VERSION ""

NS_ :

BS_:

BU_: TBOX GW

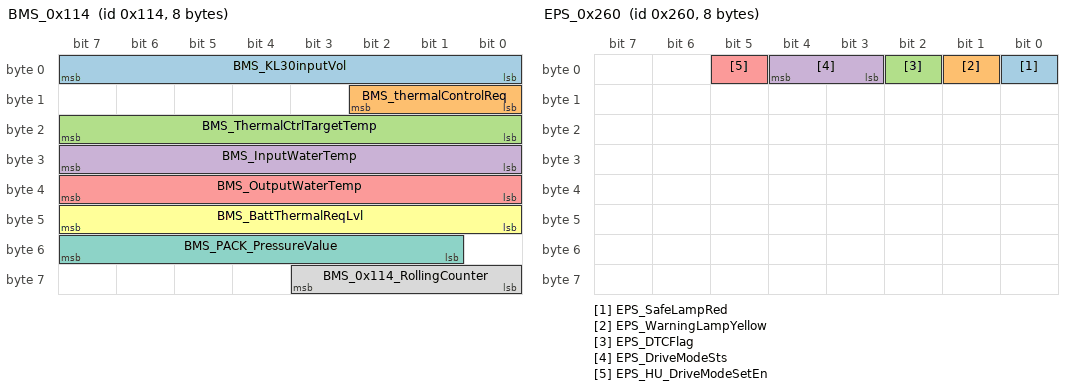
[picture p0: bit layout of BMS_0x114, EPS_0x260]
BO_ 276 BMS_0x114: 8 GW
 SG_ BMS_KL30inputVol : 7|8@0+ (0.1,0) [0|25.5] "V" TBOX
 SG_ BMS_thermalControlReq : 10|3@0+ (1,0) [0|7] "" TBOX
 SG_ BMS_ThermalCtrlTargetTemp : 23|8@0+ (1,-40) [-40|85] "℃" TBOX
 SG_ BMS_InputWaterTemp : 31|8@0+ (0.5,-40) [-40|85] "℃" TBOX
 SG_ BMS_OutputWaterTemp : 39|8@0+ (0.5,-40) [-40|85] "℃" TBOX
 SG_ BMS_BattThermalReqLvl : 47|8@0+ (1,0) [0|15] "" TBOX
 SG_ BMS_PACK_PressureValue : 55|7@0+ (1,50) [50|175] "Kpa" TBOX
 SG_ BMS_0x114_RollingCounter : 59|4@0+ (1,0) [0|15] "" TBOX

BO_ 608 EPS_0x260: 8 GW
 SG_ EPS_SafeLampRed : 0|1@0+ (1,0) [0|1] "" TBOX
 SG_ EPS_WarningLampYellow : 1|1@0+ (1,0) [0|1] "" TBOX
 SG_ EPS_DTCFlag : 2|1@0+ (1,0) [0|1] "" TBOX
 SG_ EPS_DriveModeSts : 4|2@0+ (1,0) [0|3] "" TBOX
 SG_ EPS_HU_DriveModeSetEn : 5|1@0+ (1,0) [0|1] "" TBOX

BO_ 375 EPS_0x177_APS: 8 GW
 SG_ Checksum_0x177 : 7|8@0+ (1,0) [0|255] "" TBOX
 SG_ EPS_EPSAPASts : 19|4@0+ (1,0) [0|15] "" TBOX
 SG_ EPS_EPSAPAInh : 31|8@0+ (1,0) [0|255] "" TBOX
 SG_ Rolling_counter_0x177 : 59|4@0+ (1,0) [0|15] "" TBOX

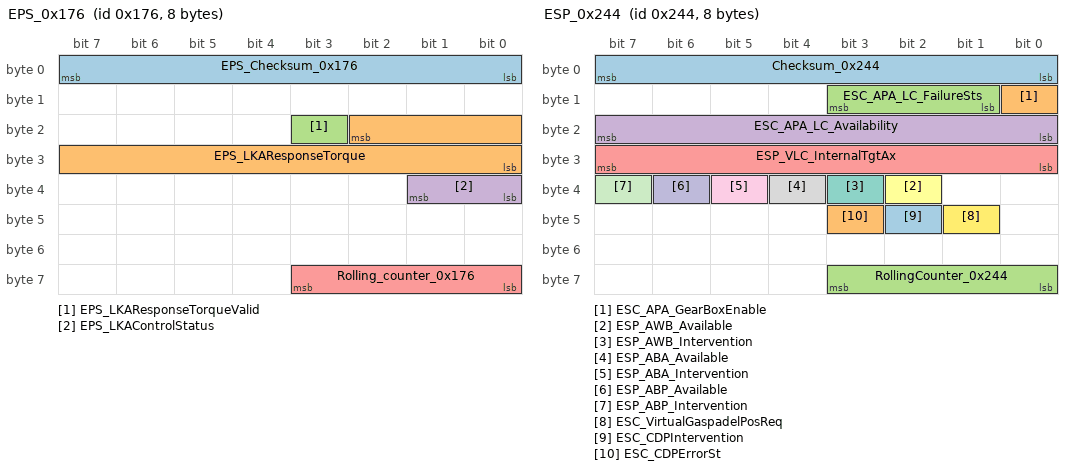
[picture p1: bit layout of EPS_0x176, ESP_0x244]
BO_ 374 EPS_0x176: 8 GW
 SG_ EPS_Checksum_0x176 : 7|8@0+ (1,0) [0|255] "" TBOX
 SG_ EPS_LKAResponseTorque : 18|11@0+ (0.01,-10.24) [-10.24|10.23] "Nm" TBOX
 SG_ EPS_LKAResponseTorqueValid : 19|1@0+ (1,0) [0|1] "" TBOX
 SG_ EPS_LKAControlStatus : 33|2@0+ (1,0) [0|3] "" TBOX
 SG_ Rolling_counter_0x176 : 59|4@0+ (1,0) [0|15] "" TBOX

BO_ 580 ESP_0x244: 8 GW
 SG_ Checksum_0x244 : 7|8@0+ (1,0) [0|255] "" TBOX
 SG_ ESC_APA_GearBoxEnable : 8|1@0+ (1,0) [0|1] "" Vector__XXX
 SG_ ESC_APA_LC_FailureSts : 11|3@0+ (1,0) [0|7] "" TBOX
 SG_ ESC_APA_LC_Availability : 23|8@0+ (1,0) [0|255] "" TBOX
 SG_ ESP_VLC_InternalTgtAx : 31|8@0+ (0.05,-7) [-7|5.75] "m/s2" TBOX
 SG_ ESP_AWB_Available : 34|1@0+ (1,0) [0|1] "" TBOX
 SG_ ESP_AWB_Intervention : 35|1@0+ (1,0) [0|1] "" TBOX
 SG_ ESP_ABA_Available : 36|1@0+ (1,0) [0|1] "" TBOX
 SG_ ESP_ABA_Intervention : 37|1@0+ (1,0) [0|1] "" TBOX
 SG_ ESP_ABP_Available : 38|1@0+ (1,0) [0|1] "" TBOX
 SG_ ESP_ABP_Intervention : 39|1@0+ (1,0) [0|1] "" TBOX
 SG_ ESC_VirtualGaspadelPosReq : 41|1@0+ (1,0) [0|1] "" TBOX
 SG_ ESC_CDPIntervention : 42|1@0+ (1,0) [0|1] "" TBOX
 SG_ ESC_CDPErrorSt : 43|1@0+ (1,0) [0|1] "" TBOX
 SG_ RollingCounter_0x244 : 59|4@0+ (1,0) [0|15] "" TBOX

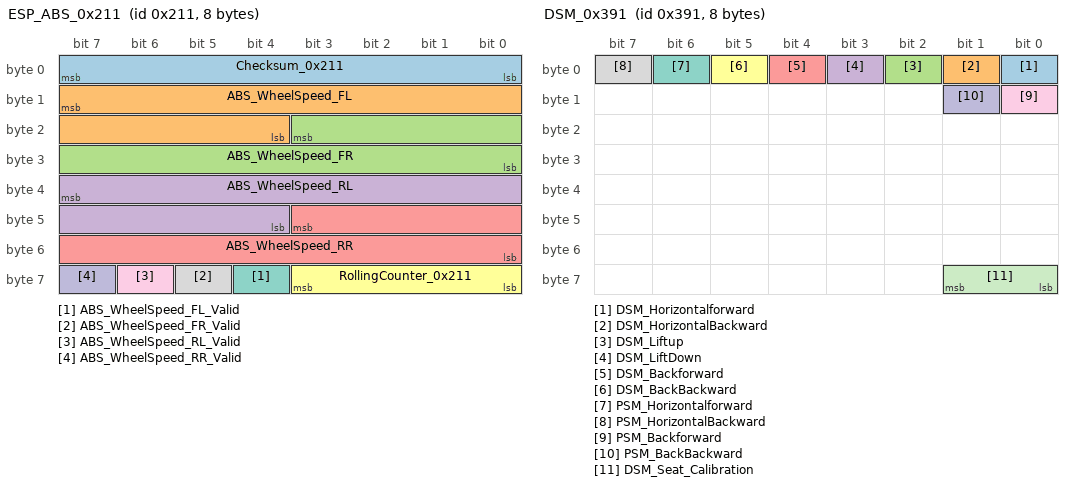
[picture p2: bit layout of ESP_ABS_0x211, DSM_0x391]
BO_ 529 ESP_ABS_0x211: 8 GW
 SG_ Checksum_0x211 : 7|8@0+ (1,0) [0|255] "" TBOX
 SG_ ABS_WheelSpeed_FL : 15|12@0+ (0.05625,0) [0|230.2875] "kph" TBOX
 SG_ ABS_WheelSpeed_FR : 19|12@0+ (0.05625,0) [0|230.2875] "kph" TBOX
 SG_ ABS_WheelSpeed_RL : 39|12@0+ (0.05625,0) [0|230.2875] "kph" TBOX
 SG_ ABS_WheelSpeed_RR : 43|12@0+ (0.05625,0) [0|230.2875] "kph" TBOX
 SG_ RollingCounter_0x211 : 59|4@0+ (1,0) [0|15] "" TBOX
 SG_ ABS_WheelSpeed_FL_Valid : 60|1@0+ (1,0) [0|1] "" TBOX
 SG_ ABS_WheelSpeed_FR_Valid : 61|1@0+ (1,0) [0|1] "" TBOX
 SG_ ABS_WheelSpeed_RL_Valid : 62|1@0+ (1,0) [0|1] "" TBOX
 SG_ ABS_WheelSpeed_RR_Valid : 63|1@0+ (1,0) [0|1] "" TBOX

BO_ 913 DSM_0x391: 8 GW
 SG_ DSM_Horizontalforward : 0|1@0+ (1,0) [0|1] "" TBOX
 SG_ DSM_HorizontalBackward : 1|1@0+ (1,0) [0|1] "" TBOX
 SG_ DSM_Liftup : 2|1@0+ (1,0) [0|1] "" TBOX
 SG_ DSM_LiftDown : 3|1@0+ (1,0) [0|1] "" TBOX
 SG_ DSM_Backforward : 4|1@0+ (1,0) [0|1] "" TBOX
 SG_ DSM_BackBackward : 5|1@0+ (1,0) [0|1] "" TBOX
 SG_ PSM_Horizontalforward : 6|1@0+ (1,0) [0|1] "" TBOX
 SG_ PSM_HorizontalBackward : 7|1@0+ (1,0) [0|1] "" TBOX
 SG_ PSM_Backforward : 8|1@0+ (1,0) [0|1] "" TBOX
 SG_ PSM_BackBackward : 9|1@0+ (1,0) [0|1] "" TBOX
 SG_ DSM_Seat_Calibration : 57|2@0+ (1,0) [0|3] "" TBOX

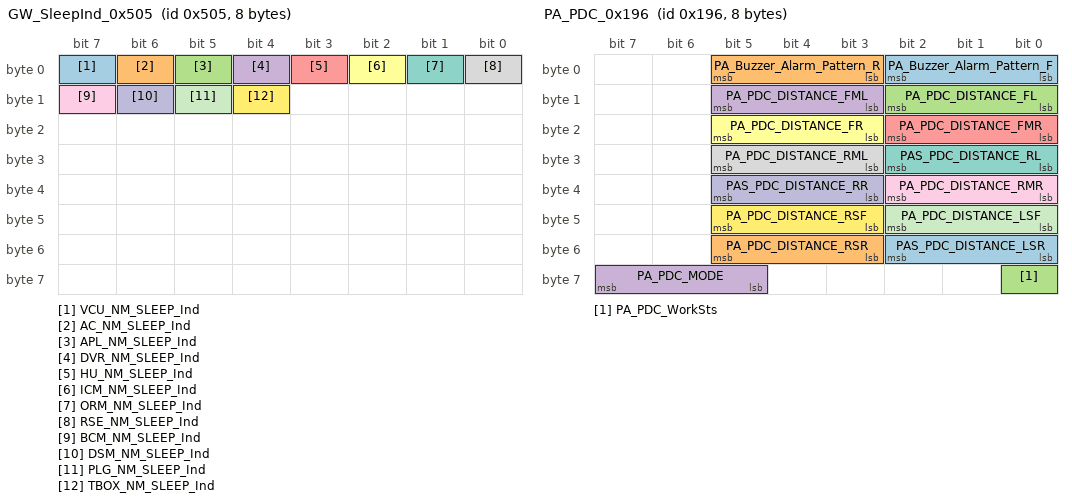
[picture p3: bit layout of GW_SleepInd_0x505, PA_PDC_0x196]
BO_ 1285 GW_SleepInd_0x505: 8 GW
 SG_ VCU_NM_SLEEP_Ind : 7|1@0+ (1,0) [0|1] "" TBOX
 SG_ AC_NM_SLEEP_Ind : 6|1@0+ (1,0) [0|1] "" TBOX
 SG_ APL_NM_SLEEP_Ind : 5|1@0+ (1,0) [0|1] "" TBOX
 SG_ DVR_NM_SLEEP_Ind : 4|1@0+ (1,0) [0|1] "" TBOX
 SG_ HU_NM_SLEEP_Ind : 3|1@0+ (1,0) [0|1] "" TBOX
 SG_ ICM_NM_SLEEP_Ind : 2|1@0+ (1,0) [0|1] "" TBOX
 SG_ ORM_NM_SLEEP_Ind : 1|1@0+ (1,0) [0|1] "" TBOX
 SG_ RSE_NM_SLEEP_Ind : 0|1@0+ (1,0) [0|1] "" TBOX
 SG_ BCM_NM_SLEEP_Ind : 15|1@0+ (1,0) [0|1] "" TBOX
 SG_ DSM_NM_SLEEP_Ind : 14|1@0+ (1,0) [0|1] "" TBOX
 SG_ PLG_NM_SLEEP_Ind : 13|1@0+ (1,0) [0|1] "" TBOX
 SG_ TBOX_NM_SLEEP_Ind : 12|1@0+ (1,0) [0|1] "" TBOX

BO_ 406 PA_PDC_0x196: 8 GW
 SG_ PA_Buzzer_Alarm_Pattern_F : 2|3@0+ (1,0) [0|7] "" TBOX
 SG_ PA_Buzzer_Alarm_Pattern_R : 5|3@0+ (1,0) [0|7] "" TBOX
 SG_ PA_PDC_DISTANCE_FL : 10|3@0+ (1,0) [0|7] "" TBOX
 SG_ PA_PDC_DISTANCE_FML : 13|3@0+ (1,0) [0|7] "" TBOX
 SG_ PA_PDC_DISTANCE_FMR : 18|3@0+ (1,0) [0|7] "" TBOX
 SG_ PA_PDC_DISTANCE_FR : 21|3@0+ (1,0) [0|7] "" TBOX
 SG_ PAS_PDC_DISTANCE_RL : 26|3@0+ (1,0) [0|7] "" TBOX
 SG_ PA_PDC_DISTANCE_RML : 29|3@0+ (1,0) [0|7] "" TBOX
 SG_ PA_PDC_DISTANCE_RMR : 34|3@0+ (1,0) [0|7] "" TBOX
 SG_ PAS_PDC_DISTANCE_RR : 37|3@0+ (1,0) [0|7] "" TBOX
 SG_ PA_PDC_DISTANCE_LSF : 42|3@0+ (1,0) [0|7] "" TBOX
 SG_ PA_PDC_DISTANCE_RSF : 45|3@0+ (1,0) [0|7] "" TBOX
 SG_ PAS_PDC_DISTANCE_LSR : 50|3@0+ (1,0) [0|7] "" TBOX
 SG_ PA_PDC_DISTANCE_RSR : 53|3@0+ (1,0) [0|7] "" TBOX
 SG_ PA_PDC_WorkSts : 56|1@0+ (1,0) [0|1] "" TBOX
 SG_ PA_PDC_MODE : 63|3@0+ (1,0) [0|7] "" TBOX

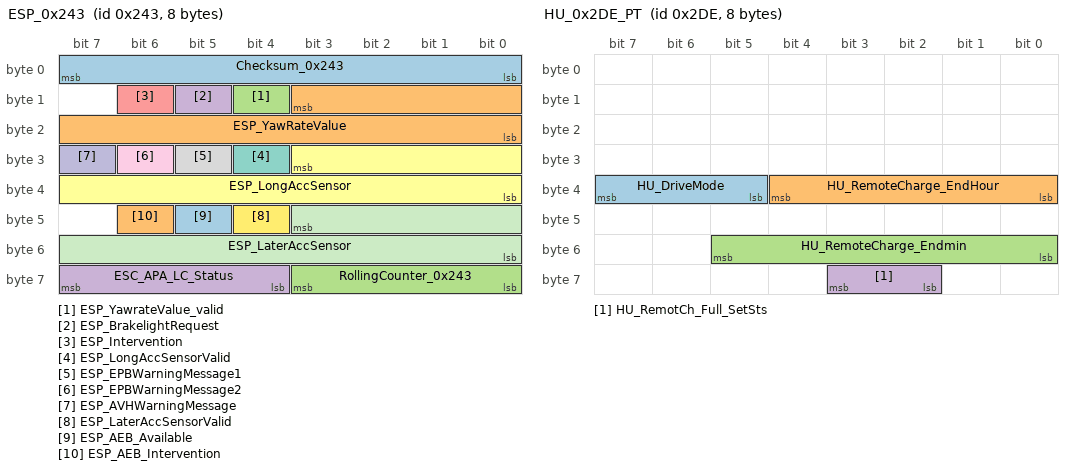
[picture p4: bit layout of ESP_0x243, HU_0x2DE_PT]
BO_ 579 ESP_0x243: 8 GW
 SG_ Checksum_0x243 : 7|8@0+ (1,0) [0|255] "" TBOX
 SG_ ESP_YawRateValue : 11|12@0+ (0.05,-75) [-75|75] "°/s" TBOX
 SG_ ESP_YawrateValue_valid : 12|1@0+ (1,0) [0|1] "" TBOX
 SG_ ESP_BrakelightRequest : 13|1@0+ (1,0) [0|1] "" TBOX
 SG_ ESP_Intervention : 14|1@0+ (1,0) [0|1] "" TBOX
 SG_ ESP_LongAccSensor : 27|12@0+ (0.01,-20) [-20|20] "m/s^2" TBOX
 SG_ ESP_LongAccSensorValid : 28|1@0+ (1,0) [0|1] "" TBOX
 SG_ ESP_EPBWarningMessage1 : 29|1@0+ (1,0) [0|1] "" TBOX
 SG_ ESP_EPBWarningMessage2 : 30|1@0+ (1,0) [0|1] "" TBOX
 SG_ ESP_AVHWarningMessage : 31|1@0+ (1,0) [0|1] "" TBOX
 SG_ ESP_LaterAccSensor : 43|12@0+ (0.01,-20) [-20|20] "m/s^2" TBOX
 SG_ ESP_LaterAccSensorValid : 44|1@0+ (1,0) [0|1] "" TBOX
 SG_ ESP_AEB_Available : 45|1@0+ (1,0) [0|1] "" TBOX
 SG_ ESP_AEB_Intervention : 46|1@0+ (1,0) [0|1] "" TBOX
 SG_ RollingCounter_0x243 : 59|4@0+ (1,0) [0|15] "" TBOX
 SG_ ESC_APA_LC_Status : 63|4@0+ (1,0) [0|15] "" TBOX

BO_ 734 HU_0x2DE_PT: 8 GW
 SG_ HU_DriveMode : 39|3@0+ (1,0) [0|7] "" TBOX
 SG_ HU_RemoteCharge_EndHour : 36|5@0+ (1,0) [0|23] "hour" TBOX
 SG_ HU_RemoteCharge_Endmin : 53|6@0+ (1,0) [0|59] "min" TBOX
 SG_ HU_RemotCh_Full_SetSts : 59|2@0+ (1,0) [0|3] "" TBOX

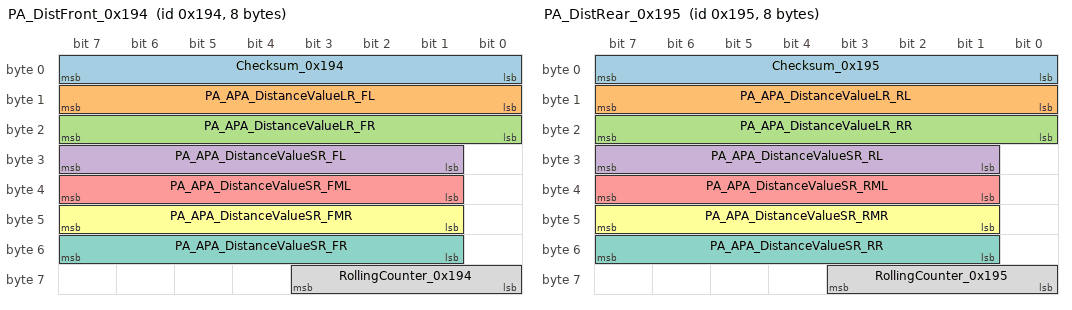
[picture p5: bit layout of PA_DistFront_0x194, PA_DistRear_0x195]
BO_ 404 PA_DistFront_0x194: 8 GW
 SG_ Checksum_0x194 : 7|8@0+ (1,0) [0|255] "" TBOX
 SG_ PA_APA_DistanceValueLR_FL : 15|8@0+ (2,0) [0|500] "cm" TBOX
 SG_ PA_APA_DistanceValueLR_FR : 23|8@0+ (2,0) [0|500] "cm" TBOX
 SG_ PA_APA_DistanceValueSR_FL : 31|7@0+ (2,0) [0|250] "cm" TBOX
 SG_ PA_APA_DistanceValueSR_FML : 39|7@0+ (2,0) [0|250] "cm" TBOX
 SG_ PA_APA_DistanceValueSR_FMR : 47|7@0+ (2,0) [0|250] "cm" TBOX
 SG_ PA_APA_DistanceValueSR_FR : 55|7@0+ (2,0) [0|250] "cm" TBOX
 SG_ RollingCounter_0x194 : 59|4@0+ (1,0) [0|15] "" TBOX

BO_ 405 PA_DistRear_0x195: 8 GW
 SG_ Checksum_0x195 : 7|8@0+ (1,0) [0|255] "" TBOX
 SG_ PA_APA_DistanceValueLR_RL : 15|8@0+ (2,0) [0|500] "cm" TBOX
 SG_ PA_APA_DistanceValueLR_RR : 23|8@0+ (2,0) [0|500] "cm" TBOX
 SG_ PA_APA_DistanceValueSR_RL : 31|7@0+ (2,0) [0|250] "cm" TBOX
 SG_ PA_APA_DistanceValueSR_RML : 39|7@0+ (2,0) [0|250] "cm" TBOX
 SG_ PA_APA_DistanceValueSR_RMR : 47|7@0+ (2,0) [0|250] "cm" TBOX
 SG_ PA_APA_DistanceValueSR_RR : 55|7@0+ (2,0) [0|250] "cm" TBOX
 SG_ RollingCounter_0x195 : 59|4@0+ (1,0) [0|15] "" TBOX

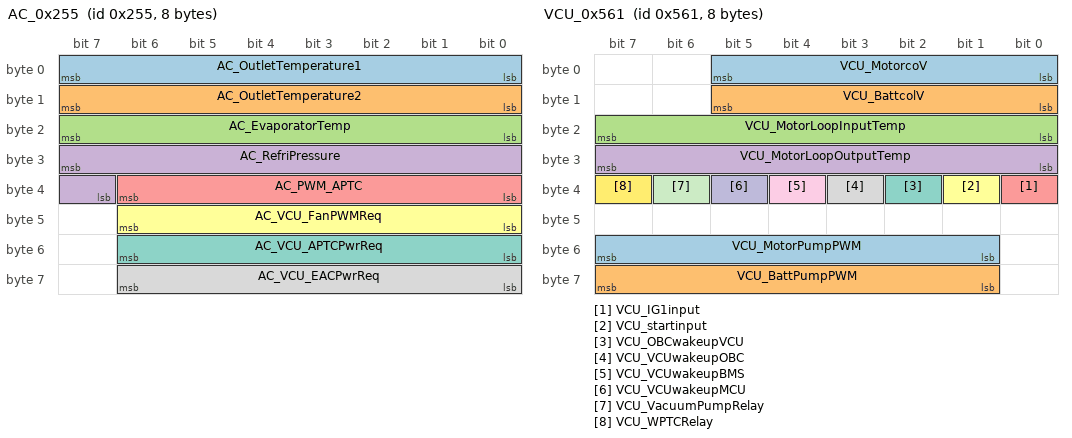
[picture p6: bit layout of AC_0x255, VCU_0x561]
BO_ 597 AC_0x255: 8 GW
 SG_ AC_OutletTemperature1 : 7|8@0+ (0.5,-40) [-40|80] "℃" TBOX
 SG_ AC_OutletTemperature2 : 15|8@0+ (0.5,-40) [-40|80] "℃" TBOX
 SG_ AC_EvaporatorTemp : 23|8@0+ (0.5,-40) [-40|80] "℃" TBOX
 SG_ AC_RefriPressure : 31|9@0+ (0.01,0) [0.1|3.5] "MPa" TBOX
 SG_ AC_PWM_APTC : 38|7@0+ (1,0) [0|100] "%" TBOX
 SG_ AC_VCU_FanPWMReq : 46|7@0+ (1,0) [0|100] "%" TBOX
 SG_ AC_VCU_APTCPwrReq : 54|7@0+ (0.1,0) [0|12.7] "" TBOX
 SG_ AC_VCU_EACPwrReq : 62|7@0+ (0.1,0) [0|12.7] "" TBOX

BO_ 64 BCM_PEPS_0x40: 8 GW
 SG_ PEPS_RKECommand : 3|4@0+ (1,0) [0|15] "" TBOX
 SG_ PEPS_DoorUnlockReq : 6|2@0+ (1,0) [0|3] "" TBOX
 SG_ PEPS_DoorlockReq : 9|2@0+ (1,0) [0|3] "" TBOX
 SG_ PEPS_TrunkReleaseReq : 4|1@0+ (1,0) [0|1] "" TBOX

BO_ 1377 VCU_0x561: 8 GW
 SG_ VCU_MotorcoV : 5|6@0+ (0.1,0) [0|6.3] "V" TBOX
 SG_ VCU_BattcolV : 13|6@0+ (0.1,0) [0|6.3] "V" TBOX
 SG_ VCU_MotorLoopInputTemp : 23|8@0+ (1,-40) [-40|215] "℃" TBOX
 SG_ VCU_MotorLoopOutputTemp : 31|8@0+ (1,-40) [-40|215] "℃" TBOX
 SG_ VCU_IG1input : 32|1@0+ (1,0) [0|1] "" TBOX
 SG_ VCU_startinput : 33|1@0+ (1,0) [0|1] "" TBOX
 SG_ VCU_OBCwakeupVCU : 34|1@0+ (1,0) [0|1] "" TBOX
 SG_ VCU_VCUwakeupOBC : 35|1@0+ (1,0) [0|1] "" TBOX
 SG_ VCU_VCUwakeupBMS : 36|1@0+ (1,0) [0|1] "" TBOX
 SG_ VCU_VCUwakeupMCU : 37|1@0+ (1,0) [0|1] "" TBOX
 SG_ VCU_VacuumPumpRelay : 38|1@0+ (1,0) [0|1] "" TBOX
 SG_ VCU_WPTCRelay : 39|1@0+ (1,0) [0|1] "" TBOX
 SG_ VCU_MotorPumpPWM : 55|7@0+ (1,0) [0|100] "%" TBOX
 SG_ VCU_BattPumpPWM : 63|7@0+ (1,0) [0|100] "%" TBOX

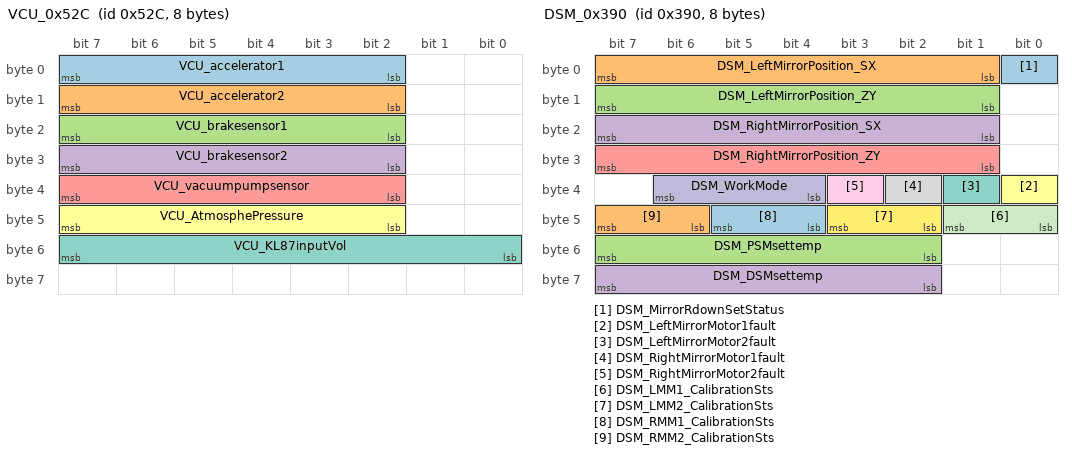
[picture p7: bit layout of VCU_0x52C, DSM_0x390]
BO_ 1324 VCU_0x52C: 8 GW
 SG_ VCU_accelerator1 : 7|6@0+ (0.1,0) [0|6.3] "V" TBOX
 SG_ VCU_accelerator2 : 15|6@0+ (0.1,0) [0|6.3] "V" TBOX
 SG_ VCU_brakesensor1 : 23|6@0+ (0.1,0) [0|6.3] "V" TBOX
 SG_ VCU_brakesensor2 : 31|6@0+ (0.1,0) [0|6.3] "V" TBOX
 SG_ VCU_vacuumpumpsensor : 39|6@0+ (0.1,0) [0|6.3] "V" TBOX
 SG_ VCU_AtmosphePressure : 47|6@0+ (0.1,0) [0|6.3] "V" TBOX
 SG_ VCU_KL87inputVol : 55|8@0+ (0.1,0) [0|25.4] "V" TBOX

BO_ 912 DSM_0x390: 8 GW
 SG_ DSM_MirrorRdownSetStatus : 0|1@0+ (1,0) [0|1] "" TBOX
 SG_ DSM_LeftMirrorPosition_SX : 7|7@0+ (1,0) [0|100] "%" TBOX
 SG_ DSM_LeftMirrorPosition_ZY : 15|7@0+ (1,0) [0|100] "%" TBOX
 SG_ DSM_RightMirrorPosition_SX : 23|7@0+ (1,0) [0|100] "%" TBOX
 SG_ DSM_RightMirrorPosition_ZY : 31|7@0+ (1,0) [0|100] "%" TBOX
 SG_ DSM_LeftMirrorMotor1fault : 32|1@0+ (1,0) [0|1] "" TBOX
 SG_ DSM_LeftMirrorMotor2fault : 33|1@0+ (1,0) [0|1] "" TBOX
 SG_ DSM_RightMirrorMotor1fault : 34|1@0+ (1,0) [0|1] "" TBOX
 SG_ DSM_RightMirrorMotor2fault : 35|1@0+ (1,0) [0|1] "" TBOX
 SG_ DSM_WorkMode : 38|3@0+ (1,0) [0|7] "" TBOX
 SG_ DSM_LMM1_CalibrationSts : 41|2@0+ (1,0) [0|3] "" TBOX
 SG_ DSM_LMM2_CalibrationSts : 43|2@0+ (1,0) [0|3] "" TBOX
 SG_ DSM_RMM1_CalibrationSts : 45|2@0+ (1,0) [0|3] "" TBOX
 SG_ DSM_RMM2_CalibrationSts : 47|2@0+ (1,0) [0|3] "" TBOX
 SG_ DSM_PSMsettemp : 55|6@0+ (1,0) [34|42] "℃" TBOX
 SG_ DSM_DSMsettemp : 63|6@0+ (1,0) [34|42] "℃" TBOX

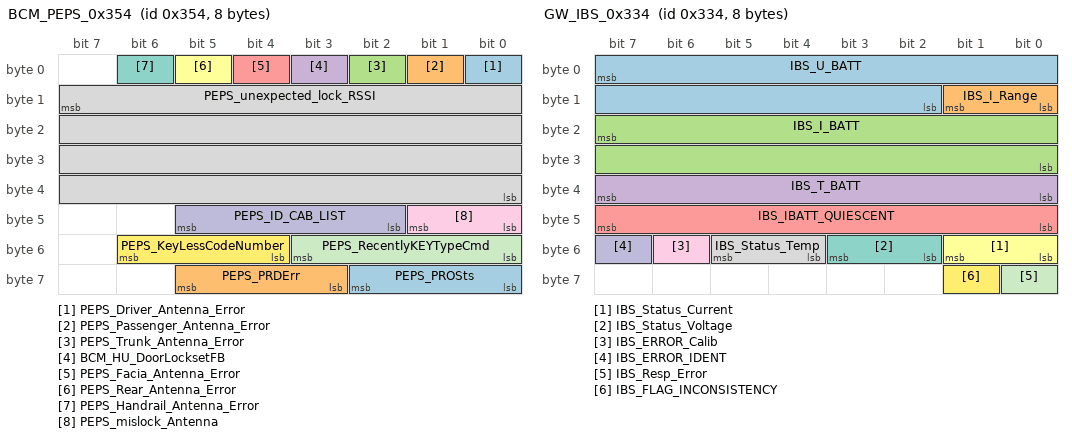
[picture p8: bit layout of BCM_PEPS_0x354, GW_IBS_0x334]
BO_ 852 BCM_PEPS_0x354: 8 GW
 SG_ PEPS_Driver_Antenna_Error : 0|1@0+ (1,0) [0|1] "" TBOX
 SG_ PEPS_Passenger_Antenna_Error : 1|1@0+ (1,0) [0|1] "" TBOX
 SG_ PEPS_Trunk_Antenna_Error : 2|1@0+ (1,0) [0|1] "" TBOX
 SG_ BCM_HU_DoorLocksetFB : 3|1@0+ (1,0) [0|1] "" TBOX
 SG_ PEPS_Facia_Antenna_Error : 4|1@0+ (1,0) [0|1] "" TBOX
 SG_ PEPS_Rear_Antenna_Error : 5|1@0+ (1,0) [0|1] "" TBOX
 SG_ PEPS_Handrail_Antenna_Error : 6|1@0+ (1,0) [0|1] "" TBOX
 SG_ PEPS_unexpected_lock_RSSI : 15|32@0+ (1,0) [0|4294967294] "" TBOX
 SG_ PEPS_mislock_Antenna : 41|2@0+ (1,0) [0|3] "" TBOX
 SG_ PEPS_ID_CAB_LIST : 45|4@0+ (1,0) [0|15] "" TBOX
 SG_ PEPS_RecentlyKEYTypeCmd : 51|4@0+ (1,0) [0|15] "" TBOX
 SG_ PEPS_KeyLessCodeNumber : 54|3@0+ (1,0) [0|7] "" TBOX
 SG_ PEPS_PROSts : 58|3@0+ (1,0) [0|1] "" TBOX
 SG_ PEPS_PRDErr : 61|3@0+ (1,0) [0|1] "" TBOX

BO_ 546 BCM_PEPS_0x222: 8 GW
 SG_ PEPS_PEPSFailStatus : 0|1@0+ (1,0) [0|1] "" TBOX
 SG_ PEPS_WarningKeyNotInCar : 1|1@0+ (1,0) [0|1] "" TBOX
 SG_ PEPS_WarningKeyInCar : 2|1@0+ (1,0) [0|1] "" TBOX
 SG_ PEPS_WarningIgNotOff : 3|1@0+ (1,0) [0|1] "" TBOX
 SG_ PEPS_WarningKeyLowBattery : 4|1@0+ (1,0) [0|1] "" TBOX
 SG_ PEPS_WarningStartupNotBrake : 5|1@0+ (1,0) [0|1] "" TBOX
 SG_ PEPS_WarningKeyNearbyIMMO : 7|1@0+ (1,0) [0|1] "" TBOX
 SG_ PEPS_PassiveWindowCom : 8|1@0+ (1,0) [0|1] "" TBOX
 SG_ PEPS_BackDoorKeyState : 10|2@0+ (1,0) [0|3] "" TBOX
 SG_ PEPS_KeyPosition : 12|2@0+ (1,0) [0|3] "" TBOX
 SG_ PEPS_HandshakeFail : 18|3@0+ (1,0) [0|7] "" TBOX
 SG_ PEPS_Authpasstype : 25|2@0+ (1,0) [0|3] "" TBOX
 SG_ PEPS_EnableWirelessCharging : 26|1@0+ (1,0) [0|1] "" TBOX
 SG_ PEPS_DHA_LeftHandleSwitch : 33|2@0+ (1,0) [0|3] "" TBOX
 SG_ PEPS_PHA_RightHandleSwitch : 35|2@0+ (1,0) [0|3] "" TBOX
 SG_ DHA_LockFlag : 47|8@0+ (1,0) [0|255] "" TBOX
 SG_ PHA_LockFlag : 55|8@0+ (1,0) [0|255] "" TBOX

BO_ 820 GW_IBS_0x334: 8 GW
 SG_ IBS_U_BATT : 7|14@0+ (0.0009765625,3) [3|18] "V" TBOX
 SG_ IBS_I_Range : 9|2@0+ (1,0) [0|3] "" TBOX
 SG_ IBS_I_BATT : 23|16@0+ (1,-32768) [-32768|32766] "A" TBOX
 SG_ IBS_T_BATT : 39|8@0+ (1,-40) [-40|105] "°C" TBOX
 SG_ IBS_IBATT_QUIESCENT : 47|8@0+ (0.00390625,0) [0|0.984375] "A" TBOX
 SG_ IBS_Status_Current : 49|2@0+ (1,0) [0|3] "" TBOX
 SG_ IBS_Status_Voltage : 51|2@0+ (1,0) [0|3] "" TBOX
 SG_ IBS_Status_Temp : 53|2@0+ (1,0) [0|3] "" TBOX
 SG_ IBS_ERROR_Calib : 54|1@0+ (1,0) [0|1] "" TBOX
 SG_ IBS_ERROR_IDENT : 55|1@0+ (1,0) [0|1] "" TBOX
 SG_ IBS_Resp_Error : 56|1@0+ (1,0) [0|1] "" TBOX
 SG_ IBS_FLAG_INCONSISTENCY : 57|1@0+ (1,0) [0|1] "" TBOX

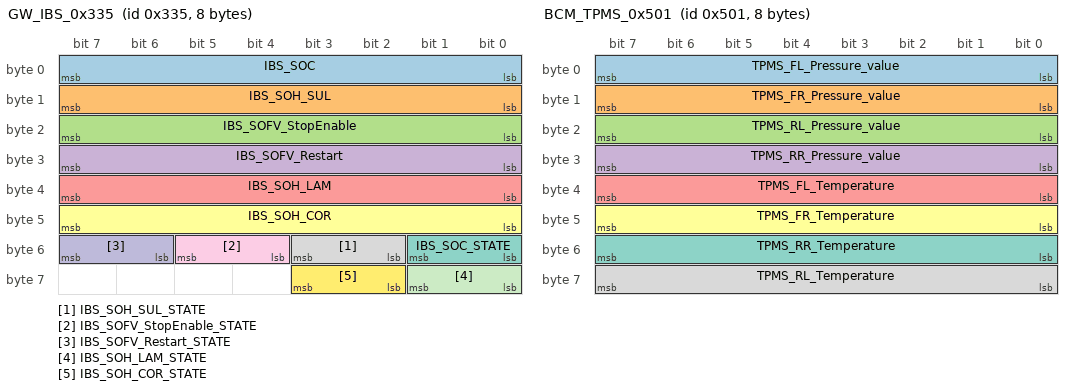
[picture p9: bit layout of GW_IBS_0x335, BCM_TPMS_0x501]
BO_ 821 GW_IBS_0x335: 8 GW
 SG_ IBS_SOC : 7|8@0+ (1,0) [0|100] "%" TBOX
 SG_ IBS_SOH_SUL : 15|8@0+ (1,0) [0|100] "%" TBOX
 SG_ IBS_SOFV_StopEnable : 23|8@0+ (0.0625,0) [0|15.875] "V" TBOX
 SG_ IBS_SOFV_Restart : 31|8@0+ (0.0625,0) [0|15.875] "V" TBOX
 SG_ IBS_SOH_LAM : 39|8@0+ (0.5,0) [0|127] "Ah" TBOX
 SG_ IBS_SOH_COR : 47|8@0+ (0.0625,0) [0|15.875] "V" TBOX
 SG_ IBS_SOC_STATE : 49|2@0+ (1,0) [0|3] "" TBOX
 SG_ IBS_SOH_SUL_STATE : 51|2@0+ (1,0) [0|3] "" TBOX
 SG_ IBS_SOFV_StopEnable_STATE : 53|2@0+ (1,0) [0|3] "" TBOX
 SG_ IBS_SOFV_Restart_STATE : 55|2@0+ (1,0) [0|3] "" TBOX
 SG_ IBS_SOH_LAM_STATE : 57|2@0+ (1,0) [0|3] "" TBOX
 SG_ IBS_SOH_COR_STATE : 59|2@0+ (1,0) [0|3] "" TBOX

BO_ 933 HU_0x3A5: 8 GW
 SG_ HU_LanguageSet : 3|4@0+ (1,0) [0|15] "" TBOX
 SG_ HU_TimeSet_DisplayMode : 4|1@0+ (1,0) [0|1] "" TBOX
 SG_ HU_TimeSet_AutoMode : 5|1@0+ (1,0) [0|1] "" TBOX
 SG_ HU_TBOXwelcomeReq_set : 7|2@0+ (1,0) [0|3] "" TBOX
 SG_ HU_TimeSet_Hour : 12|5@0+ (1,0) [0|31] "" TBOX
 SG_ HU_MCUPowerState : 15|3@0+ (1,0) [0|7] "" TBOX
 SG_ HU_TimeSet_Minutes : 21|6@0+ (1,0) [0|60] "" TBOX
 SG_ HU_SOCResetType : 22|1@0+ (1,0) [0|1] "" TBOX
 SG_ HU_HardACCState : 23|1@0+ (1,0) [0|1] "" TBOX
 SG_ HU_TBOX_Reboot : 25|2@0+ (1,0) [0|3] "" TBOX
 SG_ HU_mute_activests : 26|1@0+ (1,0) [0|1] "" TBOX
 SG_ HU_Voicecontrol_activests : 27|1@0+ (1,0) [0|1] "" TBOX
 SG_ HU_SOCWatchdog : 28|1@0+ (1,0) [0|1] "" TBOX
 SG_ HU_phonecall_worksts : 29|1@0+ (1,0) [0|1] "" TBOX
 SG_ HU_ICM_INFO_Enable : 31|2@0+ (1,0) [0|3] "" TBOX
 SG_ HU_BCMSystemPowerMode : 33|2@0+ (1,0) [0|3] "" TBOX
 SG_ HU_RemoteCharge_StartHour : 39|5@0+ (1,0) [0|23] "" TBOX
 SG_ HU_RemoteCharge_Startmin : 45|6@0+ (1,0) [0|59] "" TBOX
 SG_ HU_RemoteCharge_Set : 47|2@0+ (1,0) [0|3] "" TBOX
 SG_ HU_ChargeCtrl_Set : 49|2@0+ (1,0) [0|3] "" TBOX
 SG_ HU_BatteryVoltage : 55|5@0+ (1,0) [0|25] "" TBOX
 SG_ HU_SPIConnectState : 56|1@0+ (1,0) [0|1] "" TBOX
 SG_ HU_MCUResetReason : 63|7@0+ (2,0) [0|127] "" TBOX

BO_ 816 BCM_0x330: 8 GW
 SG_ BCM_reversingLampSW : 0|1@0+ (1,0) [0|1] "" TBOX
 SG_ BCM_CarpetlampSW : 3|1@0+ (1,0) [0|1] "" TBOX
 SG_ BCM_CarpetlampSWSetsts : 4|1@0+ (1,0) [0|1] "" TBOX
 SG_ BCM_FrontdecoralampSW : 7|1@0+ (1,0) [0|1] "" TBOX
 SG_ BCM_LeftReadlampControl : 9|1@0+ (1,0) [0|1] "" TBOX
 SG_ BCM_RightReadlampControl : 11|1@0+ (1,0) [0|1] "" TBOX
 SG_ BCM_FloodlightControl : 13|1@0+ (1,0) [0|1] "" TBOX
 SG_ BCM_DomeLampDoorControl : 15|1@0+ (1,0) [0|1] "" TBOX
 SG_ BCM_LockWelcomeSts : 17|2@0+ (1,0) [0|3] "" TBOX
 SG_ BCM_PEPSLockReason : 20|3@0+ (1,0) [0|7] "" TBOX
 SG_ BCM_PEPSUnLockReason : 23|3@0+ (1,0) [0|7] "" TBOX
 SG_ BCM_FollowMeControlsts : 27|1@0+ (1,0) [0|1] "" TBOX
 SG_ BCM_FollowMeDelayTSetsts : 29|2@0+ (1,0) [0|3] "" TBOX
 SG_ BCM_AutoLockSetsts : 31|1@0+ (1,0) [0|1] "" TBOX
 SG_ BCM_WindowAutoUPSetsts : 33|1@0+ (1,0) [0|1] "" TBOX
 SG_ BCM_FL_LED_Error : 34|1@0+ (1,0) [0|1] "" TBOX
 SG_ BCM_FR_LED_Error : 35|1@0+ (1,0) [0|1] "" TBOX
 SG_ BCM_RL_LED_Error : 36|1@0+ (1,0) [0|1] "" TBOX
 SG_ BCM_RR_LED_Error : 37|1@0+ (1,0) [0|1] "" TBOX
 SG_ BCM_LockReason : 50|3@0+ (1,0) [0|7] "" TBOX
 SG_ BCM_UnLockReason : 53|3@0+ (1,0) [0|7] "" TBOX
 SG_ BCM_CSW_SSB_inputSts : 54|1@0+ (1,0) [0|1] "" TBOX
 SG_ BCM_ACU_Crash_inputsts : 55|1@0+ (1,0) [0|1] "" TBOX
 SG_ BCM_ESCL_UnlockFB_inputsts : 56|1@0+ (1,0) [0|1] "" TBOX
 SG_ BCM_ESCL_Motorpower_outputsts : 57|1@0+ (1,0) [0|1] "" TBOX
 SG_ BCM_ESCL_LockEnable_outputsts : 58|1@0+ (1,0) [0|1] "" TBOX
 SG_ BCM_ESCL_UnLockfail : 59|1@0+ (1,0) [0|1] "" TBOX
 SG_ BCM_ESCL_Lockfail : 60|1@0+ (1,0) [0|1] "" TBOX
 SG_ BCM_waterlightlimit : 61|1@0+ (1,0) [0|1] "" TBOX

BO_ 961 TBOX_0x3C1: 8 TBOX
 SG_ Tbox_ICM_ODOTotal : 7|24@0+ (1,0) [0|999999] "KM" GW
 SG_ Tbox_ICM_Prevmaintmileage : 31|24@0+ (1,0) [0|999999] "KM" GW

BO_ 1281 BCM_TPMS_0x501: 8 GW
 SG_ TPMS_FL_Pressure_value : 7|8@0+ (1.373,0) [0|348.742] "kPa" TBOX
 SG_ TPMS_FR_Pressure_value : 15|8@0+ (1.373,0) [0|348.742] "kPa" TBOX
 SG_ TPMS_RL_Pressure_value : 23|8@0+ (1.373,0) [0|348.742] "kPa" TBOX
 SG_ TPMS_RR_Pressure_value : 31|8@0+ (1.373,0) [0|348.742] "kPa" TBOX
 SG_ TPMS_FL_Temperature : 39|8@0+ (1,-60) [-60|194] "℃" TBOX
 SG_ TPMS_FR_Temperature : 47|8@0+ (1,-60) [-60|194] "℃" TBOX
 SG_ TPMS_RR_Temperature : 55|8@0+ (1,-60) [-60|194] "℃" TBOX
 SG_ TPMS_RL_Temperature : 63|8@0+ (1,-60) [-60|194] "℃" TBOX

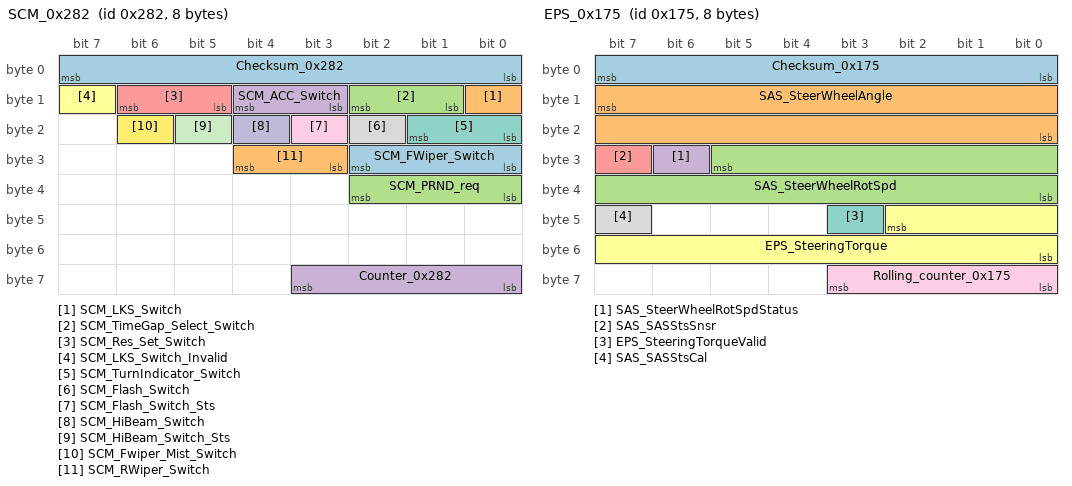
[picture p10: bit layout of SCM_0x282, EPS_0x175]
BO_ 642 SCM_0x282: 8 GW
 SG_ Checksum_0x282 : 7|8@0+ (1,0) [0|255] "" TBOX
 SG_ SCM_LKS_Switch : 8|1@0+ (1,0) [0|1] "" TBOX
 SG_ SCM_TimeGap_Select_Switch : 10|2@0+ (1,0) [0|3] "" TBOX
 SG_ SCM_ACC_Switch : 12|2@0+ (1,0) [0|3] "" TBOX
 SG_ SCM_Res_Set_Switch : 14|2@0+ (1,0) [0|3] "" TBOX
 SG_ SCM_LKS_Switch_Invalid : 15|1@0+ (1,0) [0|1] "" TBOX
 SG_ SCM_TurnIndicator_Switch : 17|2@0+ (1,0) [0|3] "" TBOX
 SG_ SCM_Flash_Switch : 18|1@0+ (1,0) [0|1] "" TBOX
 SG_ SCM_Flash_Switch_Sts : 19|1@0+ (1,0) [0|1] "" TBOX
 SG_ SCM_HiBeam_Switch : 20|1@0+ (1,0) [0|1] "" TBOX
 SG_ SCM_HiBeam_Switch_Sts : 21|1@0+ (1,0) [0|1] "" TBOX
 SG_ SCM_Fwiper_Mist_Switch : 22|1@0+ (1,0) [0|1] "" TBOX
 SG_ SCM_FWiper_Switch : 26|3@0+ (1,0) [0|7] "" TBOX
 SG_ SCM_RWiper_Switch : 28|2@0+ (1,0) [0|3] "" TBOX
 SG_ SCM_PRND_req : 34|3@0+ (1,0) [0|7] "" TBOX
 SG_ Counter_0x282 : 59|4@0+ (1,0) [0|15] "" TBOX

BO_ 373 EPS_0x175: 8 GW
 SG_ Checksum_0x175 : 7|8@0+ (1,0) [0|255] "" TBOX
 SG_ SAS_SteerWheelAngle : 15|16@0+ (0.0238,-780) [-780|779.733] "deg" TBOX
 SG_ SAS_SteerWheelRotSpd : 29|14@0+ (0.125,-1024) [-1024|1023.75] "deg/s" TBOX
 SG_ SAS_SteerWheelRotSpdStatus : 30|1@0+ (1,0) [0|1] "" TBOX
 SG_ SAS_SASStsSnsr : 31|1@0+ (1,0) [0|1] "" TBOX
 SG_ EPS_SteeringTorque : 42|11@0+ (0.01,-10.24) [-10.24|10.23] "Nm" TBOX
 SG_ EPS_SteeringTorqueValid : 43|1@0+ (1,0) [0|1] "" TBOX
 SG_ SAS_SASStsCal : 47|1@0+ (1,0) [0|1] "" TBOX
 SG_ Rolling_counter_0x175 : 59|4@0+ (1,0) [0|15] "" TBOX

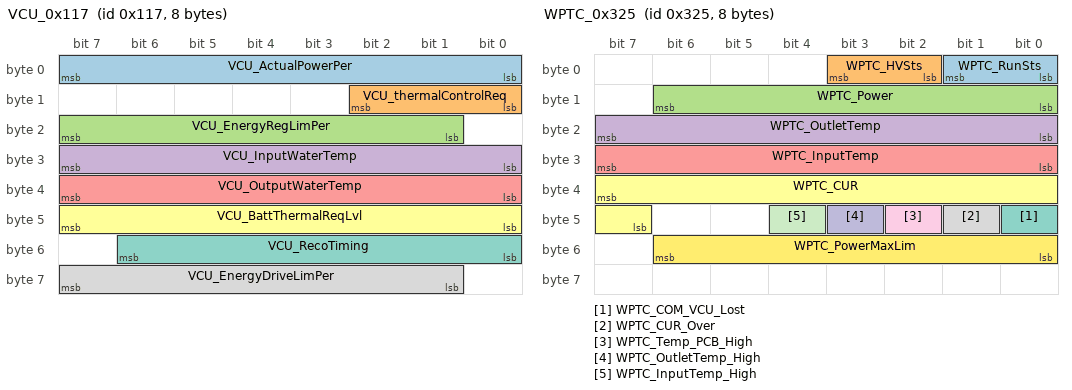
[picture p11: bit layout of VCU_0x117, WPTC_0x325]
BO_ 279 VCU_0x117: 8 GW
 SG_ VCU_ActualPowerPer : 7|8@0+ (1,-100) [-100|100] "" TBOX
 SG_ VCU_thermalControlReq : 10|3@0+ (1,0) [0|7] "" TBOX
 SG_ VCU_EnergyRegLimPer : 23|7@0+ (1,0) [0|100] "" TBOX
 SG_ VCU_InputWaterTemp : 31|8@0+ (0.5,-40) [-40|85] "℃" TBOX
 SG_ VCU_OutputWaterTemp : 39|8@0+ (0.5,-40) [-40|85] "℃" TBOX
 SG_ VCU_BattThermalReqLvl : 47|8@0+ (1,0) [0|15] "" TBOX
 SG_ VCU_RecoTiming : 54|7@0+ (1,0) [0|120] "" TBOX
 SG_ VCU_EnergyDriveLimPer : 63|7@0+ (1,0) [0|100] "" TBOX

BO_ 1424 BMS_0x590: 8 GW
 SG_ BMS_BattSerialNumber : 7|16@0+ (1,0) [0|9999] "" TBOX
 SG_ BMS_BattManuYear : 23|8@0+ (1,0) [0|255] "" TBOX
 SG_ BMS_BattManuMonth : 31|8@0+ (1,0) [0|255] "" TBOX
 SG_ BMS_BattManuDay : 39|8@0+ (1,0) [0|255] "" TBOX

BO_ 1425 BMS_0x591: 8 GW
 SG_ BMS_BattSupplierCode : 15|24@0+ (1,0) [0|16777215] "" TBOX
 SG_ BMS_ProductTypeCode : 39|8@0+ (1,0) [0|255] "" TBOX
 SG_ BMS_BattTypeCode : 47|8@0+ (1,0) [0|255] "" TBOX
 SG_ BMS_BattSpecCode : 55|16@0+ (1,0) [0|65535] "" TBOX

BO_ 1426 BMS_0x592: 8 GW
 SG_ BMS_BattRetrospectCode : 7|56@0+ (1,0) [1|72057594037927900] "" TBOX

BO_ 1427 BMS_0x593: 8 GW
 SG_ BMS_BattProductionDate : 7|24@0+ (1,0) [1|16777215] "" TBOX
 SG_ BMS_BattS_Num : 31|24@0+ (1,0) [0|16777215] "" TBOX
 SG_ BMS_BattRecycleCode : 55|16@0+ (1,0) [0|65535] "" TBOX

BO_ 1428 BMS_0x594: 8 GW
 SG_ BMS_BattCodeLenth : 7|8@0+ (1,0) [1|26] "" TBOX
 SG_ BMS_Temp_ProbeNum : 45|6@0+ (1,0) [0|63] "" TBOX
 SG_ BMS_PackageTotalNum : 47|2@0+ (1,0) [0|3] "" TBOX
 SG_ BMS_CellTotalNum : 55|8@0+ (1,0) [0|255] "" TBOX

BO_ 945 TBOX_0x3B1: 8 TBOX
 SG_ TBOX_YawAngvelocity : 7|16@0+ (1,0) [0|65535] "度/秒" GW
 SG_ TBOX_PitchAngvelocity : 23|16@0+ (1,0) [0|65535] "度/秒" GW
 SG_ TBOX_RollAngvelocity : 39|16@0+ (1,0) [0|65535] "度/秒" GW

BO_ 946 TBOX_0x3B2: 8 TBOX
 SG_ TBOX_YawAcceleration : 7|16@0+ (1,0) [0|65535] "g" GW
 SG_ TBOX_PitchAcceleration : 23|16@0+ (1,0) [0|65535] "g" GW
 SG_ TBOX_RollAcceleration : 39|16@0+ (1,0) [0|65535] "g" GW
 SG_ TBOX_GyroTemperature : 55|11@0+ (0.1,-75) [-75|125] "℃" GW

BO_ 1378 MCU_0x562: 8 GW
 SG_ MCU_MotorSts_GBT : 7|8@0+ (1,0) [0|255] "" TBOX
 SG_ MCU_MotoroffsetCalReq : 34|1@0+ (1,0) [0|1] "" TBOX

BO_ 805 WPTC_0x325: 8 GW
 SG_ WPTC_RunSts : 1|2@0+ (1,0) [0|3] "" TBOX
 SG_ WPTC_HVSts : 3|2@0+ (1,0) [0|3] "" TBOX
 SG_ WPTC_Power : 14|7@0+ (0.1,0) [0|12.7] "KW" TBOX
 SG_ WPTC_OutletTemp : 23|8@0+ (1,-40) [-40|215] "℃" TBOX
 SG_ WPTC_InputTemp : 31|8@0+ (1,-40) [-40|215] "℃" TBOX
 SG_ WPTC_CUR : 39|9@0+ (0.1,0) [0|40] "" TBOX
 SG_ WPTC_COM_VCU_Lost : 40|1@0+ (1,0) [0|1] "" TBOX
 SG_ WPTC_CUR_Over : 41|1@0+ (1,0) [0|1] "" TBOX
 SG_ WPTC_Temp_PCB_High : 42|1@0+ (1,0) [0|1] "" TBOX
 SG_ WPTC_OutletTemp_High : 43|1@0+ (1,0) [0|1] "" TBOX
 SG_ WPTC_InputTemp_High : 44|1@0+ (1,0) [0|1] "" TBOX
 SG_ WPTC_PowerMaxLim : 54|7@0+ (0.1,0) [0|12.7] "KW" TBOX

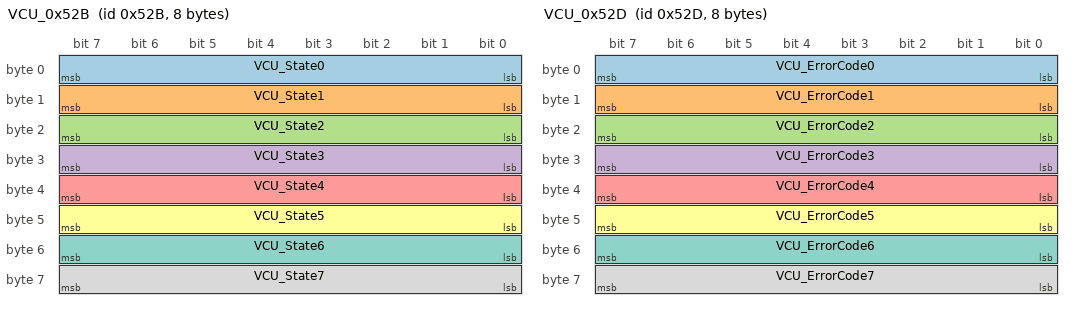
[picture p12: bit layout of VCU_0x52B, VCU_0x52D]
BO_ 1323 VCU_0x52B: 8 GW
 SG_ VCU_State0 : 7|8@0+ (1,0) [0|255] "" TBOX
 SG_ VCU_State1 : 15|8@0+ (1,0) [0|255] "" TBOX
 SG_ VCU_State2 : 23|8@0+ (1,0) [0|255] "" TBOX
 SG_ VCU_State3 : 31|8@0+ (1,0) [0|255] "" TBOX
 SG_ VCU_State4 : 39|8@0+ (1,0) [0|255] "" TBOX
 SG_ VCU_State5 : 47|8@0+ (1,0) [0|255] "" TBOX
 SG_ VCU_State6 : 55|8@0+ (1,0) [0|255] "" TBOX
 SG_ VCU_State7 : 63|8@0+ (1,0) [0|255] "" TBOX

BO_ 1325 VCU_0x52D: 8 GW
 SG_ VCU_ErrorCode0 : 7|8@0+ (1,0) [0|255] "" TBOX
 SG_ VCU_ErrorCode1 : 15|8@0+ (1,0) [0|255] "" TBOX
 SG_ VCU_ErrorCode2 : 23|8@0+ (1,0) [0|255] "" TBOX
 SG_ VCU_ErrorCode3 : 31|8@0+ (1,0) [0|255] "" TBOX
 SG_ VCU_ErrorCode4 : 39|8@0+ (1,0) [0|255] "" TBOX
 SG_ VCU_ErrorCode5 : 47|8@0+ (1,0) [0|255] "" TBOX
 SG_ VCU_ErrorCode6 : 55|8@0+ (1,0) [0|255] "" TBOX
 SG_ VCU_ErrorCode7 : 63|8@0+ (1,0) [0|255] "" TBOX

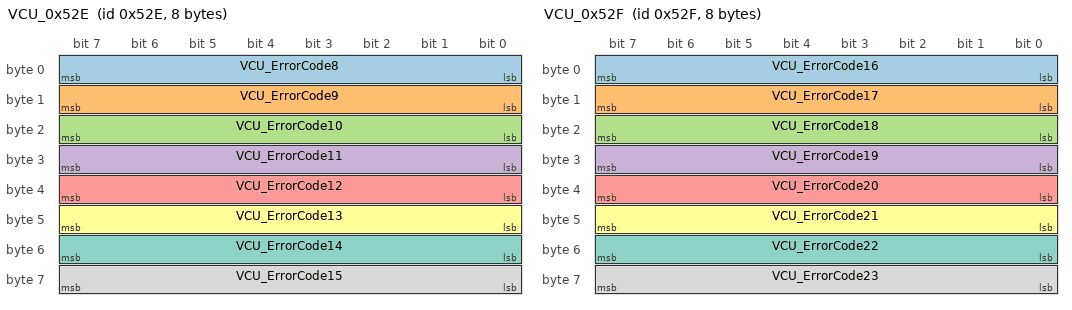
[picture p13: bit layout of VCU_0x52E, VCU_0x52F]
BO_ 1326 VCU_0x52E: 8 GW
 SG_ VCU_ErrorCode8 : 7|8@0+ (1,0) [0|255] "" TBOX
 SG_ VCU_ErrorCode9 : 15|8@0+ (1,0) [0|255] "" TBOX
 SG_ VCU_ErrorCode10 : 23|8@0+ (1,0) [0|255] "" TBOX
 SG_ VCU_ErrorCode11 : 31|8@0+ (1,0) [0|255] "" TBOX
 SG_ VCU_ErrorCode12 : 39|8@0+ (1,0) [0|255] "" TBOX
 SG_ VCU_ErrorCode13 : 47|8@0+ (1,0) [0|255] "" TBOX
 SG_ VCU_ErrorCode14 : 55|8@0+ (1,0) [0|255] "" TBOX
 SG_ VCU_ErrorCode15 : 63|8@0+ (1,0) [0|255] "" TBOX

BO_ 1327 VCU_0x52F: 8 GW
 SG_ VCU_ErrorCode16 : 7|8@0+ (1,0) [0|255] "" TBOX
 SG_ VCU_ErrorCode17 : 15|8@0+ (1,0) [0|255] "" TBOX
 SG_ VCU_ErrorCode18 : 23|8@0+ (1,0) [0|255] "" TBOX
 SG_ VCU_ErrorCode19 : 31|8@0+ (1,0) [0|255] "" TBOX
 SG_ VCU_ErrorCode20 : 39|8@0+ (1,0) [0|255] "" TBOX
 SG_ VCU_ErrorCode21 : 47|8@0+ (1,0) [0|255] "" TBOX
 SG_ VCU_ErrorCode22 : 55|8@0+ (1,0) [0|255] "" TBOX
 SG_ VCU_ErrorCode23 : 63|8@0+ (1,0) [0|255] "" TBOX

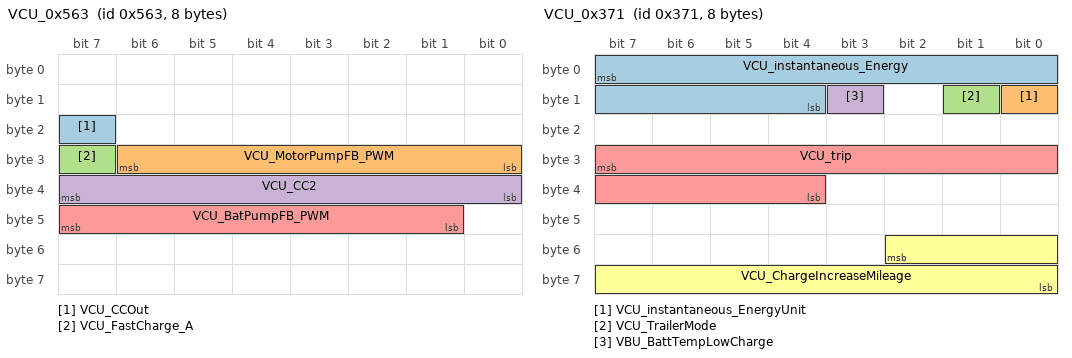
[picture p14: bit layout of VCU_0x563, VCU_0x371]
BO_ 1379 VCU_0x563: 8 GW
 SG_ VCU_CCOut : 23|1@0+ (1,0) [0|1] "" TBOX
 SG_ VCU_MotorPumpFB_PWM : 30|7@0+ (1,0) [0|100] "%" TBOX
 SG_ VCU_FastCharge_A : 31|1@0+ (1,0) [0|1] "" TBOX
 SG_ VCU_CC2 : 39|8@0+ (0.1,0) [0|25.4] "V" TBOX
 SG_ VCU_BatPumpFB_PWM : 47|7@0+ (1,0) [0|100] "%" TBOX

BO_ 881 VCU_0x371: 8 GW
 SG_ VCU_instantaneous_Energy : 7|12@0+ (0.1,-204.7) [-204.7|204.6] "" TBOX
 SG_ VCU_instantaneous_EnergyUnit : 8|1@0+ (1,0) [0|1] "" TBOX
 SG_ VCU_TrailerMode : 9|1@0+ (1,0) [0|1] "" TBOX
 SG_ VBU_BattTempLowCharge : 11|1@0+ (1,0) [0|1] "" TBOX
 SG_ VCU_trip : 31|12@0+ (1,0) [0|4095] "km" TBOX
 SG_ VCU_ChargeIncreaseMileage : 50|11@0+ (1,0) [0|2046] "km" TBOX

BO_ 882 VCU_0x372: 8 GW
 SG_ VCU_SubtotalAverageEnergy : 7|9@0+ (0.1,0) [0|51] "kwh/100km" TBOX
 SG_ VCU_SubtotalEnergy : 23|15@0+ (0.1,0) [0|3276.6] "kwh" TBOX
 SG_ VCU_Subtotaltime : 39|15@0+ (1,0) [0|32766] "min" TBOX
 SG_ VCU_ChargeIncreaseMileageSpeed : 51|12@0+ (1,0) [0|2046] "km/h" TBOX

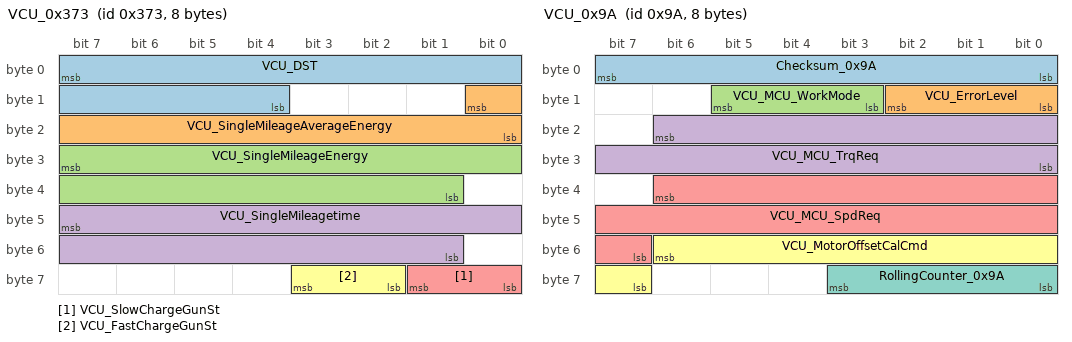
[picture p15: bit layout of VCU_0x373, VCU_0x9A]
BO_ 883 VCU_0x373: 8 GW
 SG_ VCU_DST : 7|12@0+ (1,0) [0|4095] "km" TBOX
 SG_ VCU_SingleMileageAverageEnergy : 8|9@0+ (0.1,0) [0|51] "kwh/100km" TBOX
 SG_ VCU_SingleMileageEnergy : 31|15@0+ (0.1,0) [0|3276.6] "kwh" TBOX
 SG_ VCU_SingleMileagetime : 47|15@0+ (1,0) [0|32766] "min" TBOX
 SG_ VCU_SlowChargeGunSt : 57|2@0+ (1,0) [0|3] "" TBOX
 SG_ VCU_FastChargeGunSt : 59|2@0+ (1,0) [0|3] "" TBOX

BO_ 154 VCU_0x9A: 8 GW
 SG_ Checksum_0x9A : 7|8@0+ (1,0) [0|255] "" TBOX
 SG_ VCU_ErrorLevel : 10|3@0+ (1,0) [0|7] "" TBOX
 SG_ VCU_MCU_WorkMode : 13|3@0+ (1,0) [0|7] "" TBOX
 SG_ VCU_MCU_TrqReq : 22|15@0+ (0.1,-1000) [-1000|1000] "NM" TBOX
 SG_ VCU_MCU_SpdReq : 38|16@0+ (1,-32767) [-32767|32768] "RPM" TBOX
 SG_ VCU_MotorOffsetCalCmd : 54|8@0+ (1,0) [0|255] "" TBOX
 SG_ RollingCounter_0x9A : 59|4@0+ (1,0) [0|15] "" TBOX

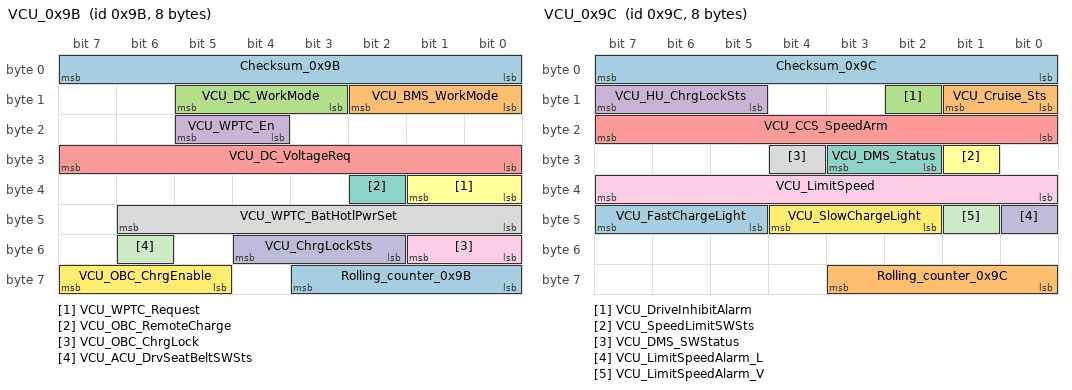
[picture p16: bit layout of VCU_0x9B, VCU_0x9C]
BO_ 155 VCU_0x9B: 8 GW
 SG_ Checksum_0x9B : 7|8@0+ (1,0) [0|255] "" TBOX
 SG_ VCU_BMS_WorkMode : 10|3@0+ (1,0) [0|7] "" TBOX
 SG_ VCU_DC_WorkMode : 13|3@0+ (1,0) [0|7] "" TBOX
 SG_ VCU_WPTC_En : 21|2@0+ (1,0) [0|3] "" TBOX
 SG_ VCU_DC_VoltageReq : 31|8@0+ (0.1,0) [12|16] "V" TBOX
 SG_ VCU_WPTC_Request : 33|2@0+ (1,0) [0|3] "" TBOX
 SG_ VCU_OBC_RemoteCharge : 34|1@0+ (1,0) [0|1] "" TBOX
 SG_ VCU_WPTC_BatHotlPwrSet : 46|7@0+ (0.1,0) [0|12] "KW" TBOX
 SG_ VCU_OBC_ChrgLock : 49|2@0+ (1,0) [0|3] "" TBOX
 SG_ VCU_ChrgLockSts : 52|3@0+ (1,0) [0|7] "" TBOX
 SG_ VCU_ACU_DrvSeatBeltSWSts : 54|1@0+ (1,0) [0|1] "" TBOX
 SG_ VCU_OBC_ChrgEnable : 63|3@0+ (1,0) [0|7] "" TBOX
 SG_ Rolling_counter_0x9B : 59|4@0+ (1,0) [0|15] "" TBOX

BO_ 156 VCU_0x9C: 8 GW
 SG_ Checksum_0x9C : 7|8@0+ (1,0) [0|255] "" TBOX
 SG_ VCU_Cruise_Sts : 9|2@0+ (1,0) [0|3] "" TBOX
 SG_ VCU_DriveInhibitAlarm : 10|1@0+ (1,0) [0|1] "" TBOX
 SG_ VCU_HU_ChrgLockSts : 15|3@0+ (1,0) [0|7] "" TBOX
 SG_ VCU_CCS_SpeedArm : 23|8@0+ (1,0) [0|200] "km/h" TBOX
 SG_ VCU_SpeedLimitSWSts : 25|1@0+ (1,0) [0|1] "" TBOX
 SG_ VCU_DMS_Status : 27|2@0+ (1,0) [0|3] "" TBOX
 SG_ VCU_DMS_SWStatus : 28|1@0+ (1,0) [0|1] "" TBOX
 SG_ VCU_LimitSpeed : 39|8@0+ (1,0) [0|200] "" TBOX
 SG_ VCU_LimitSpeedAlarm_L : 40|1@0+ (1,0) [0|1] "" TBOX
 SG_ VCU_LimitSpeedAlarm_V : 41|1@0+ (1,0) [0|1] "" TBOX
 SG_ VCU_SlowChargeLight : 44|3@0+ (1,0) [0|7] "" TBOX
 SG_ VCU_FastChargeLight : 47|3@0+ (1,0) [0|7] "" TBOX
 SG_ Rolling_counter_0x9C : 59|4@0+ (1,0) [0|15] "" TBOX

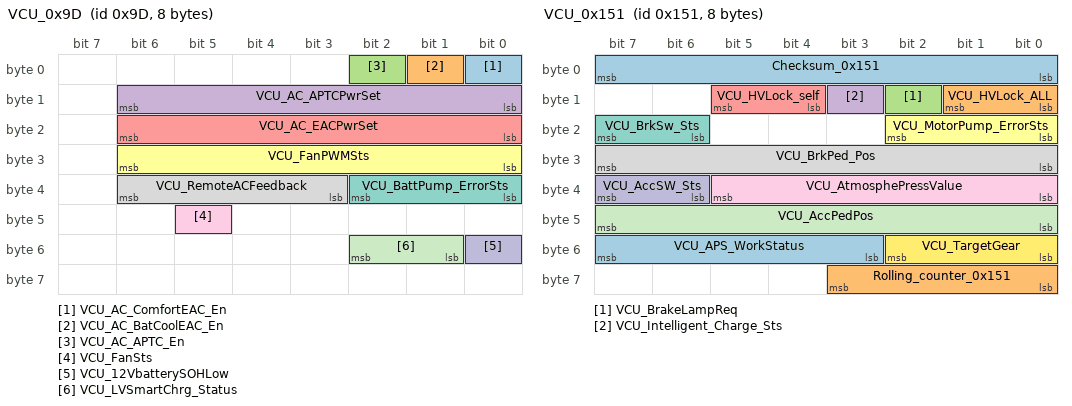
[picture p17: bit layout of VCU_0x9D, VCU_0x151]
BO_ 157 VCU_0x9D: 8 GW
 SG_ VCU_AC_ComfortEAC_En : 0|1@0+ (1,0) [0|1] "" TBOX
 SG_ VCU_AC_BatCoolEAC_En : 1|1@0+ (1,0) [0|1] "" TBOX
 SG_ VCU_AC_APTC_En : 2|1@0+ (1,0) [0|1] "" TBOX
 SG_ VCU_AC_APTCPwrSet : 14|7@0+ (0.1,0) [0|12.7] "KW" TBOX
 SG_ VCU_AC_EACPwrSet : 22|7@0+ (0.1,0) [0|12.7] "KW" TBOX
 SG_ VCU_FanPWMSts : 30|7@0+ (1,0) [0|100] "%" TBOX
 SG_ VCU_BattPump_ErrorSts : 34|3@0+ (1,0) [0|7] "" TBOX
 SG_ VCU_RemoteACFeedback : 38|4@0+ (1,0) [0|15] "" TBOX
 SG_ VCU_FanSts : 45|1@0+ (1,0) [0|1] "" TBOX
 SG_ VCU_12VbatterySOHLow : 48|1@0+ (1,0) [0|1] "" TBOX
 SG_ VCU_LVSmartChrg_Status : 50|2@0+ (1,0) [0|3] "" TBOX

BO_ 321 VCU_0x141: 8 GW
 SG_ Checksum_0x141 : 7|8@0+ (1,0) [0|255] "" TBOX
 SG_ VCU_DriverDemandTorq : 14|15@0+ (0.1,-1000) [-1000|1000] "NM" TBOX
 SG_ VCU_QECACC : 26|3@0+ (1,0) [0|7] "" TBOX
 SG_ VCU_CreepSwitch : 27|1@0+ (1,0) [0|1] "" TBOX
 SG_ VCU_OnepedalSetEn : 28|1@0+ (1,0) [0|1] "" TBOX
 SG_ VCU_GearShiftInProgress : 30|1@0+ (1,0) [0|1] "" TBOX
 SG_ VCU_ShiftInProgress_Status : 31|1@0+ (1,0) [0|1] "" TBOX
 SG_ VCU_AccelerationModePer : 38|7@0+ (1,0) [0|100] "" TBOX
 SG_ VCU_OverRide : 39|1@0+ (1,0) [0|1] "" TBOX
 SG_ VCU_DriveMode : 42|3@0+ (1,0) [0|7] "" TBOX
 SG_ VCU_APA_LC_Availability : 44|2@0+ (1,0) [0|3] "" TBOX
 SG_ VCU_APA_LC_FailureSts : 47|3@0+ (1,0) [0|7] "" TBOX
 SG_ VCU_E_Pedalwarn : 48|1@0+ (1,0) [0|1] "" TBOX
 SG_ VCU_ChargeDepthwarn : 49|1@0+ (1,0) [0|1] "" TBOX
 SG_ VCU_EPB_FunctionSet : 51|2@0+ (1,0) [0|3] "" TBOX
 SG_ VCU_APA_LC_Status : 63|4@0+ (1,0) [0|15] "" TBOX
 SG_ Rollingcounter_0x141 : 59|4@0+ (1,0) [0|15] "" TBOX

BO_ 336 VCU_0x150: 8 GW
 SG_ Checksum_0x150 : 7|8@0+ (1,0) [0|255] "" TBOX
 SG_ VCU_GearLeverPos : 10|3@0+ (1,0) [0|7] "" TBOX
 SG_ VCU_TortoiseLamp : 11|1@0+ (1,0) [0|1] "" TBOX
 SG_ VCU_Charge_Connect : 13|2@0+ (1,0) [0|3] "" TBOX
 SG_ VCU_12VbatteryError : 14|1@0+ (1,0) [0|1] "" TBOX
 SG_ VCU_ReadySts : 15|1@0+ (1,0) [0|1] "" TBOX
 SG_ VCU_MotorPumpError : 16|1@0+ (1,0) [0|1] "" TBOX
 SG_ VCU_VacuumSysFaultLamp : 17|1@0+ (1,0) [0|1] "" TBOX
 SG_ VCU_GearP_EnterWarning : 18|1@0+ (1,0) [0|1] "" TBOX
 SG_ VCU_VehicleSysFaultLamp : 19|1@0+ (1,0) [0|1] "" TBOX
 SG_ VCU_BattPumpError : 20|1@0+ (1,0) [0|1] "" TBOX
 SG_ VCU_DriveableAlarm : 21|1@0+ (1,0) [0|1] "" TBOX
 SG_ VCU_GearFlashReq : 23|2@0+ (1,0) [0|3] "" TBOX
 SG_ VCU_EnergyRecoveryPer : 31|7@0+ (1,0) [0|100] "%" TBOX
 SG_ VCU_ShowCarMod : 24|1@0+ (1,0) [0|1] "" TBOX
 SG_ VCU_Mileage : 39|10@0+ (1,0) [0|1022] "KM" TBOX
 SG_ VCU_PowerConsumption : 40|9@0+ (0.1,0) [0|51] "Kwh/100km" TBOX
 SG_ VCU_MotorLoopCoolantLow : 41|1@0+ (1,0) [0|1] "" TBOX
 SG_ VCU_BatLoopCoolantLow : 42|1@0+ (1,0) [0|1] "" TBOX
 SG_ VCU_ChargeDepthSts : 44|2@0+ (1,0) [0|3] "" TBOX
 SG_ VCU_CloolantHighAlarm : 45|1@0+ (1,0) [0|1] "" TBOX
 SG_ VCU_TBOX_SlowChargeSt : 63|4@0+ (1,0) [0|15] "" TBOX
 SG_ Rollingcounter_0x150 : 59|4@0+ (1,0) [0|15] "" TBOX

BO_ 337 VCU_0x151: 8 GW
 SG_ Checksum_0x151 : 7|8@0+ (1,0) [0|255] "" TBOX
 SG_ VCU_HVLock_ALL : 9|2@0+ (1,0) [0|3] "" TBOX
 SG_ VCU_BrakeLampReq : 10|1@0+ (1,0) [0|1] "" TBOX
 SG_ VCU_Intelligent_Charge_Sts : 11|1@0+ (1,0) [0|1] "" TBOX
 SG_ VCU_HVLock_self : 13|2@0+ (1,0) [0|3] "" TBOX
 SG_ VCU_MotorPump_ErrorSts : 18|3@0+ (1,0) [0|7] "" TBOX
 SG_ VCU_BrkSw_Sts : 23|2@0+ (1,0) [0|3] "" TBOX
 SG_ VCU_BrkPed_Pos : 31|8@0+ (1,0) [0|100] "%" TBOX
 SG_ VCU_AtmosphePressValue : 37|6@0+ (2,0) [0|116] "Kpa" TBOX
 SG_ VCU_AccSW_Sts : 39|2@0+ (1,0) [0|3] "" TBOX
 SG_ VCU_AccPedPos : 47|8@0+ (0.5,0) [0|100] "%" TBOX
 SG_ VCU_TargetGear : 50|3@0+ (1,0) [0|7] "" TBOX
 SG_ VCU_APS_WorkStatus : 55|5@0+ (1,0) [0|31] "" TBOX
 SG_ Rolling_counter_0x151 : 59|4@0+ (1,0) [0|15] "" TBOX

BO_ 401 APS_0x191: 8 GW
 SG_ Checksum_0x191 : 7|8@0+ (1,0) [0|255] "" TBOX
 SG_ APS_SystemSts : 10|3@0+ (1,0) [0|7] "" TBOX
 SG_ APS_Active : 11|1@0+ (1,0) [0|1] "" TBOX
 SG_ APS_VCU_BrakeFunctionMode : 15|4@0+ (1,0) [0|15] "deg" TBOX
 SG_ APS_AVM_HU_Failure : 16|1@0+ (1,0) [0|1] "" TBOX
 SG_ APS_VCU_BrakeModeSts : 19|3@0+ (1,0) [0|7] "" TBOX
 SG_ APS_VCU_Speed_Limitation : 23|4@0+ (0.2,0) [0|3] "km/h" TBOX
 SG_ APS_VCU_Target_Gear_Request : 26|3@0+ (1,0) [0|7] "" TBOX
 SG_ AVM_ControlRequest : 29|3@0+ (1,0) [0|7] "" TBOX
 SG_ APS_HU_ParkPrompttone : 30|1@0+ (1,0) [0|1] "" TBOX
 SG_ APS_VCU_APAFailed : 31|1@0+ (1,0) [0|1] "" TBOX
 SG_ AVM_SoftKeyResponse : 32|1@0+ (1,0) [0|1] "" TBOX
 SG_ AVM_FactoryMode : 33|1@0+ (1,0) [0|1] "" TBOX
 SG_ APS_ParkOutDirection : 35|2@0+ (1,0) [0|3] "" TBOX
 SG_ APS_TBOXConect_ParkInResp : 37|2@0+ (1,0) [0|3] "" TBOX
 SG_ APS_VCU_FailureBrakeMode : 39|2@0+ (1,0) [0|3] "" TBOX
 SG_ APS_VCU_Stop_Distance : 45|8@0+ (1,0) [0|255] "" TBOX
 SG_ APS_R_Gear_RequestTips : 47|2@0+ (1,0) [0|3] "" TBOX
 SG_ APS_VCU_Req_StraightOut : 48|1@0+ (1,0) [0|1] "" TBOX
 SG_ APS_VCU_Gear_Request : 51|3@0+ (1,0) [0|7] "" TBOX
 SG_ APS_VCU_Req_StraightCtrol : 53|2@0+ (1,0) [0|3] "" TBOX
 SG_ RollingCounter_0x191 : 59|4@0+ (1,0) [0|15] "" TBOX
 SG_ APS_TBOX_PowerOffResp : 61|2@0+ (1,0) [0|3] "" TBOX
 SG_ APS_TBOX_PowerOffReqResp : 63|2@0+ (1,0) [0|3] "" TBOX

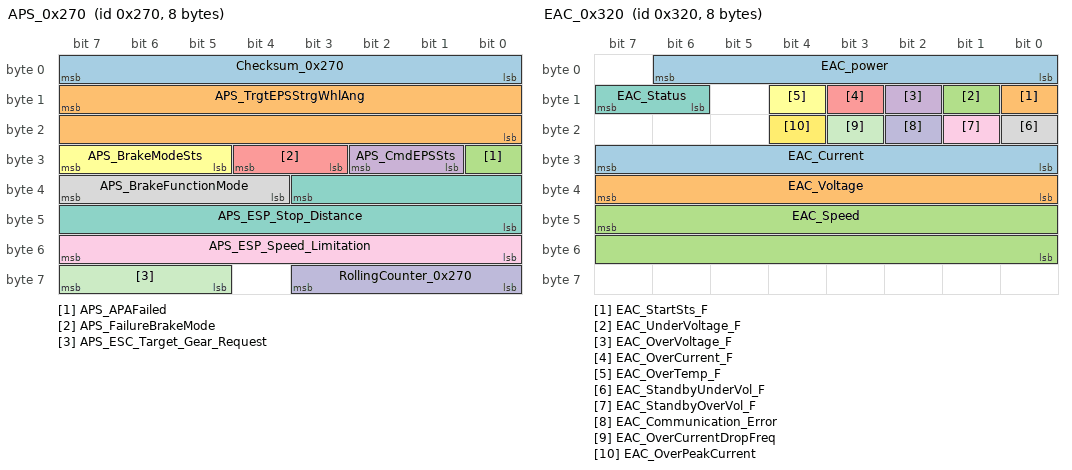
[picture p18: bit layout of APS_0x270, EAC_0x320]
BO_ 624 APS_0x270: 8 GW
 SG_ Checksum_0x270 : 7|8@0+ (1,0) [0|255] "" TBOX
 SG_ APS_TrgtEPSStrgWhlAng : 15|16@0+ (0.0238,-780) [-780|779.733] "deg" TBOX
 SG_ APS_APAFailed : 24|1@0+ (1,0) [0|1] "" TBOX
 SG_ APS_CmdEPSSts : 26|2@0+ (1,0) [0|3] "" TBOX
 SG_ APS_FailureBrakeMode : 28|2@0+ (1,0) [0|3] "" TBOX
 SG_ APS_BrakeModeSts : 31|3@0+ (1,0) [0|7] "" TBOX
 SG_ APS_ESP_Stop_Distance : 35|12@0+ (1,0) [0|4095] "cm" TBOX
 SG_ APS_BrakeFunctionMode : 39|4@0+ (1,0) [0|15] "" TBOX
 SG_ APS_ESP_Speed_Limitation : 55|8@0+ (0.1,0) [0|10] "Km/h" TBOX
 SG_ RollingCounter_0x270 : 59|4@0+ (1,0) [0|15] "" TBOX
 SG_ APS_ESC_Target_Gear_Request : 63|3@0+ (1,0) [0|7] "" TBOX

BO_ 625 APS_0x271: 8 GW
 SG_ Checksum_0x271 : 7|8@0+ (1,0) [0|255] "" TBOX
 SG_ APS_AVM_AutoSearchSts : 10|3@0+ (1,0) [0|7] "" TBOX
 SG_ APS_AVM_ParkOutChkResult : 11|1@0+ (1,0) [0|1] "" TBOX
 SG_ APS_AVM_CurrentPathNum : 15|4@0+ (1,0) [0|15] "" TBOX
 SG_ APS_AVM_TotalPathNum : 19|4@0+ (1,0) [0|15] "" TBOX
 SG_ APS_AVM_SuspendedReason : 22|3@0+ (1,0) [0|7] "" TBOX
 SG_ APS_AVM_AbortReason : 28|5@0+ (1,0) [0|31] "" TBOX
 SG_ APS_AVM_CurrentParkType : 31|3@0+ (1,0) [0|7] "" TBOX
 SG_ APS_AVM_OverrideReason : 34|3@0+ (1,0) [0|7] "" TBOX
 SG_ APS_AVM_VehicleDirection : 36|2@0+ (1,0) [0|3] "" TBOX
 SG_ APS_AVM_TerminatedType : 38|2@0+ (1,0) [0|3] "" TBOX
 SG_ APS_AVM_ParkOutSystemStatus : 39|1@0+ (1,0) [0|1] "" TBOX
 SG_ APS_AVM_CurrentStepNum : 43|4@0+ (1,0) [0|15] "" TBOX
 SG_ APS_RemoteParkIn_Status : 46|3@0+ (1,0) [0|7] "" TBOX
 SG_ APS_RemoteParkInResp : 47|1@0+ (1,0) [0|1] "" TBOX
 SG_ APS_BCM_RemoteParkIn_Status : 48|1@0+ (1,0) [0|1] "" TBOX
 SG_ APS_BCM_DoubleFlash : 49|1@0+ (1,0) [0|1] "" TBOX
 SG_ APS_BCM_AllDoorUnLock_Door : 50|1@0+ (1,0) [0|1] "" TBOX
 SG_ APS_RemoteParkOutResp : 51|1@0+ (1,0) [0|1] "" TBOX
 SG_ APS_BCM_PowerOffReq : 52|1@0+ (1,0) [0|1] "" TBOX
 SG_ APS_RemotePark_Error_Status : 55|3@0+ (1,0) [0|7] "" TBOX
 SG_ RollingCounter_0x271 : 59|4@0+ (1,0) [0|15] "" TBOX
 SG_ APS_APP_StraightOut_Status : 63|4@0+ (1,0) [0|15] "" TBOX

BO_ 920 ORM_0x398: 8 GW
 SG_ ORM_LeftMirrorMotor1fault : 32|1@0+ (1,0) [0|1] "" TBOX
 SG_ ORM_LeftMirrorMotor2fault : 33|1@0+ (1,0) [0|1] "" TBOX
 SG_ ORM_RightMirrorMotor1fault : 34|1@0+ (1,0) [0|1] "" TBOX
 SG_ ORM_RightMirrorMotor2fault : 35|1@0+ (1,0) [0|1] "" TBOX

BO_ 800 EAC_0x320: 8 GW
 SG_ EAC_power : 6|7@0+ (0.1,0) [0|12.7] "KW" TBOX
 SG_ EAC_StartSts_F : 8|1@0+ (1,0) [0|1] "" TBOX
 SG_ EAC_UnderVoltage_F : 9|1@0+ (1,0) [0|1] "" TBOX
 SG_ EAC_OverVoltage_F : 10|1@0+ (1,0) [0|1] "" TBOX
 SG_ EAC_OverCurrent_F : 11|1@0+ (1,0) [0|1] "" TBOX
 SG_ EAC_OverTemp_F : 12|1@0+ (1,0) [0|1] "" TBOX
 SG_ EAC_Status : 15|2@0+ (1,0) [0|3] "" TBOX
 SG_ EAC_StandbyUnderVol_F : 16|1@0+ (1,0) [0|1] "" TBOX
 SG_ EAC_StandbyOverVol_F : 17|1@0+ (1,0) [0|1] "" TBOX
 SG_ EAC_Communication_Error : 18|1@0+ (1,0) [0|1] "" TBOX
 SG_ EAC_OverCurrentDropFreq : 19|1@0+ (1,0) [0|1] "" TBOX
 SG_ EAC_OverPeakCurrent : 20|1@0+ (1,0) [0|1] "" TBOX
 SG_ EAC_Current : 31|8@0+ (0.1,0) [0|25.4] "A" TBOX
 SG_ EAC_Voltage : 39|8@0+ (4,0) [0|1016] "V" TBOX
 SG_ EAC_Speed : 47|16@0+ (1,0) [0|65534] "RPM" TBOX

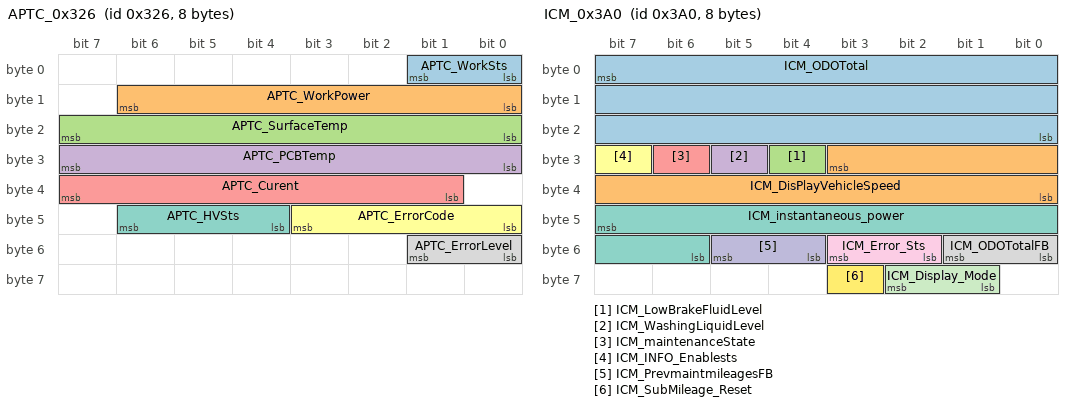
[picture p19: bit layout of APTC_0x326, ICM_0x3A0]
BO_ 806 APTC_0x326: 8 GW
 SG_ APTC_WorkSts : 1|2@0+ (1,0) [0|3] "" TBOX
 SG_ APTC_WorkPower : 14|7@0+ (0.1,0) [0|12.7] "KW" TBOX
 SG_ APTC_SurfaceTemp : 23|8@0+ (1,-40) [-40|215] "" TBOX
 SG_ APTC_PCBTemp : 31|8@0+ (1,-40) [-40|215] "" TBOX
 SG_ APTC_Curent : 39|7@0+ (0.2,0) [0|25] "" TBOX
 SG_ APTC_ErrorCode : 43|4@0+ (1,0) [0|15] "" TBOX
 SG_ APTC_HVSts : 46|3@0+ (1,0) [0|7] "" TBOX
 SG_ APTC_ErrorLevel : 49|2@0+ (1,0) [0|3] "" TBOX

BO_ 735 HU_0x2DF_Body: 8 GW
 SG_ HU_SetMemoryReq : 3|4@0+ (1,0) [0|15] "" TBOX
 SG_ HU_DeleteMemoryReq : 7|4@0+ (1,0) [0|15] "" TBOX
 SG_ HU_GetMemoryReq : 11|4@0+ (1,0) [0|15] "" TBOX
 SG_ HU_DirverSLV_Direction_set : 13|2@0+ (1,0) [0|3] "" TBOX
 SG_ HU_DirverSHV_Direction_set : 15|2@0+ (1,0) [0|3] "" TBOX
 SG_ HU_DirverLNV_Direction_set : 17|2@0+ (1,0) [0|3] "" TBOX
 SG_ HU_PassagerSLV_Direction_set : 19|2@0+ (1,0) [0|3] "" TBOX
 SG_ HU_PassagerSHV_Direction_set : 21|2@0+ (1,0) [0|3] "" TBOX
 SG_ HU_PassagerLNV_Direction_set : 23|2@0+ (1,0) [0|3] "" TBOX
 SG_ HU_DSM_heatSwitch : 25|2@0+ (1,0) [0|3] "" TBOX
 SG_ HU_DSM_Targtemp : 31|6@0+ (1,0) [34|42] "℃" TBOX
 SG_ HU_PSM_heatSwitch : 33|2@0+ (1,0) [0|3] "" TBOX
 SG_ HU_PSM_Targtemp : 39|6@0+ (1,0) [34|42] "℃" TBOX
 SG_ HU_DSMEasyEntrySW : 41|2@0+ (1,0) [0|3] "" TBOX
 SG_ HU_RVMAutoFoldSW : 49|2@0+ (1,0) [0|3] "" TBOX
 SG_ HU_RVMFoldButton : 51|2@0+ (1,0) [0|3] "" TBOX
 SG_ HU_RVM_R_DownSW : 53|2@0+ (1,0) [0|3] "" TBOX
 SG_ HU_Userdefined_Mirror : 58|3@0+ (1,0) [0|7] "" TBOX

BO_ 928 ICM_0x3A0: 8 GW
 SG_ ICM_ODOTotal : 7|24@0+ (1,0) [0|999999] "KM" TBOX
 SG_ ICM_DisPlayVehicleSpeed : 27|12@0+ (0.05625,0) [0|230.28749] "kph" TBOX
 SG_ ICM_LowBrakeFluidLevel : 28|1@0+ (1,0) [0|1] "" TBOX
 SG_ ICM_WashingLiquidLevel : 29|1@0+ (1,0) [0|1] "" TBOX
 SG_ ICM_maintenanceState : 30|1@0+ (1,0) [0|1] "" TBOX
 SG_ ICM_INFO_Enablests : 31|1@0+ (1,0) [0|1] "" TBOX
 SG_ ICM_instantaneous_power : 47|10@0+ (1,-400) [-400|400] "" TBOX
 SG_ ICM_ODOTotalFB : 49|2@0+ (1,0) [0|3] "" TBOX
 SG_ ICM_Error_Sts : 51|2@0+ (1,0) [0|3] "" TBOX
 SG_ ICM_PrevmaintmileagesFB : 53|2@0+ (1,0) [0|3] "" TBOX
 SG_ ICM_Display_Mode : 58|2@0+ (1,0) [0|3] "" TBOX
 SG_ ICM_SubMileage_Reset : 59|1@0+ (1,0) [0|1] "" TBOX

BO_ 896 BCM_0x380_LIN1: 8 GW
 SG_ SRF_MD1_Position : 6|7@0+ (1,0) [0|127] "" TBOX
 SG_ SRF_MD1_Lage : 7|1@0+ (1,0) [0|1] "" TBOX
 SG_ SRF_MD1_Sleflearnsuccessfully : 8|1@0+ (1,0) [0|1] "" TBOX
 SG_ SRF_MD1_FunctionAbort : 9|1@0+ (1,0) [0|1] "" TBOX
 SG_ SRF_MD1_drive_detect : 10|1@0+ (1,0) [0|1] "" TBOX
 SG_ SRF_MD1_ResponseError : 11|1@0+ (1,0) [0|1] "" TBOX
 SG_ SRF_RoofRunningStatus : 13|2@0+ (1,0) [0|3] "" TBOX
 SG_ RLS_RQ_LowBeam : 14|1@0+ (1,0) [0|1] "" TBOX
 SG_ RLS_RQ_PositionLamp : 15|1@0+ (1,0) [0|1] "" TBOX
 SG_ SHD_MRollo_FunctionAbort : 16|1@0+ (1,0) [0|1] "" TBOX
 SG_ SHD_MRollo_Driver_detect : 17|1@0+ (1,0) [0|1] "" TBOX
 SG_ SHD_MRollo_ResponseError : 18|1@0+ (1,0) [0|1] "" TBOX
 SG_ SHD_ShadeRunningStatus : 20|2@0+ (1,0) [0|3] "" TBOX
 SG_ SHD_ShadePosReached : 22|2@0+ (1,0) [0|3] "" TBOX
 SG_ RLS_Fault_Rain : 23|1@0+ (1,0) [0|1] "" TBOX
 SG_ SHD_MRollo_Position : 30|7@0+ (1,0) [0|127] "" TBOX
 SG_ SHD_MRollo_Sleflearnsuccessfully : 31|1@0+ (1,0) [0|1] "" TBOX
 SG_ RLS_Brightness_FW : 33|10@0+ (6,0) [0|6126] "LUX" TBOX
 SG_ RLS_Fault_Light : 34|1@0+ (1,0) [0|1] "" TBOX
 SG_ RLS_ResponseError : 35|1@0+ (1,0) [0|1] "" TBOX
 SG_ RLS_Rain_Intensity : 39|4@0+ (10,0) [0|100] "%" TBOX
 SG_ RLS_Temperature : 55|8@0+ (1,-50) [-50|205] "" TBOX
 SG_ RLS_Humid : 63|8@0+ (1,0) [0|100] "" TBOX

BO_ 784 BCM_0x310: 8 GW
 SG_ BCM_SystemPowerMode : 1|2@0+ (1,0) [0|3] "" TBOX
 SG_ BCM_AntiThelf_Sts : 3|2@0+ (1,0) [0|3] "" TBOX
 SG_ BCM_DriverLock_Sts : 5|2@0+ (1,0) [0|3] "" TBOX
 SG_ BCM_StartRequest : 6|1@0+ (1,0) [0|1] "" TBOX
 SG_ BCM_partialarmed_ActiveSts : 7|1@0+ (1,0) [0|1] "" TBOX
 SG_ BCM_Hood_Sts : 9|2@0+ (1,0) [0|3] "" TBOX
 SG_ BCM_ChargerLock_ControlSts : 10|1@0+ (1,0) [0|1] "" TBOX
 SG_ BCM_PositionLight_Sts : 11|1@0+ (1,0) [0|1] "" TBOX
 SG_ BCM_TurnLeftLight_Sts : 12|1@0+ (1,0) [0|1] "" TBOX
 SG_ BCM_TurnRightLight_Sts : 13|1@0+ (1,0) [0|1] "" TBOX
 SG_ BCM_Daylight_Sts : 14|1@0+ (1,0) [0|1] "" TBOX
 SG_ BCM_HighBeam_Sts : 15|1@0+ (1,0) [0|1] "" TBOX
 SG_ BCM_LowBeam_Sts : 16|1@0+ (1,0) [0|1] "" TBOX
 SG_ BCM_AutoHeadlight_Sts : 17|1@0+ (1,0) [0|1] "" TBOX
 SG_ BCM_brakeLight_Sts : 18|1@0+ (1,0) [0|1] "" TBOX
 SG_ BCM_HazardLight_Sts : 19|1@0+ (1,0) [0|1] "" TBOX
 SG_ BCM_RearFoglight_Sts : 20|1@0+ (1,0) [0|1] "" TBOX
 SG_ BCM_BrkSw_Sts : 22|2@0+ (1,0) [0|3] "" TBOX
 SG_ BCM_FL_Door_Sts : 25|2@0+ (1,0) [0|3] "" TBOX
 SG_ BCM_FR_Door_Sts : 27|2@0+ (1,0) [0|3] "" TBOX
 SG_ BCM_RL_Door_Sts : 29|2@0+ (1,0) [0|3] "" TBOX
 SG_ BCM_RR_Door_Sts : 31|2@0+ (1,0) [0|3] "" TBOX
 SG_ BCM_Trunk_Door_Sts : 33|2@0+ (1,0) [0|3] "" TBOX
 SG_ BCM_PLGOutsideSW : 34|1@0+ (1,0) [0|1] "" TBOX
 SG_ BCM_HornControlsts : 35|1@0+ (1,0) [0|1] "" TBOX
 SG_ BCM_Fwiper_Mist_Sts : 36|1@0+ (1,0) [0|1] "" TBOX
 SG_ BCM_Fwiper_washing_Sts : 37|1@0+ (1,0) [0|1] "" TBOX
 SG_ BCM_RKE_lock_Unlock_req : 39|2@0+ (1,0) [0|3] "" TBOX
 SG_ BCM_FWiper_Sts : 42|3@0+ (1,0) [0|7] "" TBOX
 SG_ BCM_RWiper_Sts : 44|2@0+ (1,0) [0|3] "" TBOX
 SG_ BCM_RearViewFoldSts : 45|1@0+ (1,0) [0|1] "" TBOX
 SG_ BCM_RearViewAutoSWSts : 46|1@0+ (1,0) [0|1] "" TBOX
 SG_ BCM_RearViewHeatSts : 47|1@0+ (1,0) [0|1] "" TBOX
 SG_ BCM_WorkMode : 49|2@0+ (1,0) [0|3] "" TBOX
 SG_ BCM_TBOXUnlockEnableSts : 50|1@0+ (1,0) [0|1] "" TBOX
 SG_ BCM_FwiperServiceSWsts : 51|1@0+ (1,0) [0|1] "" TBOX
 SG_ BCM_PowerONorOFF_Reason : 55|4@0+ (1,0) [0|15] "" TBOX
 SG_ BCM_SupplyVoltage : 63|8@0+ (0.1,0) [0|25.4] "" TBOX

CM_ "Version:V3.9,Date:2018/9/26,Author:李明,Review:,Approval:,Description:()更新版本;
Version:V4.0,Date:10-10月-2018,Author:李明,Review:,Approval:,Description:()1、更新TBOX_BCM_DoorLock_Control信号定义
2、删除TBOX_BCM_Hazard和TBOX_BCM_Horn信号，并新增TBOX_BCM_CarLocating;
Version:V4.1,Date:16-10月-2018,Author:李明,Review:,Approval:,Description:()1、TBOX接收BCM_UnLockReason和BCM_LockReasonc;
Version:V4.2,Date:17-10月-2018,Author:李明,Review:,Approval:,Description:()1、TBOX接收AC_0x254报文内信号;
Version:V4.3,Date:18-10月-2018,Author:李明,Review:,Approval:,Description:()1、Tbox接收ACU_CrashStatus、BMS_TotalCharging_Ah、PLG_OpenAng、PLG_OpenAngValid、ICM_DisPlayVehicleSpeed
2、TBOX接收CM_TPMS_0x502和CM_TPMS_0x501报文内信号
3.、更新TBOX_BCM_PowerON_limit信号发送周期为Cycle
4、更新TBOX_BCM_PowerON_Request信号定义
5、更新TBOX_RemotePhotograph信号定义;
Version:V4.4,Date:12-12月-2018,Author:李明,Review:,Approval:,Description:()1、Tbox接收MCU_0x324和MCU_0x122报文内信号
2、更新TBOX_VCU_12vChargeReq和TBOX_VCU_TimeCharge的layout
3、TBOX_0x353报文内新增APS控制相关信号Checksum_0x353/TBOX_BTKey_valid/TBOX_APS_RequstRemoteParkOut/TBOX_APS_StartRemoteParkOut/TBOX_APS_RequstRemoteParkIn/TBOX_APS_StartRemoteParkIn/TBOX_APS_PoewerOff_Request/RollingCounter_0x353
4、更新TBOX_Key_valid的信号定义
5、TBOX接收员APS_0x271和APS_0x191报文内相关信号;
Version:V4.5,Date:13-12月-2018,Author:李明,Review:,Approval:,Description:()1、GW增加发送GW_TBOX_0x5C1_Version
2、TBOX_0x351更新TBOX_BCM_DoorLock_Control为TBOX_BCM_DoorLock_Control_4G，并且增加TBOX_BCM_DoorLock_Control_BT
3、更新TBOX_Key_valid为TBOX_BT_Key_valid;
Version:V4.6,Date:02-1月-2019,Author:李明,Review:,Approval:,Description:()1、更新TBOX_BCM_ShadeSlidePosReq的初始值为0xFE
2、删除TBOX_AC_FDefrostMode_Set
3、更新TBOX_AC_WindMode_Set信号定义
4、更新VCU_TBOX_SlowChargeSt信号定义
5、TBOX接收NSM_0x222和NEM_0x354报文内信号
6、TBOX接收各个ECU的版本号报文
7、TBOX新增接收DCDC_DischargeMode、DCDC_IdcLvCurr、DCDC_IdcHvCurr、DCDC_UdcLvVolt、DCDC_UdcHvVolt、DCDC_DeratingSts、DCDC_TempAct、VCU_DC_WorkMode、VCU_ErrorLevel、BMS_SPreCharging、BMS_RelayNeg、BMS_RelayPos、OBC_SoketTemp_N、OBC_CoolantPlateTemp、OBC_SoketTemp_L、OBC_ChgInputCurrent、OBC_ChgInputVoltage、OBC_CP_Duty、OBC_CC_Status、OBC_ChrgOutputVolt、OBC_ChrgFailLevel、OBC_ChrgSts、OBC_ChrgOutputCurr、OBC_S2Sts、OBC_ChrgAllowedSts、OBC_ElockSts、OBC_TempAct、BMS_ChrRequestU、BMS_ChrRequest、BMS_ChrRequestI、OBC_HardTempHig、VCU_OBC_RemoteCharge、VCU_OBC_ChrgEnable、BMS_ModuleBusbarMaxTemp、BMS_ModuleBusbarMinTemp、BMS_CCTemp1、MCU_OverTemp、BMS_CCTemp2、MCU_FaultLampOn、MCU_OverSpdWarning、MCU_AuthSts、MCU_IsCurrent、VCU_MCU_TrqReq、VCU_MCU_SpdReq
8、TBOX接收DCDC_0x660报文内所有信号
9、TBOX接收OBC_0x611报文内所有信号
10、TBOX接收BMS_0x100和BMS_0x102报文内所有信号
11、TBOX接收MCU_0x122和MCU_0x124报文内所有信号;
Version:V4.7,Date:10-1月-2019,Author:李明,Review:,Approval:,Description:()1、按照姚尧提供（TBOX上传的数据-故障数据上传用于企业分析-20181228.xlsx）更新TBOX接收的信号;
Version:V4.8,Date:14-1月-2019,Author:李明,Review:,Approval:,Description:()1、按照姚尧提供（TBOX上传的数据-故障数据上传用于企业分析_V0.3_20190111.xlsx）更新TBOX接收的信号
2、删除TBOX在TBOX CAN接收和发送TBOX_UDSDiag_ReqPhsy、UDSDiag_ReqFunc、TBOX_UDSDiag_Resp报文;
Version:V4.9,Date:15-1月-2019,Author:李明,Review:,Approval:,Description:()1、更新TBOX_APS_RequstRemoteParkOut和TBOX_APS_RequstRemoteParkIn的信号长度为1;
Version:V5.0,Date:16-1月-2019,Author:李明,Review:,Approval:,Description:()1、TBOX_0x352增加发送TBOX_DVRFilelogrequest;
Version:V5.1,Date:18-1月-2019,Author:李明,Review:,Approval:,Description:()1、更新BCM_AuthReq_0x18和TBOX_AuthResp_0x19的信号描述与防盗接口规范保持一致
2、TBOX_0x353增加发送TBOX_APS_StraightOut_Request1和TBOX_APS_StraightOut_Request2;
Version:V5.2,Date:26-2月-2019,Author:李明,Review:,Approval:,Description:()1、TBOX增加发送0x3B1和0x3B2报文
2、更新TBOX_DSM_Targtemp和TBOX_PSM_Targtemp的信号defauit值为0x3F;
Version:V201.190415,Date:15-4月-2019,Author:李明,Review:,Approval:,Description:()1、删除TBOX_BCM_Poweroff_Request
2、TBOX_0x351增加发送TBOX_APS_PowerON_Request
3、更新BCM_FWiper_Sts的信号定义
4、VCU_0x9B新增VCU_OBC_ChrgLock
5、TBOX_0x353增加发送BOX_VCU_RemoteChrgLock
6、更新TBOX_BCM_selflearn_MD1和TBOX_BCM_selflearn_Mrollo的信号发送类型为Cycle
7、TBOX接收VCU_ChrgLockSts
8、TBOX_0x351增加发送TBOX_FOTA_wakeup
9、更新SCM_FWiper_Switch的信号值描述
10、更新MCU_0x120周期为20ms;
Version:V202.190715,Date:15-7月-2019,Author:李明,Review:,Approval:,Description:()1、更新TBOX_NEM_0x301的信号定义
2、TBOX增加发送TBOX_NSM_0x302
3、TBOX增加接收NEM_0x303和NSM_0x304
4、Tbox增加接收FMCU_MotorSts_GBT
5、更新TBOX_AC_Temp_set的最小值为15（0xF)
6、VCU_0x151报文内信号VCU_HVLock信号名更细为VCU_HVLock_ALL
7、VCU_0x151报文新增VCU_HVLock_self,Tbox接收
8、更新TBOX_DSM_Targtemp和TBOX_PSM_Targtemp的信号初始值为0x3F
9、Tbox接收VCU_APS_WorkStatus
10、更新所有的FMCU名字为MCU
11、TBOX_0x221报文新增发送TBOX_WelcomefuncReq信号
12、删除TBOX接收BMS_0x114
13、TBOX接收VCU_0x117
14、TBOX增加接收BMS_0x590、BMS_0x591、BMS_0x592、BMS_0x593
15、TBOX删除接收ESP_0x125、MRR_0x131、MRR_0x132、VCU_0x140、EPS_0x175、PA_0x194、PA_0x195、PA_0x196、ESP_0x211、ESP_0x214、MRR_0x232、ESP_0x243、ESP_0x244、MPC_0x246、VCU_0x701
16、更新TBOX_VCU_TimeCharge的信号值描述
17、更新DVR_Sdcard_Sts的信号值描述
18、VCU_0x141删除VCU_AccelerationMode和VCU_Onepedal、VCU_0x141增加发送VCU_DriveMode
19、VCU_0x150删除VCU_EnergyRecoveryMode，VCU_0x150增加发送VCU_GearFlashReq
20、VCU_0x9D增加发送 VCU_FanSts;
Version:V203.190815,Date:15-8月-2019,Author:李明,Review:,Approval:,Description:()1、TBOX接收BCM_TPMS_0x501
2、TBOX接收APS_VCU_Req_StraightOut
3、TBOX增加发送TBOX_0x3C1报文,ICM接收
4、TBOX增加接收VCU_12VbatterySOHLow、
5、BMS_0x590中的BMS_BattManuYear、BMS_BattManuMonth、BMS_BattManuDay信号修改“物理最小值”、“物理最大值”、“总线最小值”“总线最大值”、“初始值”
6、BMS_0x116中增加BMS_LowVoltageMSD低压MSD状态；
7、BMS_0x116中增加BMS_FuseFault电池熔断器故障
8、BMS_0x116调整BMS_CurrSensorFault的起始位，信号长度修改为2个bit。
9、BMS_0x102中BMS_Insulation_R初始值修改为0x3FE；
10、TBOX_0x353增加发送TBOX_ChargeDepthSet
11、TBOX新增接收VCU_ChargeDepthSts
12、VCU_0x150新增发送VCU_ChargeDepthSts
13、TBOX增加接收BCM_0x330报文内信号
14、TBOX接收HU_0x3A5报文内HU_RemoteCharge_StartHour、HU_RemoteCharge_Startmin、HU_RemoteCharge_Set、HU_ChargeCtrl_Set
15、TBOX_0x352新增发送TBOX_RemoteCharge_Setsts、TBOX_ChargeCtrl_Setsts;
Version:V204.191015,Date:15-10月-2019,Author:李明,Review:,Approval:,Description:()1、更新BCM_TBOXUnlockEnableSts的信号描述为‘TBOX发解锁尾门命令后，BCM反馈的解锁使能状态’
2、TBOX增加接收HU_TBOXwelcomeReq_set
3、TBOX_0x351增加发送TBOX_welcomefuncReqsts
4、TBOX_0x353新增发送信号TBOX_FOTA_mode
5、更新DVR_ControlResult的信号值描述，TBOX接收
6、更新TBOX_BT_Key_valid的信号值描述
7、TB0X_0x352新增发送TBOX_PLG_OpenControl
8、TBOX接收GW_IBS_0x334和GW_IBS_0x335报文内相关信号
9、TBOX接收ICM_ODOTotalFB和ICM_PrevmaintmileagesFB
10、更新APS_0x191报文里的APS_AVM_ViewModeResp的信号名为APS_VCU_BrakeFunctionMode，并更新其信号值描述；APS_0x191报文里删除AVM_TrunningEnterAVMFuncResp、AVM_CarIconTransparentResp、AVM_OnroadCalibResp、AVM_CarIconColorResp、AVM_DynamicPGS_Resp、APS_TBOXConect_ParkOutResp、AVM_ViewModeRespExtend、APS_SlotSearchingOverSpeed、APS_ACU_DrvSeatBeltSWSts；APS_0x191报文里增加APS_VCU_BrakeModeSts、APS_VCU_Speed_Limitation、APS_VCU_Target_Gear_Request、APS_VCU_APAFailed、APS_VCU_FailureBrakeMode、APS_VCU_Stop_Distance
11、TBOX_0x351新增发送TBOX_Publish_Wakeup
12、VCU_0x151增加发送VCU_AtmosphePressValue
13、VCU_0x141报文新增发送VCU_APA_LC_Availability、VCU_APA_LC_FailureSts、VCU_APA_LC_Status
14、更新VCU_WPTC_En的信号长度和信号值描述
15、VCU_0x141新增发送VCU_OnepedalAlarm和VCU_Onepedal
16、VCU_OnepedalAlarm信号名改为VCU_OnepedalSetEn，并更新信号值描述
17、VCU_0x141增加发送VCU_E_Pedalwarn、VCU_ChargeDepthwarn
18、VCU_0x117增加发送VCU_ActualPowerPer、VCU_EnergyRegLimPer、VCU_EnergyDriveLimPer
19、更新VCU_DriveMode的信号值描述;
Version:V205.191115,Date:15-11月-2019,Author:李明,Review:,Approval:,Description:()1、TBOX_0x3B2增加发送TBOX_GyroTemperature
2、TBOX_0x221增加发送TBOX_Timer_out;
Version:V206.191130,Date:30-11月-2019,Author:李明,Review:,Approval:,Description:()1、TBOX_0x352删除发送TBOX_DVRFilelogreques
2、TBOX_0x351删除发送TBOX_FOTA_wakeup
3、TBOX_0x353增加发送TBOX_FOTA_wakeup
4、VCU_0x9A帧的VCU_MCU_Workmode信号值定义增加0x5：HillHold、0x6：EmgPark
5、MCU_0x120帧的MCU_WorkSts信号值定义增加0xB：HillHold;
Version:V301.200115,Date:15-1月-2020,Author:李明,Review:,Approval:,Description:()1、TBOX删除接收NEM_0x354报文内信号NEM_BCM_DoorLockControl、NEM_HU_DoorLocksetFB、NEM_Switch_Sts、NEM_failure_Sts、NEM_SmartCard_valid、NEM_SmartCard_MatchedNum、NEM_TimeRemaining、NEM_tokenfeedback
2、TBOX删除接收NSM_0x222报文内信号NSM_SmartCard_valid、NSM_Swtich_Sts、NSM_failure_Sts、NSM_SmartCard_MatchedNum、NSM_TimeRemaining、NSM_tokenfeedback
3、TBOX取消发送报文TBOX_NEM_0x301和TBOX_NSM_0x302
4、TBOX取消接收报文NEM_0x303、NSM_0x304、NEM_0x5D6_Version、NSM_0x5D7_Version内所有信号
5、APS_0x191报文增加发送APS_HU_ParkPrompttone
6、APS_AVM_SuspendedReason信号0x1更新为0x1=VoiceSuspended
7、APS_AVM_AbortReason信号值0x8更新为0x8=VoiceExit
8、TBOX增加接收BCM_PEPS_0x354和BCM_PEPS_0x222报文内相关信号
9、删除BCM_0x247报文内BCM_KeylostWarning
10、更新BCM_PowerONWarning的信号值描述
11、更新BCM_SystemPowerMode的0x3含义为Ready
12、更新BCM_LockReason信号0x2=lock form PEPS lock request
13、更新BCM_UnLockReason的0x2:=Unlock form PEPS unlock request
14、更新VCU_WPTC_En的信号值描述
15、HU_TBOXwelcomeReq_set信号发送类型由cycle改为on change 信号
16、TBOX_FOTA_wakeup信号发送类型由cycle改为on change 信号;
Version:V302.200315,Date:15-3月-2020,Author:李明,Review:,Approval:,Description:()1、BCM_0x330报文里新增发送BCM_PEPSUnLockReason和BCM_PEPSLockReason
2、更新PEPS_DHA_LeftHandleSwitch和PEPS_PHA_RightHandleSwitch的信号发送类型改为OnChange（触发一次3帧），并更新这两个信号值0x3=reserved
3、更新BCM_PEPS_0x222的报文发送周期为50ms 
4、VCU_0x150报文增加发送VCU_ShowCarMod
5、0x116中增加BMS_PressureSensorFault压力传感器故障信号；
6、更新BMS_0x5E0_Version报文内信号定义;
Version:V303.200530,Date:30-5月-2020,Author:李明,Review:,Approval:,Description:()更新DSM_PSMheattemp和DSM_DSMheattemp的最大值最小值;
Version:V303.200530,Date:30-5月-2020,Author:李明,Review:,Approval:,Description:()VCU_0x141报文删除VCU_Onepedal;
Version:V303.200530,Date:30-5月-2020,Author:李明,Review:,Approval:,Description:()更新VCU_0x141报文内VCU_DriveMode的信号值描述;
Version:V303.200530,Date:30-5月-2020,Author:李明,Review:,Approval:,Description:()TBOX增加接收AC_Temp_setvalue;
Version:V304.200710,Date:10-7月-2020,Author:李明,Review:,Approval:,Description:()TBOX增加接收HU_TBOX_Reboot;
Version:V304.200710,Date:10-7月-2020,Author:李明,Review:,Approval:,Description:()TBOX_0x352增加发送TBOX_HU_rebootACK;
Version:V305.200803,Date:03-8月-2020,Author:李明,Review:,Approval:,Description:()TBOX_0x353报文增加发送BOX_APS_EPSStrgWhlAngZero;
Version:V305.200803,Date:03-8月-2020,Author:李明,Review:,Approval:,Description:()TBOX增加接收APS_APP_StraightOut_Status;
Version:V305.200803,Date:03-8月-2020,Author:李明,Review:,Approval:,Description:()TBOX增加接收DSM_0x390报文内DSM_DSMsettemp、DSM_PSMsettemp等信号;
Version:V305.200803,Date:03-8月-2020,Author:李明,Review:,Approval:,Description:()更新BCM_StartWarning、BCM_PowerOffWarning、BCM_PowerONWarning信号值描述;
Version:V305.200803,Date:03-8月-2020,Author:李明,Review:,Approval:,Description:()TBOX增加发送预留报文;
Version:V305.200803,Date:03-8月-2020,Author:李明,Review:,Approval:,Description:()TBOX增加接收预留报文;
Version:V305.200803,Date:03-8月-2020,Author:李明,Review:,Approval:,Description:()TBOX增加接收预留ID VCU_0x55A/VCU_0x55B/ VCU_0x55C/VCU_0x55D/ VCU_0x55E;
Version:V305.200803,Date:03-8月-2020,Author:李明,Review:,Approval:,Description:()TBOX增加发送预留IDTBOX_0x361/TBOX_0x362/TBOX_0x363/TBOX_0x364/TBOX_0x365;
Version:V306.201111,Date:11-11月-2020,Author:李明,Review:,Approval:,Description:()TBOX_0x355_Time报文增加发送TBOX_FOTA_mode_ALL;
Version:V307.201203,Date:03-12月-2020,Author:李明,Review:,Approval:,Description:()TBOX5增加接收HU_MCUPowerState、HU_SOCResetType、HU_HardACCState、HU_SOCWatchdog、HU_SPIConnectState、HU_BatteryVoltage、HU_MCUResetReason、HU_BCMSystemPowerMode;
Version:V308.210315,Date:15-3月-2020,Author:陈威,Review:,Approval:,Description:(TBOX)将0X355报文中的TBOX_FOTA_mode_ALL信号移至0x221报文中，信号起始位为11;
Version:V308.210315,Date:15-3月-2020,Author:陈威,Review:,Approval:,Description:(TBOX)更正BMS_0x5E0_Version报文中信号的coding值描述;
Version:V308.210315,Date:15-3月-2020,Author:陈威,Review:,Approval:,Description:(TBOX)增加接收报文VCU_0X561/VCU_0X52C报文及所有信号;
Version:V308.210315,Date:15-3月-2020,Author:陈威,Review:,Approval:,Description:(TBOX)增加接收报文VCU_0X371中信号VBU_BattTempLowCharge;
Version:V308.210315,Date:15-3月-2020,Author:陈威,Review:,Approval:,Description:(TBOX)报文TBOX_0x221增加发送TBOX_RemoteCharge_End Hour/TBOX_RemotCh_Full_SetSts/TBOX_RemoteCharge_Endmin信号;
Version:V308.210315,Date:15-3月-2020,Author:陈威,Review:,Approval:,Description:(TBOX)增加接收报文AC_0x255中信号;
Version:V308.210315,Date:15-3月-2020,Author:陈威,Review:,Approval:,Description:(TBOX)增加接收报文PA_DistFront_0x194/PA_DistRear_0x195中所有信号;
Version:V308.210315,Date:15-3月-2020,Author:陈威,Review:,Approval:,Description:(TBOX)增加接收BCM_PEPS_0x40报文中的PEPS_RKECommand，PEPS_TrunkReleaseReq信号;
Version:V308.210315,Date:15-3月-2020,Author:陈威,Review:,Approval:,Description:(TBOX)接收HU_0x2DE_PT报文中的HU_RemoteCharge_End Hour/HU_RemotCh_Full_SetSts/HU_RemoteCharge_Endmin信号;
Version:V308.210315,Date:15-3月-2021,Author:陈威,Review:,Approval:,Description:(TBOX)增加接收报文AC_0X257中的AC_SolarIntensity，AC_inout_MixwindSts，AC_OutPM25Value信号;
Version:V309.210409,Date:12-4月-2021,Author:陈威,Review:,Approval:,Description:(TBOX)企标上传数据新增接收信号：
1.增加补齐接收GW_IBS_0x334/GW_IBS_0x335报文中所有信号；
2.增加补齐接收WPTC_0x325报文中所有信号；
3.增加补齐接收ACU_0x210报文中所有信号；
4.增加补齐接收MCU_0x120报文中所有信号；
5.增加补齐接收HU_0x2DF报文中所有信号；
6.增加补齐接收OBC_0x550报文中所有信号；
7.增加补齐接收BCM_PEPS_0x40报文中所有信号；
8.增加补齐接收DSM_0x390报文中所有信号；
9.增加接收ESP_0x243/PA_0x196报文及其中的所有信号;
Version:V309.2104015,Date:15-4月-2021,Author:陈威,Review:,Approval:,Description:(TBOX)修改HU_0x2DE_PT报文中的HU_RemoteCharge_End Hour/HU_RemotCh_Full_SetSts/HU_RemoteCharge_Endmin信号的信号类型为on change；;
Version:V309.2104015,Date:15-4月-2021,Author:陈威,Review:,Approval:,Description:(TBOX)修改报文DSM_0x2A4报文中DSM_GetMemoryRsp信号的0x3:reserved值描述为0x3: 调节中止;
Version:V309.2104027,Date:27-4月-2021,Author:陈威,Review:,Approval:,Description:(GW)增加发送GW_SleepInd_0x505报文及所有信号;
Version:V309.2104027,Date:27-4月-2021,Author:陈威,Review:,Approval:,Description:(TBOX)增加接收GW_SleepInd_0x505报文及所有信号，用于上传各NM节点的sleep.ind置位情况;
Version:V309.2104027,Date:27-4月-2021,Author:陈威,Review:,Approval:,Description:(TBOX)增加接收DSM_0x391报文及报文内所有信号;
Version:V309.2104029,Date:29-4月-2021,Author:陈威,Review:,Approval:,Description:(TBOX)增加接收BMS_0x306/DVR_0x3F1/BCM_0x330/HU_0x2DE/ICM_0x3A0/DCDC_0X389/AC_0x254/DSM_0x2A4报文内所有信号;
Version:V309.2104029,Date:29-4月-2021,Author:陈威,Review:,Approval:,Description:(TBOX)增加补齐BMS_0x513/BMS_0x514/BMS_0x102/VCU_0X141/BCM_0x310（新增BCM_RKE_lock_Unlock_req信号，修改发送类型为CE）/BMS_0X105/BMS_0X112/BMS_0X115/MCU_0X123/BCM_PEPS_0X222/PLG_0X343/ICM_0X3A0/MCU_0X562/OBC_0x610/OBC_0X614/DVR_0X3F1;
Version:V309.2104029,Date:29-4月-2021,Author:陈威,Review:,Approval:,Description:(TBOX)删除报文VCU_0x9C中的VCU_EPB_FunctionSet信号，改为放到VCU_0x141中;
Version:V309.2104029,Date:29-4月-2021,Author:陈威,Review:,Approval:,Description:(TBOX)删除报文VCU_0X563中的VCU_RMotorLoopInputT/VCU_RMotorLoopOutputT/VCU_RMotorPumpPWM/VCU_RMotorPumpFB_PWM/VCU_CheckCC2;
Version:V310.210712,Date:12-7月-2021,Author:陈威,Review:,Approval:,Description:(TBOX)增加接收报文GW_SleepInd_0x505中信号TBOX_NM_SLEEP_Ind信号，起始bit12（用于上传NM节点唤醒休眠情况）。;
Version:V310.210712,Date:12-7月-2021,Author:陈威,Review:,Approval:,Description:(TBOX)增加接收ESP_ABS_0x211/ESP_0x244/EPS_0x176/EPS_0x177/EPS_0x260/BMS_0x114;
 ";

CM_ SG_ 276 BMS_KL30inputVol "KL30输入电压";
CM_ SG_ 276 BMS_thermalControlReq " 电池热管理控制请求";
CM_ SG_ 276 BMS_ThermalCtrlTargetTemp "电池包热管理目标温度";
CM_ SG_ 276 BMS_InputWaterTemp "电池进水口温度";
CM_ SG_ 276 BMS_OutputWaterTemp "电池出水口温度";
CM_ SG_ 276 BMS_BattThermalReqLvl "电池包热管理需求等级，暂时定义为15个等级";
CM_ SG_ 276 BMS_PACK_PressureValue "电池PACK压力值";
CM_ SG_ 276 BMS_0x114_RollingCounter "从0到15循环计数，如果通信中断，则重新从0开始计数。";
CM_ SG_ 608 EPS_SafeLampRed "The safe lamp (red)
红色警示灯-EPS严重故障";
CM_ SG_ 608 EPS_WarningLampYellow "The warning lamp (yellow)
黄色警示灯-不影响功能的故障";
CM_ SG_ 608 EPS_DTCFlag " DTC Flag";
CM_ SG_ 608 EPS_DriveModeSts "EPS驾驶模式状态";
CM_ SG_ 608 EPS_HU_DriveModeSetEn "驾驶模式开关请求设置使能状态";
CM_ SG_ 375 Checksum_0x177 "Checksum: IDMSB XOR IDLSB XOR Byte1 XOR Byte2 XOR Byte3 XOR Byte4 XOR Byte5 XOR Byte6XOR Byte7";
CM_ SG_ 375 EPS_EPSAPASts "Electric Power Steering Advanced Park Assist Status ，maximum signal value is 0xF but Signal Value Description is available only for 0 to 7 ，others Reserved，当EPS_EPSAPASts=active时自动泊车允许控制转向";
CM_ SG_ 375 EPS_EPSAPAInh "Electric Power Steering Advanced Park Assist Inhibit。maximum signal value is 0xFF but Signal Value Description is available only for 0,1,2,4,8 and 10，others Reserved";
CM_ SG_ 375 Rolling_counter_0x177 "RollingCounter: used 4bit length signal and the arithmetic is increased from 0 to 15 by every message.";
CM_ SG_ 374 EPS_Checksum_0x176 "Checksum: IDMSB XOR IDLSB XOR Byte1 XOR Byte2 XOR Byte3 XOR Byte4 XOR Byte5 XOR Byte6XOR Byte7";
CM_ SG_ 374 EPS_LKAResponseTorque " EPS对LKA控制器请求的扭矩响应值，左正右负
EPS feedback LKA Response Torque,left+/right-";
CM_ SG_ 374 EPS_LKAResponseTorqueValid "Validation bit of  LKAResponseTorque";
CM_ SG_ 374 EPS_LKAControlStatus "EPS feedback LKA Control Status";
CM_ SG_ 374 Rolling_counter_0x176 "RollingCounter: used 4bit length signal and the arithmetic is increased from 0 to 15 by every message.";
CM_ SG_ 580 Checksum_0x244 "Checksum: IDMSB XOR IDLSB XOR Byte1 XOR Byte2 XOR Byte3 XOR Byte4 XOR Byte5 XOR Byte6 XOR Byte7";
CM_ SG_ 580 ESC_APA_GearBoxEnable "ESC_APA_GearBoxEnable";
CM_ SG_ 580 ESC_APA_LC_FailureSts "ESC_APA_LC_FailureSts";
CM_ SG_ 580 ESC_APA_LC_Availability "ESC_APA_LC_Availability";
CM_ SG_ 580 ESP_VLC_InternalTgtAx "Calculated VLC internal target deceleration.";
CM_ SG_ 580 ESP_AWB_Available "Check whether AWB function is available or not.";
CM_ SG_ 580 ESP_AWB_Intervention "AWB active";
CM_ SG_ 580 ESP_ABA_Available "Check whether ABA function is available or not.";
CM_ SG_ 580 ESP_ABA_Intervention "Indicates ABA is active or not";
CM_ SG_ 580 ESP_ABP_Available "Check whether ABP function is available or not.";
CM_ SG_ 580 ESP_ABP_Intervention "Indicates ABP is active or not";
CM_ SG_ 580 ESC_VirtualGaspadelPosReq "ESC_VirtualGaspadelPosReq";
CM_ SG_ 580 ESC_CDPIntervention "Indicates CDP control active";
CM_ SG_ 580 ESC_CDPErrorSt "HMI Responsible,CAN get degrateCDP statement from DSW and send out";
CM_ SG_ 580 RollingCounter_0x244 "RollingCounter: used 4bit length signal and the arithmetic is increased from 0 to 15 by every message.";
CM_ SG_ 529 Checksum_0x211 "Checksum: IDMSB XOR IDLSB XOR Byte1 XOR Byte2 XOR Byte3 XOR Byte4 XOR Byte5 XOR Byte6 XOR Byte7";
CM_ SG_ 529 ABS_WheelSpeed_FL "Current wheel speed information of front left wheel.
左前轮轮速";
CM_ SG_ 529 ABS_WheelSpeed_FR "Current wheel speed information of front right wheel.
右前轮轮速";
CM_ SG_ 529 ABS_WheelSpeed_RL "Current wheel speed information of rear left wheel.
左后轮轮速";
CM_ SG_ 529 ABS_WheelSpeed_RR "Current wheel speed information of rear right wheel.
右后轮轮速";
CM_ SG_ 529 RollingCounter_0x211 "RollingCounter: used 4bit length signal and the arithmetic is increased from 0 to 15 by every message.";
CM_ SG_ 529 ABS_WheelSpeed_FL_Valid "Front left wheel speed valid
左前轮速有效";
CM_ SG_ 529 ABS_WheelSpeed_FR_Valid "Front right wheel speed valid
右前轮速有效";
CM_ SG_ 529 ABS_WheelSpeed_RL_Valid "Rear left wheel speed valid 
左后轮速有效";
CM_ SG_ 529 ABS_WheelSpeed_RR_Valid "Rear right wheel speed valid
右后轮速有效";
CM_ SG_ 913 DSM_Horizontalforward "主驾驶座椅水平向前调节开关状态";
CM_ SG_ 913 DSM_HorizontalBackward "主驾驶座椅水平后前调节开关状态";
CM_ SG_ 913 DSM_Liftup "主驾驶座椅向上抬高调节开关状态";
CM_ SG_ 913 DSM_LiftDown "主驾驶座椅向下调低调节开关状态";
CM_ SG_ 913 DSM_Backforward "主驾驶座椅靠背向前调节开关状态";
CM_ SG_ 913 DSM_BackBackward "主驾驶座椅靠背向后调节开关状态";
CM_ SG_ 913 PSM_Horizontalforward "副驾驶座椅水平向前调节开关状态";
CM_ SG_ 913 PSM_HorizontalBackward "副驾驶座椅水平后前调节开关状态";
CM_ SG_ 913 PSM_Backforward "副驾驶座椅靠背向前调节开关状态";
CM_ SG_ 913 PSM_BackBackward "副驾驶座椅靠背向后调节开关状态";
CM_ SG_ 913 DSM_Seat_Calibration "主驾驶座电机标定状态";
CM_ SG_ 1285 VCU_NM_SLEEP_Ind "路由的VCU节点的NM报文的sleep indication标志位，当源网段接收不到NM报文后发送1";
CM_ SG_ 1285 AC_NM_SLEEP_Ind "路由的AC节点的NM报文的sleep indication标志位，当源网段接收不到NM报文后发送1";
CM_ SG_ 1285 APL_NM_SLEEP_Ind "路由的APL节点的NM报文的sleep indication标志位，当源网段接收不到NM报文后发送1";
CM_ SG_ 1285 DVR_NM_SLEEP_Ind "路由的DVR节点的NM报文的sleep indication标志位，当源网段接收不到NM报文后发送1";
CM_ SG_ 1285 HU_NM_SLEEP_Ind "路由的HU节点的NM报文的sleep indication标志位，当源网段接收不到NM报文后发送1";
CM_ SG_ 1285 ICM_NM_SLEEP_Ind "路由的ICM节点的NM报文的sleep indication标志位，当源网段接收不到NM报文后发送1";
CM_ SG_ 1285 ORM_NM_SLEEP_Ind "路由的ORM节点的NM报文的sleep indication标志位，当源网段接收不到NM报文后发送1";
CM_ SG_ 1285 RSE_NM_SLEEP_Ind "路由的RSE节点的NM报文的sleep indication标志位，当源网段接收不到NM报文后发送1";
CM_ SG_ 1285 BCM_NM_SLEEP_Ind "路由的BCM节点的NM报文的sleep indication标志位，当源网段接收不到NM报文后发送1";
CM_ SG_ 1285 DSM_NM_SLEEP_Ind "路由的BCM节点的NM报文的sleep indication标志位，当源网段接收不到NM报文后发送1";
CM_ SG_ 1285 PLG_NM_SLEEP_Ind "路由的PLG节点的NM报文的sleep indication标志位，当源网段接收不到NM报文后发送1";
CM_ SG_ 1285 TBOX_NM_SLEEP_Ind "路由的TBOX节点的NM报文的sleep indication标志位，当源网段接收不到NM报文后发送1";
CM_ SG_ 406 PA_Buzzer_Alarm_Pattern_F "蜂鸣器报警方式-前";
CM_ SG_ 406 PA_Buzzer_Alarm_Pattern_R "蜂鸣器报警方式-后";
CM_ SG_ 406 PA_PDC_DISTANCE_FL "倒车雷达左前区距离显示(高配）";
CM_ SG_ 406 PA_PDC_DISTANCE_FML "倒车雷达左中前区距离显示（高配）";
CM_ SG_ 406 PA_PDC_DISTANCE_FMR "倒车雷达右中前区距离显示（高配）";
CM_ SG_ 406 PA_PDC_DISTANCE_FR "倒车雷达右前区距离显示（高配）";
CM_ SG_ 406 PAS_PDC_DISTANCE_RL "倒车雷达左后区距离显示（高配）";
CM_ SG_ 406 PA_PDC_DISTANCE_RML "倒车雷达左中后区距离显示（高配）";
CM_ SG_ 406 PA_PDC_DISTANCE_RMR "倒车雷达右中后区距离显示（高配）";
CM_ SG_ 406 PAS_PDC_DISTANCE_RR "倒车雷达右后区距离显示（全配）";
CM_ SG_ 406 PA_PDC_DISTANCE_LSF "倒车雷达前左侧区距离显示（高配）";
CM_ SG_ 406 PA_PDC_DISTANCE_RSF "倒车雷达前右侧区距离显示（高配）";
CM_ SG_ 406 PAS_PDC_DISTANCE_LSR "倒车雷达后左侧区距离显示（高配）";
CM_ SG_ 406 PA_PDC_DISTANCE_RSR "倒车雷达后右侧区距离显示（高配）";
CM_ SG_ 406 PA_PDC_WorkSts "PDC Work Status
PDC 工作状态";
CM_ SG_ 406 PA_PDC_MODE "倒车雷达的工作模式";
CM_ SG_ 579 Checksum_0x243 "Checksum: IDMSB XOR IDLSB XOR Byte1 XOR Byte2 XOR Byte3 XOR Byte4 XOR Byte5 XOR Byte6 XOR Byte7";
CM_ SG_ 579 ESP_YawRateValue "yaw rate signal
横摆角速度";
CM_ SG_ 579 ESP_YawrateValue_valid "yaw rate signal value valid or not.横摆角速度信号是否有效";
CM_ SG_ 579 ESP_BrakelightRequest "Indicate the request to light up brake light during emergent brake via EPB.
The request to illuminater brake light is needed by HHC,AVH,HDC,VLC,CDD also. This signal will be used not only for EPB emergency braking but also for all the above mentioned functions.
ESP请求点亮制动灯";
CM_ SG_ 579 ESP_Intervention "Indication that ESP system currently performs a intervention. Set also when TCS active.
ESP和TCS激活";
CM_ SG_ 579 ESP_LongAccSensor "vehicle longitudinal acceleration
车辆纵向加速度";
CM_ SG_ 579 ESP_LongAccSensorValid "vehicle longitudinal acceleration  value valid or not.
车辆纵向加速度信号是否有效";
CM_ SG_ 579 ESP_EPBWarningMessage1 "驻车情况下，未踩制动踏板，按下EPB释放按键
no Brake pedal pressed and release the EPB
仪表红色P灯常亮和EPB按键不能释放EPB不释放
EPB lamp no change.，no EPB release.";
CM_ SG_ 579 ESP_EPBWarningMessage2 "驻车情况下，自动驶离时，未系安全带或者未关闭车门
EPB driverOFF without seatblet or driver Door
仪表红色P灯常亮和EPB按键不能释放，EPB不释放
EPB lamp no change，no EPB release.";
CM_ SG_ 579 ESP_AVHWarningMessage "未系安全带或者未关闭驾驶员侧车门，按下AUTOHOLD 开关时
no driver door closed and no seatbelt. Then pressure the AVH button
AUTOHOLD按键不能执行
AUTOHOLD功能无法开启
No AUTOHOLD Active in standby.";
CM_ SG_ 579 ESP_LaterAccSensor "vehicle lateral acceleration
车辆横向加速度";
CM_ SG_ 579 ESP_LaterAccSensorValid "vehicle lateral acceleration value valid or not.
车辆横向加速度信号是否有效";
CM_ SG_ 579 ESP_AEB_Available "Check whether AEB function is available or not.";
CM_ SG_ 579 ESP_AEB_Intervention "Indicates AEB is active or not";
CM_ SG_ 579 RollingCounter_0x243 "RollingCounter: used 4bit length signal and the arithmetic is increased from 0 to 15 by every message.";
CM_ SG_ 579 ESC_APA_LC_Status "ESC_APA_LC_Status";
CM_ SG_ 734 HU_DriveMode "驾驶模式";
CM_ SG_ 734 HU_RemoteCharge_EndHour "APP发送的预约充电结束时间----时
0x0-0x17: Hour
0x18-0x1E: Invalid
(不触发时发默认值，触发设置被确认时发3帧有效值，然后回到默认值）";
CM_ SG_ 734 HU_RemoteCharge_Endmin "APP发送的预约充电结束时间----分
0x0-0x3B: Minute
0x3C-0x3E: Invalid
(不触发时发默认值，触发设置被确认时发3帧有效值，然后回到默认值）
";
CM_ SG_ 734 HU_RemotCh_Full_SetSts "HU 发送给 TBOX 的是否充满设置";
CM_ SG_ 404 Checksum_0x194 "Checksum: IDMSB XOR IDLSB XOR Byte1 XOR Byte2 XOR Byte3 XOR Byte4 XOR Byte5 XOR Byte6 XOR Byte7";
CM_ SG_ 404 PA_APA_DistanceValueLR_FL "左前长距离雷达探测障碍物距离值（高配）";
CM_ SG_ 404 PA_APA_DistanceValueLR_FR "右前长距离雷达探测障碍物距离值（高配）";
CM_ SG_ 404 PA_APA_DistanceValueSR_FL "左前短距离雷达探测障碍物距离值（高配）";
CM_ SG_ 404 PA_APA_DistanceValueSR_FML "左中前短距离雷达探测障碍物距离值（高配）";
CM_ SG_ 404 PA_APA_DistanceValueSR_FMR "右中前短距离雷达探测障碍物距离值（高配）";
CM_ SG_ 404 PA_APA_DistanceValueSR_FR "右前短距离雷达探测障碍物距离值（高配）";
CM_ SG_ 404 RollingCounter_0x194 "RollingCounter: used 4bit length signal and the arithmetic is increased from 0 to 15 by every message.";
CM_ SG_ 405 Checksum_0x195 "Checksum: IDMSB XOR IDLSB XOR Byte1 XOR Byte2 XOR Byte3 XOR Byte4 XOR Byte5 XOR Byte6 XOR Byte7";
CM_ SG_ 405 PA_APA_DistanceValueLR_RL "左后长距离雷达探测障碍物距离值（高配）";
CM_ SG_ 405 PA_APA_DistanceValueLR_RR "右后长距离雷达探测障碍物距离值（高配）";
CM_ SG_ 405 PA_APA_DistanceValueSR_RL "左后短距离雷达探测障碍物距离值（高配";
CM_ SG_ 405 PA_APA_DistanceValueSR_RML "左中后短距离雷达探测障碍物距离值（高配）";
CM_ SG_ 405 PA_APA_DistanceValueSR_RMR "右中后短距离雷达探测障碍物距离值（高配）";
CM_ SG_ 405 PA_APA_DistanceValueSR_RR "右后短距离雷达探测障碍物距离值（高配）";
CM_ SG_ 405 RollingCounter_0x195 "RollingCounter: used 4bit length signal and the arithmetic is increased from 0 to 15 by every message.";
CM_ SG_ 597 AC_OutletTemperature1 "出风口温度1";
CM_ SG_ 597 AC_OutletTemperature2 "出风口温度2";
CM_ SG_ 597 AC_EvaporatorTemp "蒸发器温度信号";
CM_ SG_ 597 AC_RefriPressure "制冷剂压力信号";
CM_ SG_ 597 AC_PWM_APTC "APTC的PWM信号
0-10%：停止
11-95%：比例调功率
95%以上：全功率";
CM_ SG_ 597 AC_VCU_FanPWMReq "冷却风扇PWM请求";
CM_ SG_ 597 AC_VCU_APTCPwrReq "空气PTC请求功率";
CM_ SG_ 597 AC_VCU_EACPwrReq "压缩机请求功率";
CM_ SG_ 64 PEPS_RKECommand "RKE命令";
CM_ SG_ 64 PEPS_DoorUnlockReq "PEPS 系统PE解锁请求(判断智能钥匙合法）";
CM_ SG_ 64 PEPS_DoorlockReq "PEPS 系统PE闭锁请求(判断智能钥匙合法）";
CM_ SG_ 64 PEPS_TrunkReleaseReq "PEPS行李箱打开请求";
CM_ SG_ 1377 VCU_MotorcoV "电机冷却液位电压差";
CM_ SG_ 1377 VCU_BattcolV "电池冷却液位电压差";
CM_ SG_ 1377 VCU_MotorLoopInputTemp "电机回路入口水温";
CM_ SG_ 1377 VCU_MotorLoopOutputTemp "电机回路出口水温";
CM_ SG_ 1377 VCU_IG1input "ON硬线输入";
CM_ SG_ 1377 VCU_startinput "Start硬线输入";
CM_ SG_ 1377 VCU_OBCwakeupVCU "OBC硬线唤醒VCU";
CM_ SG_ 1377 VCU_VCUwakeupOBC "VCU硬线唤醒OBC";
CM_ SG_ 1377 VCU_VCUwakeupBMS "VCU硬线唤醒BMS";
CM_ SG_ 1377 VCU_VCUwakeupMCU "VCU硬线唤醒MCU";
CM_ SG_ 1377 VCU_VacuumPumpRelay "真空泵继电器控制";
CM_ SG_ 1377 VCU_WPTCRelay "WPTC继电器控制";
CM_ SG_ 1377 VCU_MotorPumpPWM "电机水泵输出占空比";
CM_ SG_ 1377 VCU_BattPumpPWM "电池水泵输出占空比";
CM_ SG_ 1324 VCU_accelerator1 "油门信号电压1";
CM_ SG_ 1324 VCU_accelerator2 "油门信号电压2";
CM_ SG_ 1324 VCU_brakesensor1 "制动角度传感器电压1";
CM_ SG_ 1324 VCU_brakesensor2 "制动角度传感器电压2";
CM_ SG_ 1324 VCU_vacuumpumpsensor "真空泵压力传感器电压";
CM_ SG_ 1324 VCU_AtmosphePressure "大气压力传感器电压";
CM_ SG_ 1324 VCU_KL87inputVol "KL87输入电压";
CM_ SG_ 912 DSM_MirrorRdownSetStatus "后视镜倒车自动翻转功能设置反馈";
CM_ SG_ 912 DSM_LeftMirrorPosition_SX "左后视镜上下位置";
CM_ SG_ 912 DSM_LeftMirrorPosition_ZY "左后视镜左右位置";
CM_ SG_ 912 DSM_RightMirrorPosition_SX "右后视镜上下位置";
CM_ SG_ 912 DSM_RightMirrorPosition_ZY "右后视镜左右位置";
CM_ SG_ 912 DSM_LeftMirrorMotor1fault "左侧后视镜上下调节电机故障";
CM_ SG_ 912 DSM_LeftMirrorMotor2fault "左侧后视镜左右调节电机故障";
CM_ SG_ 912 DSM_RightMirrorMotor1fault "右侧后视镜上下调节电机故障";
CM_ SG_ 912 DSM_RightMirrorMotor2fault "右侧后视镜左右调节电机故障";
CM_ SG_ 912 DSM_WorkMode "DSM工作模式";
CM_ SG_ 912 DSM_LMM1_CalibrationSts "左侧后视镜上下调节电机标定状态";
CM_ SG_ 912 DSM_LMM2_CalibrationSts "左侧后视镜左右调节电机标定状态";
CM_ SG_ 912 DSM_RMM1_CalibrationSts "右侧后视镜上下调节电机标定状态";
CM_ SG_ 912 DSM_RMM2_CalibrationSts "右侧后视镜左右调节电机标定状态";
CM_ SG_ 912 DSM_PSMsettemp "副驾驶侧座椅记忆温度";
CM_ SG_ 912 DSM_DSMsettemp "驾驶侧座椅记忆温度";
CM_ SG_ 852 PEPS_Driver_Antenna_Error "外部主驾门天线故障";
CM_ SG_ 852 PEPS_Passenger_Antenna_Error "外部副驾门天线故障";
CM_ SG_ 852 PEPS_Trunk_Antenna_Error "外部后背门天线故障";
CM_ SG_ 852 BCM_HU_DoorLocksetFB "BCM反馈的当前解锁设置模式";
CM_ SG_ 852 PEPS_Facia_Antenna_Error "内部前排天线故障";
CM_ SG_ 852 PEPS_Rear_Antenna_Error "内部后排天线故障";
CM_ SG_ 852 PEPS_Handrail_Antenna_Error "内部IMMO天线故障";
CM_ SG_ 852 PEPS_unexpected_lock_RSSI "防误锁钥匙场强数据";
CM_ SG_ 852 PEPS_mislock_Antenna "防误锁搜到钥匙的天线编号";
CM_ SG_ 852 PEPS_ID_CAB_LIST "车内钥匙列表：1-在车内 0-不在车内
bit0: 1号钥匙状态 
bit1: 2号钥匙状态 
bit2: 3号钥匙状态 
bit3: 4号钥匙状态 ";
CM_ SG_ 852 PEPS_RecentlyKEYTypeCmd "智能钥匙上一次锁类型命令";
CM_ SG_ 852 PEPS_KeyLessCodeNumber "最近一把认证合法的钥匙";
CM_ SG_ 852 PEPS_PROSts "电源继电器驱动输出状态，3个bit从低到高分别表示 ACC/IGN1/IGN2继电器输出状态 0：没有输出 1：输出使能";
CM_ SG_ 852 PEPS_PRDErr "电源继电器驱动电路故障，3个bit从低到高分别表示 ACC/IGN1/IGN2继电器输出驱动 电路故障状态 0：没有故障 1：发生故障";
CM_ SG_ 546 PEPS_PEPSFailStatus "PEPS系统故障报警";
CM_ SG_ 546 PEPS_WarningKeyNotInCar "钥匙不在车内报警";
CM_ SG_ 546 PEPS_WarningKeyInCar "钥匙在车内报警 ";
CM_ SG_ 546 PEPS_WarningIgNotOff "电源未关报警";
CM_ SG_ 546 PEPS_WarningKeyLowBattery "钥匙电池电量低报警";
CM_ SG_ 546 PEPS_WarningStartupNotBrake "启动时请踩下刹车提醒";
CM_ SG_ 546 PEPS_WarningKeyNearbyIMMO "请将智能钥匙放在应急感应区以启动车辆";
CM_ SG_ 546 PEPS_PassiveWindowCom "PKE长按舒适升窗（车窗+天窗关闭）";
CM_ SG_ 546 PEPS_BackDoorKeyState "后背门区域智能钥匙状态";
CM_ SG_ 546 PEPS_KeyPosition "钥匙位置";
CM_ SG_ 546 PEPS_HandshakeFail "MAINMCU和AUXMCU之间的通讯故障";
CM_ SG_ 546 PEPS_Authpasstype "一级防盗认证通过原因";
CM_ SG_ 546 PEPS_EnableWirelessCharging "无线充电允许信号";
CM_ SG_ 546 PEPS_DHA_LeftHandleSwitch "左门把手解闭锁请求";
CM_ SG_ 546 PEPS_PHA_RightHandleSwitch "右门把手解闭锁请求";
CM_ SG_ 546 DHA_LockFlag "驾驶侧门把手解闭锁动作（BCM转发LIN4的0x12报文内的DHA_LockFlag至body CAN）";
CM_ SG_ 546 PHA_LockFlag "副驾驶侧门把手解闭锁动作（BCM转发LIN4的0x13报文内的PHA_LockFlag至body CAN）";
CM_ SG_ 820 IBS_U_BATT "Battery voltage";
CM_ SG_ 820 IBS_I_Range "Battery current range";
CM_ SG_ 820 IBS_I_BATT "Battery current（此信号的Resolution是可变的，信号解析请参考博世提供的IBS功能规范）";
CM_ SG_ 820 IBS_T_BATT "Battery temperature";
CM_ SG_ 820 IBS_IBATT_QUIESCENT "Battery quiescent
current";
CM_ SG_ 820 IBS_Status_Current "current Status";
CM_ SG_ 820 IBS_Status_Voltage "Voltage Status";
CM_ SG_ 820 IBS_Status_Temp "Temperature Status ";
CM_ SG_ 820 IBS_ERROR_Calib "error in calibration data";
CM_ SG_ 820 IBS_ERROR_IDENT "error in ECU indentification";
CM_ SG_ 820 IBS_Resp_Error "LIN Response Error ";
CM_ SG_ 820 IBS_FLAG_INCONSISTENCY "Battery inconsistency flag";
CM_ SG_ 821 IBS_SOC "State of Charge ";
CM_ SG_ 821 IBS_SOH_SUL "max. possible SOC, reduced by sulphation";
CM_ SG_ 821 IBS_SOFV_StopEnable "Battery voltage at cranking peak with pre-discharge";
CM_ SG_ 821 IBS_SOFV_Restart "Battery voltage at cranking peak without pre-discharge";
CM_ SG_ 821 IBS_SOH_LAM "State of health (Loss of active mass)";
CM_ SG_ 821 IBS_SOH_COR "State of health (corrosion)";
CM_ SG_ 821 IBS_SOC_STATE "SOC Status";
CM_ SG_ 821 IBS_SOH_SUL_STATE "SOH_SUL Status ";
CM_ SG_ 821 IBS_SOFV_StopEnable_STATE "SOFV_StopEnable
Status";
CM_ SG_ 821 IBS_SOFV_Restart_STATE "SOFV_Restart Status";
CM_ SG_ 821 IBS_SOH_LAM_STATE "SOH_LAM Status";
CM_ SG_ 821 IBS_SOH_COR_STATE "SOH_COR Status";
CM_ SG_ 933 HU_LanguageSet "语言设置";
CM_ SG_ 933 HU_TimeSet_DisplayMode "时间显示形式设置";
CM_ SG_ 933 HU_TimeSet_AutoMode "时间自动更新设置";
CM_ SG_ 933 HU_TBOXwelcomeReq_set "TBOX迎宾请求disable设置";
CM_ SG_ 933 HU_TimeSet_Hour "0~23:valid hour
24~31:Reserved
手动设置时间";
CM_ SG_ 933 HU_MCUPowerState "HU MCU Power State";
CM_ SG_ 933 HU_TimeSet_Minutes "0~59:valid min
60~63:Reserved
手动设置时间";
CM_ SG_ 933 HU_SOCResetType "HU SOC Reset Type";
CM_ SG_ 933 HU_HardACCState "HU Hard ACC State";
CM_ SG_ 933 HU_TBOX_Reboot "HU  Reboot TBOX";
CM_ SG_ 933 HU_mute_activests "HU反馈的语音Mute激活状态（预留）";
CM_ SG_ 933 HU_Voicecontrol_activests "HU反馈的语音激活状态（预留）";
CM_ SG_ 933 HU_SOCWatchdog "SOC Watch dog";
CM_ SG_ 933 HU_phonecall_worksts "HU反馈的电话接听挂断状态（预留）";
CM_ SG_ 933 HU_ICM_INFO_Enable "仪表提醒车辆故障功能开关";
CM_ SG_ 933 HU_BCMSystemPowerMode "HU记录的BCM电源模式";
CM_ SG_ 933 HU_RemoteCharge_StartHour "APP发送的预约充电开启时间----时
0x0-0x17: Hour
0x18-0x1E: Invalid
(不触发时发默认值，触发设置被确认时发3帧有效值，然后回到默认值）";
CM_ SG_ 933 HU_RemoteCharge_Startmin "APP发送的预约充电开启时间----分
0x0-0x3B: Minute
0x3C-0x3E: Invalid
(不触发时发默认值，触发设置被确认时发3帧有效值，然后回到默认值）
";
CM_ SG_ 933 HU_RemoteCharge_Set "定时充电开启设置";
CM_ SG_ 933 HU_ChargeCtrl_Set "立即或定时充电选择指令";
CM_ SG_ 933 HU_BatteryVoltage "HU Battery voltage";
CM_ SG_ 933 HU_SPIConnectState "SPI Connect State";
CM_ SG_ 933 HU_MCUResetReason "HU MCU Reset Reason";
CM_ SG_ 816 BCM_reversingLampSW "倒车灯状态";
CM_ SG_ 816 BCM_CarpetlampSW "地毯灯状态";
CM_ SG_ 816 BCM_CarpetlampSWSetsts "地毯灯开关设置状态";
CM_ SG_ 816 BCM_FrontdecoralampSW "前部装饰灯状态";
CM_ SG_ 816 BCM_LeftReadlampControl "左阅读灯状态";
CM_ SG_ 816 BCM_RightReadlampControl "右阅读灯状态";
CM_ SG_ 816 BCM_FloodlightControl "照明灯状态";
CM_ SG_ 816 BCM_DomeLampDoorControl "顶灯门控功能关闭设置状态";
CM_ SG_ 816 BCM_LockWelcomeSts "闭锁迎宾模式状态";
CM_ SG_ 816 BCM_PEPSLockReason "PEPS触发门锁闭锁原因，BCM_LockReason=0x2时更新此信号，BCM_LockReason非0x2时发默认发0x0";
CM_ SG_ 816 BCM_PEPSUnLockReason "PEPS触发门锁解锁原因，BCM_UnLockReason=0x2时更新此信号，BCM_UnLockReason=0x2非0x2时发默认发0x0";
CM_ SG_ 816 BCM_FollowMeControlsts "伴我回家功能开关设置状态";
CM_ SG_ 816 BCM_FollowMeDelayTSetsts "伴我回家时间设置状态";
CM_ SG_ 816 BCM_AutoLockSetsts "自动落锁功能开关设置状态";
CM_ SG_ 816 BCM_WindowAutoUPSetsts "锁车自动升四窗功能开关设置状态";
CM_ SG_ 816 BCM_FL_LED_Error "左前LED转向灯故障反馈输入状态";
CM_ SG_ 816 BCM_FR_LED_Error "右前LED转向灯故障反馈输入状态";
CM_ SG_ 816 BCM_RL_LED_Error "左后尾门LED转向灯故障反馈输入状态";
CM_ SG_ 816 BCM_RR_LED_Error "右后尾门LED转向灯故障反馈输入状态";
CM_ SG_ 816 BCM_LockReason "门锁闭锁原因";
CM_ SG_ 816 BCM_UnLockReason "门锁解锁原因";
CM_ SG_ 816 BCM_CSW_SSB_inputSts "BCM采集的CSW 的SSB 硬线信号状态";
CM_ SG_ 816 BCM_ACU_Crash_inputsts "BCM采集的ACU碰撞硬线信号状态";
CM_ SG_ 816 BCM_ESCL_UnlockFB_inputsts "BCM采集的ESCLUnlockFB硬线信号状态";
CM_ SG_ 816 BCM_ESCL_Motorpower_outputsts "BCM输出给ESCL的Motor power硬线信号状态";
CM_ SG_ 816 BCM_ESCL_LockEnable_outputsts "BCM输出给ESCL的Lock Enable硬线信号状态";
CM_ SG_ 816 BCM_ESCL_UnLockfail "ESCL 解锁失败";
CM_ SG_ 816 BCM_ESCL_Lockfail "ESCL 上锁失败";
CM_ SG_ 816 BCM_waterlightlimit "流水灯功能禁止信号";
CM_ SG_ 961 Tbox_ICM_ODOTotal "TBOX备份的ODO 总里程 (平台判断里程跳变--》异常跳变人工审核--》人工确认下发TBOX正确里程值--》TBOX收到下发ICM刷新）";
CM_ SG_ 961 Tbox_ICM_Prevmaintmileage "TBOX备份的上次保养里程";
CM_ SG_ 1281 TPMS_FL_Pressure_value " Front Left tire Pressure";
CM_ SG_ 1281 TPMS_FR_Pressure_value " Front Right tire Pressure";
CM_ SG_ 1281 TPMS_RL_Pressure_value " Rear Left tire Pressure";
CM_ SG_ 1281 TPMS_RR_Pressure_value " Rear Right tire Pressure";
CM_ SG_ 1281 TPMS_FL_Temperature " Front Left tire Temperature";
CM_ SG_ 1281 TPMS_FR_Temperature " Front Right tire Temperature";
CM_ SG_ 1281 TPMS_RR_Temperature " Rear Right tire Temperature";
CM_ SG_ 1281 TPMS_RL_Temperature " Rear Left tire Temperature";
CM_ SG_ 642 Checksum_0x282 "Checksum: IDMSB XOR IDLSB XOR Byte1 XOR Byte2 XOR Byte3 XOR Byte4 XOR Byte5 XOR Byte6XOR Byte7";
CM_ SG_ 642 SCM_LKS_Switch "车道辅助开关信号（高配）";
CM_ SG_ 642 SCM_TimeGap_Select_Switch "时距加减开关信号（高配）";
CM_ SG_ 642 SCM_ACC_Switch "自适应巡航开启/关闭开关信号（高配）";
CM_ SG_ 642 SCM_Res_Set_Switch "巡航Res+/Set-开关信号（全配）";
CM_ SG_ 642 SCM_LKS_Switch_Invalid "车道辅助开关信号（高配）无效信号";
CM_ SG_ 642 SCM_TurnIndicator_Switch "转向灯开关信号（全配）";
CM_ SG_ 642 SCM_Flash_Switch "闪光灯开关信号（全配）";
CM_ SG_ 642 SCM_Flash_Switch_Sts "闪光灯开关故障状态（全配）";
CM_ SG_ 642 SCM_HiBeam_Switch "远光灯信号（全配）";
CM_ SG_ 642 SCM_HiBeam_Switch_Sts "远光灯开关故障状态（全配）";
CM_ SG_ 642 SCM_Fwiper_Mist_Switch "前雨刮点动/洗涤开关（全配）";
CM_ SG_ 642 SCM_FWiper_Switch "前雨刮开关（全配）";
CM_ SG_ 642 SCM_RWiper_Switch "后雨刮开关（全配）";
CM_ SG_ 642 SCM_PRND_req "PRND档位请求（全配）";
CM_ SG_ 642 Counter_0x282 "RollingCounter: used 4bit length signal and the arithmetic is increased from 0 to 15 by every message.";
CM_ SG_ 373 Checksum_0x175 "Checksum: IDMSB XOR IDLSB XOR Byte1 XOR Byte2 XOR Byte3 XOR Byte4 XOR Byte5 XOR Byte6 XOR Byte7";
CM_ SG_ 373 SAS_SteerWheelAngle "The current angle of the steering wheel（Positive, to left; Negative, to right）
转向角度，左正右负";
CM_ SG_ 373 SAS_SteerWheelRotSpd "The current rotation speed of the steering wheel.
转向角速度";
CM_ SG_ 373 SAS_SteerWheelRotSpdStatus "The status of SteerWheelRotSpd
转向角速度有效性";
CM_ SG_ 373 SAS_SASStsSnsr "the flag of  SAS status
Punch:Steering angle status
SAS硬件故障状态";
CM_ SG_ 373 EPS_SteeringTorque "施加在方向盘上的驾驶员手力矩，左正右负
Driver steering torque，left+/right-";
CM_ SG_ 373 EPS_SteeringTorqueValid "Validation bit of torsion bar torque";
CM_ SG_ 373 SAS_SASStsCal "The calibration status of SAS
传感器标定状态";
CM_ SG_ 373 Rolling_counter_0x175 "RollingCounter: used 4bit length signal and the arithmetic is increased from 0 to 15 by every message.";
CM_ SG_ 279 VCU_ActualPowerPer "实际功率百分比";
CM_ SG_ 279 VCU_thermalControlReq " 电池热管理控制请求";
CM_ SG_ 279 VCU_EnergyRegLimPer "回馈功率限制百分比";
CM_ SG_ 279 VCU_InputWaterTemp "电池进水口温度";
CM_ SG_ 279 VCU_OutputWaterTemp "电池出水口温度";
CM_ SG_ 279 VCU_BattThermalReqLvl "电池包热管理需求等级，暂时定义为15个等级";
CM_ SG_ 279 VCU_RecoTiming "恢复充电倒计时";
CM_ SG_ 279 VCU_EnergyDriveLimPer "驱动功率受限百分比";
CM_ SG_ 1424 BMS_BattSerialNumber "序列号
GBT 34014-4.3.7";
CM_ SG_ 1424 BMS_BattManuYear "电池生产年
GBT 34014-4.3.6";
CM_ SG_ 1424 BMS_BattManuMonth "电池生产月
GBT 34014-4.3.6";
CM_ SG_ 1424 BMS_BattManuDay "电池生产日
GBT 34014-4.3.6";
CM_ SG_ 1425 BMS_BattSupplierCode "电池厂商代码
GBT 34014 附录A.1 ASCII码解析";
CM_ SG_ 1425 BMS_ProductTypeCode "产品类型代码
,GBT 34014 附录A.1ASCII码解析";
CM_ SG_ 1425 BMS_BattTypeCode "电池类型代码
GBT 34014 附录A.1ASCII码解析";
CM_ SG_ 1425 BMS_BattSpecCode "电池规格代码
GBT 34014 附录A.1ASCII码解析";
CM_ SG_ 1426 BMS_BattRetrospectCode "电池追溯码
GBT 34014-4.3.5";
CM_ SG_ 1427 BMS_BattProductionDate "电池生产日期";
CM_ SG_ 1427 BMS_BattS_Num "电池序列号";
CM_ SG_ 1427 BMS_BattRecycleCode "电池梯级利用代码";
CM_ SG_ 1428 BMS_BattCodeLenth "可充电储能系统编码长度
GBT 32960.3 T-6";
CM_ SG_ 1428 BMS_Temp_ProbeNum "动力蓄电池温度探针总数
GBT 32960.3 T-B.8";
CM_ SG_ 1428 BMS_PackageTotalNum "电池包总数
GBT 32960.3 T-B.6";
CM_ SG_ 1428 BMS_CellTotalNum "单体蓄电池总数
GBT 32960.3 T-B.6";
CM_ SG_ 945 TBOX_YawAngvelocity "Yaw轴角速度";
CM_ SG_ 945 TBOX_PitchAngvelocity "Pitch轴角速度";
CM_ SG_ 945 TBOX_RollAngvelocity "Roll轴角速度";
CM_ SG_ 946 TBOX_YawAcceleration "Yaw轴加速度";
CM_ SG_ 946 TBOX_PitchAcceleration "Pitch轴加速度";
CM_ SG_ 946 TBOX_RollAcceleration "Roll轴加速度";
CM_ SG_ 946 TBOX_GyroTemperature "陀螺仪温度";
CM_ SG_ 1378 MCU_MotorSts_GBT "驱动电机工作状态_GBT32960";
CM_ SG_ 1378 MCU_MotoroffsetCalReq "电机角度自学习请求";
CM_ SG_ 805 WPTC_RunSts "WPTC运行状态";
CM_ SG_ 805 WPTC_HVSts "WPTC高压供电状态";
CM_ SG_ 805 WPTC_Power "WPTC实际工作功率";
CM_ SG_ 805 WPTC_OutletTemp "WPTC出口水温";
CM_ SG_ 805 WPTC_InputTemp "WPTC进口水温";
CM_ SG_ 805 WPTC_CUR "WPTC当前运行电流";
CM_ SG_ 805 WPTC_COM_VCU_Lost "WPTC与VCU通讯丢失故障";
CM_ SG_ 805 WPTC_CUR_Over "WPTC过流故障";
CM_ SG_ 805 WPTC_Temp_PCB_High "WPTC的PCB板过温故障";
CM_ SG_ 805 WPTC_OutletTemp_High "WPTC出水口过温故障";
CM_ SG_ 805 WPTC_InputTemp_High "WPTC进水口过温故障";
CM_ SG_ 805 WPTC_PowerMaxLim "WPTC最大允许功率";
CM_ SG_ 1323 VCU_State0 "VCU状态0";
CM_ SG_ 1323 VCU_State1 "VCU状态1";
CM_ SG_ 1323 VCU_State2 "VCU状态2";
CM_ SG_ 1323 VCU_State3 "VCU状态3";
CM_ SG_ 1323 VCU_State4 "VCU状态4";
CM_ SG_ 1323 VCU_State5 "VCU状态5";
CM_ SG_ 1323 VCU_State6 "VCU状态6";
CM_ SG_ 1323 VCU_State7 "VCU状态7";
CM_ SG_ 1325 VCU_ErrorCode0 "VCU故障码0";
CM_ SG_ 1325 VCU_ErrorCode1 "VCU故障码1";
CM_ SG_ 1325 VCU_ErrorCode2 "VCU故障码2";
CM_ SG_ 1325 VCU_ErrorCode3 "VCU故障码3";
CM_ SG_ 1325 VCU_ErrorCode4 "VCU故障码4";
CM_ SG_ 1325 VCU_ErrorCode5 "VCU故障码5";
CM_ SG_ 1325 VCU_ErrorCode6 "VCU故障码6";
CM_ SG_ 1325 VCU_ErrorCode7 "VCU故障码7";
CM_ SG_ 1326 VCU_ErrorCode8 "VCU故障码8";
CM_ SG_ 1326 VCU_ErrorCode9 "VCU故障码9";
CM_ SG_ 1326 VCU_ErrorCode10 "VCU故障码10";
CM_ SG_ 1326 VCU_ErrorCode11 "VCU故障码11";
CM_ SG_ 1326 VCU_ErrorCode12 "VCU故障码12";
CM_ SG_ 1326 VCU_ErrorCode13 "VCU故障码13";
CM_ SG_ 1326 VCU_ErrorCode14 "VCU故障码14";
CM_ SG_ 1326 VCU_ErrorCode15 "VCU故障码15";
CM_ SG_ 1327 VCU_ErrorCode16 "VCU故障码16";
CM_ SG_ 1327 VCU_ErrorCode17 "VCU故障码17";
CM_ SG_ 1327 VCU_ErrorCode18 "VCU故障码18";
CM_ SG_ 1327 VCU_ErrorCode19 "VCU故障码19";
CM_ SG_ 1327 VCU_ErrorCode20 "VCU故障码20";
CM_ SG_ 1327 VCU_ErrorCode21 "VCU故障码21";
CM_ SG_ 1327 VCU_ErrorCode22 "VCU故障码22";
CM_ SG_ 1327 VCU_ErrorCode23 "VCU故障码23";
CM_ SG_ 1379 VCU_CCOut "交流充电枪信号";
CM_ SG_ 1379 VCU_MotorPumpFB_PWM "前电机水泵反馈占空比";
CM_ SG_ 1379 VCU_FastCharge_A "直流枪A+信号";
CM_ SG_ 1379 VCU_CC2 "直流枪CC2电压";
CM_ SG_ 1379 VCU_BatPumpFB_PWM "电池水泵反馈占空比";
CM_ SG_ 881 VCU_instantaneous_Energy "瞬时能耗";
CM_ SG_ 881 VCU_instantaneous_EnergyUnit "瞬时能耗单位";
CM_ SG_ 881 VCU_TrailerMode "拖车模式";
CM_ SG_ 881 VBU_BattTempLowCharge "电池低温充电提醒";
CM_ SG_ 881 VCU_trip "小计里程";
CM_ SG_ 881 VCU_ChargeIncreaseMileage "充电增加里程";
CM_ SG_ 882 VCU_SubtotalAverageEnergy "小计百公里能耗";
CM_ SG_ 882 VCU_SubtotalEnergy "小计能耗";
CM_ SG_ 882 VCU_Subtotaltime "小计里程时间";
CM_ SG_ 882 VCU_ChargeIncreaseMileageSpeed "充电里程增加速率";
CM_ SG_ 883 VCU_DST "本次里程";
CM_ SG_ 883 VCU_SingleMileageAverageEnergy "本次百公里能耗";
CM_ SG_ 883 VCU_SingleMileageEnergy "本次能耗";
CM_ SG_ 883 VCU_SingleMileagetime "本次里程时间";
CM_ SG_ 883 VCU_SlowChargeGunSt "交流枪状态";
CM_ SG_ 883 VCU_FastChargeGunSt "直流枪状态";
CM_ SG_ 154 Checksum_0x9A "Checksum: IDMSB XOR IDLSB XOR Byte1 XOR Byte2 XOR Byte3 XOR Byte4 XOR Byte5 XOR Byte6 XOR Byte7";
CM_ SG_ 154 VCU_ErrorLevel "VCU故障等级";
CM_ SG_ 154 VCU_MCU_WorkMode "VCU控制MCU工作模式";
CM_ SG_ 154 VCU_MCU_TrqReq "VCU控制电机目标扭矩";
CM_ SG_ 154 VCU_MCU_SpdReq "VCU控制电机目标转速";
CM_ SG_ 154 VCU_MotorOffsetCalCmd "电机角度自学习条件准备状态";
CM_ SG_ 154 RollingCounter_0x9A "RollingCounter: used 4bit length signal and the arithmetic is increased from 0 to 15 by every message.";
CM_ SG_ 155 Checksum_0x9B "Checksum: IDMSB XOR IDLSB XOR Byte1 XOR Byte2 XOR Byte3 XOR Byte4 XOR Byte5 XOR Byte6 XOR Byte7";
CM_ SG_ 155 VCU_BMS_WorkMode "VCU控制BMS工作模式";
CM_ SG_ 155 VCU_DC_WorkMode "VCU控制DC工作模式";
CM_ SG_ 155 VCU_WPTC_En "WPTC使能";
CM_ SG_ 155 VCU_DC_VoltageReq "VCU控制DC输出电压";
CM_ SG_ 155 VCU_WPTC_Request "WPTC开启模式请求";
CM_ SG_ 155 VCU_OBC_RemoteCharge "远程充电请求";
CM_ SG_ 155 VCU_WPTC_BatHotlPwrSet "水PTC目标功率";
CM_ SG_ 155 VCU_OBC_ChrgLock "充电枪电子锁控制命令";
CM_ SG_ 155 VCU_ChrgLockSts "VCU 电子锁状态反馈";
CM_ SG_ 155 VCU_ACU_DrvSeatBeltSWSts "VCU请求安全带信号";
CM_ SG_ 155 VCU_OBC_ChrgEnable "VCU控制OBC工作模式";
CM_ SG_ 155 Rolling_counter_0x9B "RollingCounter: used 4bit length signal and the arithmetic is increased from 0 to 15 by every message.";
CM_ SG_ 156 Checksum_0x9C "Checksum: IDMSB XOR IDLSB XOR Byte1 XOR Byte2 XOR Byte3 XOR Byte4 XOR Byte5 XOR Byte6XOR Byte7";
CM_ SG_ 156 VCU_Cruise_Sts "巡航状态";
CM_ SG_ 156 VCU_DriveInhibitAlarm "行车禁止提醒";
CM_ SG_ 156 VCU_HU_ChrgLockSts "VCU 电子锁状态反馈给HU";
CM_ SG_ 156 VCU_CCS_SpeedArm "定速巡航目标车速";
CM_ SG_ 156 VCU_SpeedLimitSWSts "车速限制功能状态";
CM_ SG_ 156 VCU_DMS_Status "驾驶员疲劳状态";
CM_ SG_ 156 VCU_DMS_SWStatus "驾驶员疲劳开关状态";
CM_ SG_ 156 VCU_LimitSpeed "当前限速值设置范围：0~200KM/H
设置的间隔：1km/h";
CM_ SG_ 156 VCU_LimitSpeedAlarm_L "限速报警光触发";
CM_ SG_ 156 VCU_LimitSpeedAlarm_V "限速报警声音触发";
CM_ SG_ 156 VCU_SlowChargeLight "VCU控制慢充充电指示灯工作模式";
CM_ SG_ 156 VCU_FastChargeLight "VCU控制快充充电指示灯工作模式";
CM_ SG_ 156 Rolling_counter_0x9C "RollingCounter: used 4bit length signal and the arithmetic is increased from 0 to 15 by every message.";
CM_ SG_ 157 VCU_AC_ComfortEAC_En "舒适性压缩机使能";
CM_ SG_ 157 VCU_AC_BatCoolEAC_En "电池冷却压缩机使能";
CM_ SG_ 157 VCU_AC_APTC_En "空气PTC使能";
CM_ SG_ 157 VCU_AC_APTCPwrSet "空气PTC目标功率";
CM_ SG_ 157 VCU_AC_EACPwrSet "压缩机目标功率";
CM_ SG_ 157 VCU_FanPWMSts "冷却风扇PWM占空比";
CM_ SG_ 157 VCU_BattPump_ErrorSts "电池水泵故障状态";
CM_ SG_ 157 VCU_RemoteACFeedback "远程空调反馈";
CM_ SG_ 157 VCU_FanSts "风扇状态";
CM_ SG_ 157 VCU_12VbatterySOHLow "12V Battery SOH Low";
CM_ SG_ 157 VCU_LVSmartChrg_Status "VCU LV Smart Charge Status";
CM_ SG_ 321 Checksum_0x141 "Checksum: IDMSB XOR IDLSB XOR Byte1 XOR Byte2 XOR Byte3 XOR Byte4 XOR Byte5 XOR Byte6 XOR Byte7";
CM_ SG_ 321 VCU_DriverDemandTorq "Motor torque requested by driver or cruise control, reduced by motor drag torque and torque consumption of auxiliary devices";
CM_ SG_ 321 VCU_QECACC "VCU响应VLC扭矩控制的状态";
CM_ SG_ 321 VCU_CreepSwitch "蠕行开关(预留）";
CM_ SG_ 321 VCU_OnepedalSetEn "单踏板模式设置使能";
CM_ SG_ 321 VCU_GearShiftInProgress "Gear shifting Progress";
CM_ SG_ 321 VCU_ShiftInProgress_Status "Gear shift in progress status";
CM_ SG_ 321 VCU_AccelerationModePer "加速模式百分比，范围：0-100%
精度：1%";
CM_ SG_ 321 VCU_OverRide "Indicating the torque demanded by the driver is higher than the torque demanded by ACC.
指示驾驶员要求的扭矩高于ACC所要求的扭矩";
CM_ SG_ 321 VCU_DriveMode "整车驾驶模式";
CM_ SG_ 321 VCU_APA_LC_Availability "VCU_APA_LC_Availability";
CM_ SG_ 321 VCU_APA_LC_FailureSts "VCU_APA_LC_FailureSts";
CM_ SG_ 321 VCU_E_Pedalwarn "单踏板设置提示";
CM_ SG_ 321 VCU_ChargeDepthwarn "充电深度设置提示";
CM_ SG_ 321 VCU_EPB_FunctionSet "VCU请求EPB控制";
CM_ SG_ 321 VCU_APA_LC_Status "VCU_APA_LC_Status";
CM_ SG_ 321 Rollingcounter_0x141 "从0到15循环计数，如果通信中断，则重新从0开始计数。";
CM_ SG_ 336 Checksum_0x150 "Checksum: IDMSB XOR IDLSB XOR Byte1 XOR Byte2 XOR Byte3 XOR Byte4 XOR Byte5 XOR Byte6 XOR Byte7";
CM_ SG_ 336 VCU_GearLeverPos "实际档位";
CM_ SG_ 336 VCU_TortoiseLamp "龟灯信号";
CM_ SG_ 336 VCU_Charge_Connect "充电枪连接";
CM_ SG_ 336 VCU_12VbatteryError "12V蓄电池故障";
CM_ SG_ 336 VCU_ReadySts "Ready信号";
CM_ SG_ 336 VCU_MotorPumpError "电机水泵故障";
CM_ SG_ 336 VCU_VacuumSysFaultLamp "真空系统故障灯";
CM_ SG_ 336 VCU_GearP_EnterWarning "P档无法进入提醒";
CM_ SG_ 336 VCU_VehicleSysFaultLamp "整车系统故障";
CM_ SG_ 336 VCU_BattPumpError "电池水泵故障";
CM_ SG_ 336 VCU_DriveableAlarm "可行驶状态报警信号";
CM_ SG_ 336 VCU_GearFlashReq "换挡提示";
CM_ SG_ 336 VCU_EnergyRecoveryPer "能量回收强度百分比";
CM_ SG_ 336 VCU_ShowCarMod "展车模式";
CM_ SG_ 336 VCU_Mileage "续航里程";
CM_ SG_ 336 VCU_PowerConsumption "百公里电耗";
CM_ SG_ 336 VCU_MotorLoopCoolantLow "电机回路冷却液过低报警";
CM_ SG_ 336 VCU_BatLoopCoolantLow "电池回路冷却液过低报警";
CM_ SG_ 336 VCU_ChargeDepthSts "充电深度设置状态";
CM_ SG_ 336 VCU_CloolantHighAlarm "冷却液温度过高报警";
CM_ SG_ 336 VCU_TBOX_SlowChargeSt "交流充电反馈";
CM_ SG_ 336 Rollingcounter_0x150 "从0到15循环计数，如果通信中断，则重新从0开始计数。";
CM_ SG_ 337 Checksum_0x151 "Checksum: IDMSB XOR IDLSB XOR Byte1 XOR Byte2 XOR Byte3 XOR Byte4 XOR Byte5 XOR Byte6XOR Byte7";
CM_ SG_ 337 VCU_HVLock_ALL "VCU高压互锁信号(综合）";
CM_ SG_ 337 VCU_BrakeLampReq "点亮制动灯请求";
CM_ SG_ 337 VCU_Intelligent_Charge_Sts "智能充电状态";
CM_ SG_ 337 VCU_HVLock_self "VCU高压互锁信号（VCU检测）";
CM_ SG_ 337 VCU_MotorPump_ErrorSts "电机水泵故障状态";
CM_ SG_ 337 VCU_BrkSw_Sts "制动踏板开关状态
Brake pedal switch Status";
CM_ SG_ 337 VCU_BrkPed_Pos "制动踏板位置度信号";
CM_ SG_ 337 VCU_AtmosphePressValue "大气压力值";
CM_ SG_ 337 VCU_AccSW_Sts "油门踏板开关状态";
CM_ SG_ 337 VCU_AccPedPos "油门踏板位置度
Accelerator pedal position";
CM_ SG_ 337 VCU_TargetGear "VCUtarget gear";
CM_ SG_ 337 VCU_APS_WorkStatus "VCU反馈给APS的工作状态";
CM_ SG_ 337 Rolling_counter_0x151 "RollingCounter: used 4bit length signal and the arithmetic is increased from 0 to 15 by every message.";
CM_ SG_ 401 Checksum_0x191 "Checksum: IDMSB XOR IDLSB XOR Byte1 XOR Byte2 XOR Byte3 XOR Byte4 XOR Byte5 XOR Byte6 XOR Byte7";
CM_ SG_ 401 APS_SystemSts "APA功能内部状态
";
CM_ SG_ 401 APS_Active "APA功能是否激活";
CM_ SG_ 401 APS_VCU_BrakeFunctionMode "制动功能模式";
CM_ SG_ 401 APS_AVM_HU_Failure "AVM系统故障，不能进入AVM模式";
CM_ SG_ 401 APS_VCU_BrakeModeSts "制动模式状态";
CM_ SG_ 401 APS_VCU_Speed_Limitation "APS限速值";
CM_ SG_ 401 APS_VCU_Target_Gear_Request "目标档位";
CM_ SG_ 401 AVM_ControlRequest "AVM进入退出控制请求";
CM_ SG_ 401 APS_HU_ParkPrompttone "找到车位提示音";
CM_ SG_ 401 APS_VCU_APAFailed "APA反馈VCU的故障状态";
CM_ SG_ 401 AVM_SoftKeyResponse "AVM软开关响应";
CM_ SG_ 401 AVM_FactoryMode "AVM工厂模式状态";
CM_ SG_ 401 APS_ParkOutDirection "泊出方向";
CM_ SG_ 401 APS_TBOXConect_ParkInResp "接收TBOX与手机的连接状态，并反馈给TBOX，作为APP端发起请求遥控泊入的前提条件之一";
CM_ SG_ 401 APS_VCU_FailureBrakeMode "刹车模式失效状态";
CM_ SG_ 401 APS_VCU_Stop_Distance "停车距离";
CM_ SG_ 401 APS_R_Gear_RequestTips "换入R档请求";
CM_ SG_ 401 APS_VCU_Req_StraightOut "APS请求遥控直出或者直入的握手请求";
CM_ SG_ 401 APS_VCU_Gear_Request "APS请求换挡";
CM_ SG_ 401 APS_VCU_Req_StraightCtrol "APS请求遥控直出、直入或者停止命令";
CM_ SG_ 401 RollingCounter_0x191 "RollingCounter: used 4bit length signal and the arithmetic is increased from 0 to 15 by every message.";
CM_ SG_ 401 APS_TBOX_PowerOffResp "返回TBOX电源状态";
CM_ SG_ 401 APS_TBOX_PowerOffReqResp "对TBOX下电请求的响应";
CM_ SG_ 624 Checksum_0x270 "Checksum: IDMSB XOR IDLSB XOR Byte1 XOR Byte2 XOR Byte3 XOR Byte4 XOR Byte5 XOR Byte6 XOR Byte7";
CM_ SG_ 624 APS_TrgtEPSStrgWhlAng "Advanced Park Assist Target Electric Power Steering Steering Wheel Angle
APA需求的目标转向角度";
CM_ SG_ 624 APS_APAFailed "Advanced Park Assist Failed 
APA故障";
CM_ SG_ 624 APS_CmdEPSSts "Advanced Park Assist Command Electric Power Steering Status
APA状态";
CM_ SG_ 624 APS_FailureBrakeMode "APS_FailureBrakeMode";
CM_ SG_ 624 APS_BrakeModeSts "APS_BrakeModeSts
";
CM_ SG_ 624 APS_ESP_Stop_Distance "APA对ESP请求的目标停车距离";
CM_ SG_ 624 APS_BrakeFunctionMode "APS_BrakeFunctionMode";
CM_ SG_ 624 APS_ESP_Speed_Limitation "APA对ESP请求的最大允许车速";
CM_ SG_ 624 RollingCounter_0x270 "RollingCounter: used 4bit length signal and the arithmetic is increased from 0 to 15 by every message.";
CM_ SG_ 624 APS_ESC_Target_Gear_Request "
APA请求的目标档位信号";
CM_ SG_ 625 Checksum_0x271 "Checksum: IDMSB XOR IDLSB XOR Byte1 XOR Byte2 XOR Byte3 XOR Byte4 XOR Byte5 XOR Byte6 XOR Byte7";
CM_ SG_ 625 APS_AVM_AutoSearchSts "自动泊车车位搜寻状态";
CM_ SG_ 625 APS_AVM_ParkOutChkResult "当前是否满足泊出条件";
CM_ SG_ 625 APS_AVM_CurrentPathNum "本次泊车中的当前所处路径数";
CM_ SG_ 625 APS_AVM_TotalPathNum "本次泊车需要的总路径数";
CM_ SG_ 625 APS_AVM_SuspendedReason "主动泊车暂停原因";
CM_ SG_ 625 APS_AVM_AbortReason "主动泊车中止原因";
CM_ SG_ 625 APS_AVM_CurrentParkType "当前选择的泊车类型";
CM_ SG_ 625 APS_AVM_OverrideReason "主动泊车驾驶员介入原因";
CM_ SG_ 625 APS_AVM_VehicleDirection "在当前路径中车辆行驶方向";
CM_ SG_ 625 APS_AVM_TerminatedType "APA终止类型";
CM_ SG_ 625 APS_AVM_ParkOutSystemStatus "APA泊出系统状态";
CM_ SG_ 625 APS_AVM_CurrentStepNum "在当前路径中所处的步数";
CM_ SG_ 625 APS_RemoteParkIn_Status "遥控泊入状态";
CM_ SG_ 625 APS_RemoteParkInResp "响应APP的遥控泊入请求";
CM_ SG_ 625 APS_BCM_RemoteParkIn_Status "APS请求BCM控制状态位";
CM_ SG_ 625 APS_BCM_DoubleFlash "APS请求BCM双闪";
CM_ SG_ 625 APS_BCM_AllDoorUnLock_Door "APS请求BCM解锁";
CM_ SG_ 625 APS_RemoteParkOutResp "响应APP的遥控泊出请求";
CM_ SG_ 625 APS_BCM_PowerOffReq "遥控泊车完成后下电请求发送给BCM";
CM_ SG_ 625 APS_RemotePark_Error_Status "遥控泊车故障";
CM_ SG_ 625 RollingCounter_0x271 "RollingCounter: used 4bit length signal and the arithmetic is increased from 0 to 15 by every message.";
CM_ SG_ 625 APS_APP_StraightOut_Status "直入直出状态（预留）";
CM_ SG_ 920 ORM_LeftMirrorMotor1fault "左侧后视镜上下调节电机故障";
CM_ SG_ 920 ORM_LeftMirrorMotor2fault "左侧后视镜左右调节电机故障";
CM_ SG_ 920 ORM_RightMirrorMotor1fault "右侧后视镜上下调节电机故障";
CM_ SG_ 920 ORM_RightMirrorMotor2fault "右侧后视镜左右调节电机故障";
CM_ SG_ 800 EAC_power "压缩机工作功率";
CM_ SG_ 800 EAC_StartSts_F "Compressor state：start error
电动压缩机控制器状态：起动失败";
CM_ SG_ 800 EAC_UnderVoltage_F "Compressor state：under vol
电动压缩机控制器状态：运行欠压";
CM_ SG_ 800 EAC_OverVoltage_F "Compressor state：over vol
电动压缩机控制器状态：运行过压。";
CM_ SG_ 800 EAC_OverCurrent_F "Compressor state：over current
电动压缩机控制器状态：过流";
CM_ SG_ 800 EAC_OverTemp_F "Compressor state：over temperature
电动压缩机控制器状态：过温";
CM_ SG_ 800 EAC_Status "Compressor state：压缩机状态位";
CM_ SG_ 800 EAC_StandbyUnderVol_F "Standby under Voltage
压缩机待机欠压";
CM_ SG_ 800 EAC_StandbyOverVol_F "Standby over Voltage
压缩机待机过压";
CM_ SG_ 800 EAC_Communication_Error "Communication Error
通信故障";
CM_ SG_ 800 EAC_OverCurrentDropFreq "Over Current Drop Frequency
过流降频";
CM_ SG_ 800 EAC_OverPeakCurrent "Over Peak Current 
峰值电流保护";
CM_ SG_ 800 EAC_Current "Compressor current
电动压缩机控制器当前运行电流（母线电流）";
CM_ SG_ 800 EAC_Voltage "Compressor voltage
电动压缩机控制器当前运行电压（母线电压）";
CM_ SG_ 800 EAC_Speed "Compressor speed
电动压缩机控制器当前运行速度";
CM_ SG_ 806 APTC_WorkSts "APTC工作状态";
CM_ SG_ 806 APTC_WorkPower "APTC实际工作功率";
CM_ SG_ 806 APTC_SurfaceTemp "APTC表面温度";
CM_ SG_ 806 APTC_PCBTemp "PCB板温度信号";
CM_ SG_ 806 APTC_Curent "APTC当前运行电流";
CM_ SG_ 806 APTC_ErrorCode "APTC运行故障代码";
CM_ SG_ 806 APTC_HVSts "APTC高压供电状态";
CM_ SG_ 806 APTC_ErrorLevel "APTC故障等级";
CM_ SG_ 735 HU_SetMemoryReq "座椅记忆设置请求";
CM_ SG_ 735 HU_DeleteMemoryReq "座椅记忆删除请求";
CM_ SG_ 735 HU_GetMemoryReq "记忆调用请求(关联ID)";
CM_ SG_ 735 HU_DirverSLV_Direction_set "驾驶侧座椅前后调节";
CM_ SG_ 735 HU_DirverSHV_Direction_set "驾驶侧座椅高度调节";
CM_ SG_ 735 HU_DirverLNV_Direction_set "驾驶侧靠背前倾后倾调节";
CM_ SG_ 735 HU_PassagerSLV_Direction_set "副驾驶侧座椅前后调节";
CM_ SG_ 735 HU_PassagerSHV_Direction_set "副驾驶侧座椅高度调节";
CM_ SG_ 735 HU_PassagerLNV_Direction_set "副驾驶侧靠背前倾后倾调节";
CM_ SG_ 735 HU_DSM_heatSwitch "主驾座椅加热开关";
CM_ SG_ 735 HU_DSM_Targtemp "驾驶侧座椅目标温度";
CM_ SG_ 735 HU_PSM_heatSwitch "副驾驶座椅加热开关";
CM_ SG_ 735 HU_PSM_Targtemp "副驾驶侧座椅目标温度";
CM_ SG_ 735 HU_DSMEasyEntrySW "座椅迎宾功能开关";
CM_ SG_ 735 HU_RVMAutoFoldSW "外后视镜自动折叠功能开关";
CM_ SG_ 735 HU_RVMFoldButton "外后视镜折叠按钮";
CM_ SG_ 735 HU_RVM_R_DownSW "外后视镜倒车自动向下翻功能开关";
CM_ SG_ 735 HU_Userdefined_Mirror "方向盘自定义按键-后视镜控制";
CM_ SG_ 928 ICM_ODOTotal "ODO 总里程 ";
CM_ SG_ 928 ICM_DisPlayVehicleSpeed "Current Display Vehicle Speed
仪表当前显示车速";
CM_ SG_ 928 ICM_LowBrakeFluidLevel "制动液位低";
CM_ SG_ 928 ICM_WashingLiquidLevel "洗涤液位低";
CM_ SG_ 928 ICM_maintenanceState "整车保养状态";
CM_ SG_ 928 ICM_INFO_Enablests "仪表提醒车辆故障功能开关状态";
CM_ SG_ 928 ICM_instantaneous_power "瞬时功率";
CM_ SG_ 928 ICM_ODOTotalFB "ICM反馈的TBOX下发的总里程是否处理成功";
CM_ SG_ 928 ICM_Error_Sts "ICM故障状态";
CM_ SG_ 928 ICM_PrevmaintmileagesFB "ICM反馈的TBOX下发的保养里程是否处理成功";
CM_ SG_ 928 ICM_Display_Mode "ICM白天夜晚模式切换";
CM_ SG_ 928 ICM_SubMileage_Reset "小计里程重置";
CM_ SG_ 896 SRF_MD1_Position "玻璃板位置，MD1开启位置百分比，BCM接收LIN1子网SRF_0x06报文SRF_MD1_Position信号转发至Body CAN";
CM_ SG_ 896 SRF_MD1_Lage "玻璃板位置标志位,BCM接收LIN1子网SRF_0x06报文SRF_MD1_Lage信号转发至Body CAN";
CM_ SG_ 896 SRF_MD1_Sleflearnsuccessfully "初始化标志位,BCM接收LIN1子网SRF_0x06报文SRF_MD1_Sleflearnsuccessfully信号转发至Body CAN";
CM_ SG_ 896 SRF_MD1_FunctionAbort "功能中断标志位,BCM接收LIN1子网SRF_0x06报文SRF_MD1_FunctionAbort 信号转发至Body CAN";
CM_ SG_ 896 SRF_MD1_drive_detect "EEPROM/HALL故障等标志位,BCM接收LIN1子网SRF_0x06报文SRF_MD1_drive_detect信号转发至Body CAN";
CM_ SG_ 896 SRF_MD1_ResponseError "SRF LIN通信错误,BCM接收LIN1子网SRF_0x06报文SRF_MD1_ResponseError 信号转发至Body CAN";
CM_ SG_ 896 SRF_RoofRunningStatus "玻璃板运行状态标志位,BCM接收LIN1子网SRF_0x06报文SRF_RoofRunningStatus信号转发至Body CAN";
CM_ SG_ 896 RLS_RQ_LowBeam "Auto low beam request 近光灯点亮请求，This signal delivers information about  temperature in car : 车内温度,BCM接收LIN1子网RLS_0x23报文RLS_RQ_LowBeam信号转发至Body CAN";
CM_ SG_ 896 RLS_RQ_PositionLamp "Auto position lamp request 位置灯点亮请求，This signal delivers information about  temperature in car : 车内温度,BCM接收LIN1子网RLS_0x23报文RLS_RQ_PositionLamp信号转发至Body CAN";
CM_ SG_ 896 SHD_MRollo_FunctionAbort "功能中断标志位,BCM接收LIN1子网SHD_0x07报文SHD_MRollo_FunctionAbort 信号转发至Body CAN";
CM_ SG_ 896 SHD_MRollo_Driver_detect "EEPROM/HALL故障等标志位,BCM接收LIN1子网SHD_0x07报文SHD_MRollo_Driver_detect信号转发至Body CAN";
CM_ SG_ 896 SHD_MRollo_ResponseError "SHD LIN通信错误,BCM接收LIN1子网SHD_0x07报文SHD_MRollo_ResponseError信号转发至Body CAN";
CM_ SG_ 896 SHD_ShadeRunningStatus "遮阳帘运行状态标志位,BCM接收LIN1子网SHD_0x07报文SHD_ShadeRunningStatus信号转发至Body CAN";
CM_ SG_ 896 SHD_ShadePosReached "遮阳帘位置标志位,BCM接收LIN1子网SHD_0x07报文SHD_ShadePosReached信号转发至Body CAN";
CM_ SG_ 896 RLS_Fault_Rain "Rain sensor fault status 雨量传感器故障状态,BCM接收LIN1子网RLS_0x23报文RLS_Fault_Rain信号转发至Body CAN";
CM_ SG_ 896 SHD_MRollo_Position "遮阳帘开启百分比,0x0~0x64: Position percent of open，,BCM接收LIN1子网SHD_0x07报文SHD_MRollo_Position信号转发至Body CAN";
CM_ SG_ 896 SHD_MRollo_Sleflearnsuccessfully "初始化标志位,BCM接收LIN1子网SHD_0x07报文SHD_MRollo_Sleflearnsuccessfully信号转发至Body CAN";
CM_ SG_ 896 RLS_Brightness_FW "The Visible Ambientlight (540nm) measured by Spot FW 可见环境光亮度,BCM接收LIN1子网RLS_0x23报文RLS_Brightness_FW信号转发至Body CAN";
CM_ SG_ 896 RLS_Fault_Light "Light sensor fault status 光亮传感器故障状态,BCM接收LIN1子网RLS_0x23报文RLS_Fault_Light信号转发至Body CAN";
CM_ SG_ 896 RLS_ResponseError "RLS LIN response error RLS通讯故障状态,BCM接收LIN1子网RLS_0x23报文RLS_ResponseError 信号转发至Body CAN";
CM_ SG_ 896 RLS_Rain_Intensity "This signal delivers information about rain intensity: from 0%(no rain) to 100% (very heavy rain) 降雨强度：从0%到100%,BCM接收LIN1子网RLS_0x23报文RLS_Rain_Intensity信号转发至Body CAN";
CM_ SG_ 896 RLS_Temperature "This signal delivers information about  temperature in car : 车内温度,BCM接收LIN1子网RLS_0x23报文RLS_Temperature信号转发至Body CAN";
CM_ SG_ 896 RLS_Humid "This signal delivers information about air humid : from 0% to 100%
空气湿度：从0%到100%,BCM接收LIN1子网RLS_0x23报文RLS_Humid信号转发至Body CAN";
CM_ SG_ 784 BCM_SystemPowerMode "整车电源状态
vehicle Power Status";
CM_ SG_ 784 BCM_AntiThelf_Sts "车辆设防状态";
CM_ SG_ 784 BCM_DriverLock_Sts "驾驶侧门锁状态";
CM_ SG_ 784 BCM_StartRequest "整车ready请求信号（默认发0x0，请求启动时发0x1，连续发10帧，之后重新发0x0）";
CM_ SG_ 784 BCM_partialarmed_ActiveSts "局部设防激活状态";
CM_ SG_ 784 BCM_Hood_Sts "前舱盖状态";
CM_ SG_ 784 BCM_ChargerLock_ControlSts "充电口锁控制输出状态";
CM_ SG_ 784 BCM_PositionLight_Sts "位置灯状态";
CM_ SG_ 784 BCM_TurnLeftLight_Sts "左转向灯状态";
CM_ SG_ 784 BCM_TurnRightLight_Sts "右转向灯状态";
CM_ SG_ 784 BCM_Daylight_Sts "日间行车灯状态";
CM_ SG_ 784 BCM_HighBeam_Sts "远光灯状态";
CM_ SG_ 784 BCM_LowBeam_Sts "近光灯状态";
CM_ SG_ 784 BCM_AutoHeadlight_Sts "BCM反馈的是否执行HU 的Auto灯请求信号";
CM_ SG_ 784 BCM_brakeLight_Sts "制动灯状态";
CM_ SG_ 784 BCM_HazardLight_Sts "危险报警指示灯状态";
CM_ SG_ 784 BCM_RearFoglight_Sts "后雾灯状态";
CM_ SG_ 784 BCM_BrkSw_Sts "BCM采集的制动踏板开关状态";
CM_ SG_ 784 BCM_FL_Door_Sts "左前门状态";
CM_ SG_ 784 BCM_FR_Door_Sts "右前门状态";
CM_ SG_ 784 BCM_RL_Door_Sts "左后门状态";
CM_ SG_ 784 BCM_RR_Door_Sts "右后门状态";
CM_ SG_ 784 BCM_Trunk_Door_Sts "后背门状态（低配）";
CM_ SG_ 784 BCM_PLGOutsideSW "BCM采集的后背门外侧开关信号";
CM_ SG_ 784 BCM_HornControlsts "鸣笛控制状态";
CM_ SG_ 784 BCM_Fwiper_Mist_Sts "前雨刮点动状态";
CM_ SG_ 784 BCM_Fwiper_washing_Sts "前雨刮洗涤状态";
CM_ SG_ 784 BCM_RKE_lock_Unlock_req "智能钥匙遥控解闭锁请求（触发FOB闭锁或解锁按键时发送8帧0x1或0x2之后默认发送0x0）";
CM_ SG_ 784 BCM_FWiper_Sts "前雨刮状态";
CM_ SG_ 784 BCM_RWiper_Sts "后雨刮状态";
CM_ SG_ 784 BCM_RearViewFoldSts "外后视镜折叠状态（控制状态非实际状态）";
CM_ SG_ 784 BCM_RearViewAutoSWSts "外后视镜自动折叠功能使能状态";
CM_ SG_ 784 BCM_RearViewHeatSts "外后视镜加热/后除霜状态";
CM_ SG_ 784 BCM_WorkMode "BCM工作模式";
CM_ SG_ 784 BCM_TBOXUnlockEnableSts "TBOX发解锁命令后，BCM反馈的解锁使能状态";
CM_ SG_ 784 BCM_FwiperServiceSWsts "雨刮维修模式状态";
CM_ SG_ 784 BCM_PowerONorOFF_Reason "BCM上电(（ACC或者IG1继电器从断开到闭合）及下电（ACC或者IG1继电器从闭合到断开）原因";
CM_ SG_ 784 BCM_SupplyVoltage "BCM供电电压";

BA_DEF_ BO_  "NmMessage" ENUM "No","Yes";
BA_DEF_ BO_  "GenMsgSendType" ENUM  "cyclic","IfActive","Event","CA","CE","NoMsgSendType";
BA_DEF_ BO_  "GenMsgCycleTime" INT 0 0;
BA_DEF_ SG_  "GenSigSendType" ENUM  "cyclic","OnChange","OnWrite","IfActive","OnChangeWithRepetition","OnWriteWithRepetition","IfActiveWithRepetition","NoSigSendType","OnChangeAndIfActive", "OnChangeAndIfActiveWithRepetition","CA","CE","Event";
BA_DEF_ SG_  "GenSigStartValue" INT 0 0;
BA_DEF_  "DBName" STRING ;
BA_DEF_ BU_  "NodeLayerModules" STRING ;
BA_DEF_ BU_  "NmNode" ENUM  "Not","Yes";
BA_DEF_  "NmBaseAddress" HEX 0 2047;
BA_DEF_  "NmMessageCount" INT 0 255;
BA_DEF_  "BusType" STRING ;

BA_DEF_DEF_  "NmMessage" "No";
BA_DEF_DEF_  "GenMsgSendType" "cyclic";
BA_DEF_DEF_  "GenMsgCycleTime" 0;
BA_DEF_DEF_  "GenSigSendType" "cyclic";
BA_DEF_DEF_  "GenSigStartValue" 0;
BA_DEF_DEF_  "DBName" "";
BA_DEF_DEF_  "NodeLayerModules" "CANoeILNLVector.dll";
BA_DEF_DEF_  "NmNode" "Not";
BA_DEF_DEF_  "NmBaseAddress" 1024;
BA_DEF_DEF_  "NmMessageCount" 128;
BA_DEF_DEF_  "BusType" "CAN";
BA_ "DBName" "ME7_TboxCAN_CMatrix_V310.210712_500km";
BA_ "GenMsgCycleTime" BO_ 276 100;
BA_ "GenSigStartValue" SG_ 276 BMS_InputWaterTemp 255;
BA_ "GenSigStartValue" SG_ 276 BMS_OutputWaterTemp 255;
BA_ "GenMsgCycleTime" BO_ 608 100;
BA_ "GenSigStartValue" SG_ 608 EPS_SafeLampRed 1;
BA_ "GenMsgCycleTime" BO_ 375 10;
BA_ "GenMsgCycleTime" BO_ 374 10;
BA_ "GenMsgCycleTime" BO_ 580 20;
BA_ "GenMsgCycleTime" BO_ 529 20;
BA_ "GenMsgCycleTime" BO_ 913 100;
BA_ "GenMsgCycleTime" BO_ 1285 500;
BA_ "GenSigStartValue" SG_ 1285 VCU_NM_SLEEP_Ind 1;
BA_ "GenSigStartValue" SG_ 1285 AC_NM_SLEEP_Ind 1;
BA_ "GenSigStartValue" SG_ 1285 APL_NM_SLEEP_Ind 1;
BA_ "GenSigStartValue" SG_ 1285 DVR_NM_SLEEP_Ind 1;
BA_ "GenSigStartValue" SG_ 1285 HU_NM_SLEEP_Ind 1;
BA_ "GenSigStartValue" SG_ 1285 ICM_NM_SLEEP_Ind 1;
BA_ "GenSigStartValue" SG_ 1285 ORM_NM_SLEEP_Ind 1;
BA_ "GenSigStartValue" SG_ 1285 RSE_NM_SLEEP_Ind 1;
BA_ "GenSigStartValue" SG_ 1285 BCM_NM_SLEEP_Ind 1;
BA_ "GenSigStartValue" SG_ 1285 DSM_NM_SLEEP_Ind 1;
BA_ "GenSigStartValue" SG_ 1285 PLG_NM_SLEEP_Ind 1;
BA_ "GenSigStartValue" SG_ 1285 TBOX_NM_SLEEP_Ind 1;
BA_ "GenMsgCycleTime" BO_ 406 100;
BA_ "GenMsgCycleTime" BO_ 579 20;
BA_ "GenMsgCycleTime" BO_ 734 100;
BA_ "GenSigSendType" SG_ 734 HU_DriveMode 1;
BA_ "GenSigSendType" SG_ 734 HU_RemoteCharge_EndHour 1;
BA_ "GenSigStartValue" SG_ 734 HU_RemoteCharge_EndHour 31;
BA_ "GenSigSendType" SG_ 734 HU_RemoteCharge_Endmin 1;
BA_ "GenSigStartValue" SG_ 734 HU_RemoteCharge_Endmin 63;
BA_ "GenSigSendType" SG_ 734 HU_RemotCh_Full_SetSts 1;
BA_ "GenMsgCycleTime" BO_ 404 50;
BA_ "GenMsgCycleTime" BO_ 405 50;
BA_ "GenMsgCycleTime" BO_ 597 100;
BA_ "GenMsgSendType" BO_ 64 2;
BA_ "GenSigSendType" SG_ 64 PEPS_RKECommand 1;
BA_ "GenSigSendType" SG_ 64 PEPS_DoorUnlockReq 1;
BA_ "GenSigSendType" SG_ 64 PEPS_DoorlockReq 1;
BA_ "GenSigSendType" SG_ 64 PEPS_TrunkReleaseReq 1;
BA_ "GenMsgCycleTime" BO_ 1377 100;
BA_ "GenMsgCycleTime" BO_ 1324 200;
BA_ "GenMsgCycleTime" BO_ 912 100;
BA_ "GenSigStartValue" SG_ 912 DSM_PSMsettemp 34;
BA_ "GenSigStartValue" SG_ 912 DSM_DSMsettemp 34;
BA_ "GenMsgCycleTime" BO_ 852 100;
BA_ "GenMsgCycleTime" BO_ 546 50;
BA_ "GenSigSendType" SG_ 546 PEPS_WarningKeyNotInCar 1;
BA_ "GenSigSendType" SG_ 546 PEPS_WarningKeyInCar 1;
BA_ "GenSigSendType" SG_ 546 PEPS_WarningIgNotOff 1;
BA_ "GenSigSendType" SG_ 546 PEPS_WarningKeyLowBattery 1;
BA_ "GenSigSendType" SG_ 546 PEPS_WarningStartupNotBrake 1;
BA_ "GenSigSendType" SG_ 546 PEPS_WarningKeyNearbyIMMO 1;
BA_ "GenSigSendType" SG_ 546 PEPS_PassiveWindowCom 1;
BA_ "GenSigSendType" SG_ 546 PEPS_KeyPosition 1;
BA_ "GenSigSendType" SG_ 546 PEPS_DHA_LeftHandleSwitch 1;
BA_ "GenSigSendType" SG_ 546 PEPS_PHA_RightHandleSwitch 1;
BA_ "GenMsgCycleTime" BO_ 820 100;
BA_ "GenSigStartValue" SG_ 820 IBS_U_BATT 16383;
BA_ "GenSigStartValue" SG_ 820 IBS_I_Range 3;
BA_ "GenSigStartValue" SG_ 820 IBS_I_BATT 65535;
BA_ "GenSigStartValue" SG_ 820 IBS_T_BATT 255;
BA_ "GenSigStartValue" SG_ 820 IBS_IBATT_QUIESCENT 255;
BA_ "GenMsgCycleTime" BO_ 821 100;
BA_ "GenSigStartValue" SG_ 821 IBS_SOC 255;
BA_ "GenSigStartValue" SG_ 821 IBS_SOH_SUL 255;
BA_ "GenSigStartValue" SG_ 821 IBS_SOFV_StopEnable 255;
BA_ "GenSigStartValue" SG_ 821 IBS_SOFV_Restart 255;
BA_ "GenSigStartValue" SG_ 821 IBS_SOH_LAM 255;
BA_ "GenSigStartValue" SG_ 821 IBS_SOH_COR 255;
BA_ "GenSigStartValue" SG_ 821 IBS_SOC_STATE 3;
BA_ "GenSigStartValue" SG_ 821 IBS_SOH_SUL_STATE 3;
BA_ "GenSigStartValue" SG_ 821 IBS_SOFV_StopEnable_STATE 3;
BA_ "GenSigStartValue" SG_ 821 IBS_SOFV_Restart_STATE 3;
BA_ "GenSigStartValue" SG_ 821 IBS_SOH_LAM_STATE 3;
BA_ "GenSigStartValue" SG_ 821 IBS_SOH_COR_STATE 3;
BA_ "GenMsgCycleTime" BO_ 933 100;
BA_ "GenSigSendType" SG_ 933 HU_LanguageSet 1;
BA_ "GenSigSendType" SG_ 933 HU_TBOXwelcomeReq_set 1;
BA_ "GenSigSendType" SG_ 933 HU_TBOX_Reboot 1;
BA_ "GenSigSendType" SG_ 933 HU_ICM_INFO_Enable 1;
BA_ "GenSigSendType" SG_ 933 HU_BCMSystemPowerMode 1;
BA_ "GenSigSendType" SG_ 933 HU_RemoteCharge_StartHour 1;
BA_ "GenSigSendType" SG_ 933 HU_RemoteCharge_Startmin 1;
BA_ "GenSigSendType" SG_ 933 HU_RemoteCharge_Set 1;
BA_ "GenSigSendType" SG_ 933 HU_ChargeCtrl_Set 1;
BA_ "GenMsgCycleTime" BO_ 816 100;
BA_ "GenMsgCycleTime" BO_ 961 200;
BA_ "GenSigSendType" SG_ 961 Tbox_ICM_ODOTotal 1;
BA_ "GenSigSendType" SG_ 961 Tbox_ICM_Prevmaintmileage 1;
BA_ "GenMsgCycleTime" BO_ 1281 100;
BA_ "GenSigStartValue" SG_ 1281 TPMS_FL_Pressure_value 255;
BA_ "GenSigStartValue" SG_ 1281 TPMS_FR_Pressure_value 255;
BA_ "GenSigStartValue" SG_ 1281 TPMS_RL_Pressure_value 255;
BA_ "GenSigStartValue" SG_ 1281 TPMS_RR_Pressure_value 255;
BA_ "GenSigStartValue" SG_ 1281 TPMS_FL_Temperature 255;
BA_ "GenSigStartValue" SG_ 1281 TPMS_FR_Temperature 255;
BA_ "GenSigStartValue" SG_ 1281 TPMS_RR_Temperature 255;
BA_ "GenSigStartValue" SG_ 1281 TPMS_RL_Temperature 255;
BA_ "GenMsgCycleTime" BO_ 642 20;
BA_ "GenSigSendType" SG_ 642 SCM_LKS_Switch 1;
BA_ "GenSigSendType" SG_ 642 SCM_TimeGap_Select_Switch 1;
BA_ "GenSigSendType" SG_ 642 SCM_ACC_Switch 1;
BA_ "GenSigSendType" SG_ 642 SCM_Res_Set_Switch 1;
BA_ "GenSigSendType" SG_ 642 SCM_Flash_Switch 1;
BA_ "GenSigSendType" SG_ 642 SCM_PRND_req 1;
BA_ "GenMsgCycleTime" BO_ 373 10;
BA_ "GenMsgCycleTime" BO_ 279 100;
BA_ "GenSigStartValue" SG_ 279 VCU_ActualPowerPer 100;
BA_ "GenSigStartValue" SG_ 279 VCU_InputWaterTemp 65;
BA_ "GenSigStartValue" SG_ 279 VCU_OutputWaterTemp 65;
BA_ "GenMsgCycleTime" BO_ 1424 5000;
BA_ "GenMsgCycleTime" BO_ 1425 5000;
BA_ "GenMsgCycleTime" BO_ 1426 5000;
BA_ "GenSigStartValue" SG_ 1426 BMS_BattRetrospectCode 1;
BA_ "GenMsgCycleTime" BO_ 1427 5000;
BA_ "GenSigStartValue" SG_ 1427 BMS_BattProductionDate 1;
BA_ "GenSigStartValue" SG_ 1427 BMS_BattS_Num 1;
BA_ "GenSigStartValue" SG_ 1427 BMS_BattRecycleCode 1;
BA_ "GenMsgCycleTime" BO_ 1428 5000;
BA_ "GenSigStartValue" SG_ 1428 BMS_BattCodeLenth 1;
BA_ "GenMsgCycleTime" BO_ 945 100;
BA_ "GenMsgCycleTime" BO_ 946 100;
BA_ "GenSigStartValue" SG_ 946 TBOX_GyroTemperature 2047;
BA_ "GenMsgCycleTime" BO_ 1378 100;
BA_ "GenSigStartValue" SG_ 1378 MCU_MotorSts_GBT 3;
BA_ "GenMsgCycleTime" BO_ 805 100;
BA_ "GenMsgCycleTime" BO_ 1323 100;
BA_ "GenMsgCycleTime" BO_ 1325 100;
BA_ "GenMsgCycleTime" BO_ 1326 100;
BA_ "GenMsgCycleTime" BO_ 1327 100;
BA_ "GenMsgCycleTime" BO_ 1379 100;
BA_ "GenMsgCycleTime" BO_ 881 100;
BA_ "GenMsgCycleTime" BO_ 882 100;
BA_ "GenMsgCycleTime" BO_ 883 100;
BA_ "GenMsgCycleTime" BO_ 154 100;
BA_ "GenSigStartValue" SG_ 154 VCU_MCU_TrqReq 10000;
BA_ "GenMsgCycleTime" BO_ 155 20;
BA_ "GenSigStartValue" SG_ 155 VCU_DC_VoltageReq 120;
BA_ "GenMsgCycleTime" BO_ 156 100;
BA_ "GenMsgCycleTime" BO_ 157 100;
BA_ "GenMsgCycleTime" BO_ 321 20;
BA_ "GenSigStartValue" SG_ 321 VCU_DriverDemandTorq 10000;
BA_ "GenMsgCycleTime" BO_ 336 20;
BA_ "GenMsgCycleTime" BO_ 337 20;
BA_ "GenMsgCycleTime" BO_ 401 50;
BA_ "GenMsgCycleTime" BO_ 624 20;
BA_ "GenMsgCycleTime" BO_ 625 50;
BA_ "GenMsgCycleTime" BO_ 920 100;
BA_ "GenMsgCycleTime" BO_ 800 100;
BA_ "GenMsgCycleTime" BO_ 806 100;
BA_ "GenMsgCycleTime" BO_ 735 100;
BA_ "GenSigSendType" SG_ 735 HU_SetMemoryReq 1;
BA_ "GenSigSendType" SG_ 735 HU_DeleteMemoryReq 1;
BA_ "GenSigSendType" SG_ 735 HU_GetMemoryReq 1;
BA_ "GenSigSendType" SG_ 735 HU_DirverSLV_Direction_set 1;
BA_ "GenSigSendType" SG_ 735 HU_DirverSHV_Direction_set 1;
BA_ "GenSigSendType" SG_ 735 HU_DirverLNV_Direction_set 1;
BA_ "GenSigSendType" SG_ 735 HU_PassagerSLV_Direction_set 1;
BA_ "GenSigSendType" SG_ 735 HU_PassagerSHV_Direction_set 1;
BA_ "GenSigSendType" SG_ 735 HU_PassagerLNV_Direction_set 1;
BA_ "GenSigSendType" SG_ 735 HU_DSM_heatSwitch 1;
BA_ "GenSigSendType" SG_ 735 HU_DSM_Targtemp 1;
BA_ "GenSigStartValue" SG_ 735 HU_DSM_Targtemp 63;
BA_ "GenSigSendType" SG_ 735 HU_PSM_heatSwitch 1;
BA_ "GenSigSendType" SG_ 735 HU_PSM_Targtemp 1;
BA_ "GenSigStartValue" SG_ 735 HU_PSM_Targtemp 63;
BA_ "GenSigSendType" SG_ 735 HU_DSMEasyEntrySW 1;
BA_ "GenSigSendType" SG_ 735 HU_RVMAutoFoldSW 1;
BA_ "GenSigSendType" SG_ 735 HU_RVMFoldButton 1;
BA_ "GenSigSendType" SG_ 735 HU_RVM_R_DownSW 1;
BA_ "GenSigSendType" SG_ 735 HU_Userdefined_Mirror 1;
BA_ "GenMsgCycleTime" BO_ 928 100;
BA_ "GenSigStartValue" SG_ 928 ICM_instantaneous_power 400;
BA_ "GenSigSendType" SG_ 928 ICM_ODOTotalFB 1;
BA_ "GenSigSendType" SG_ 928 ICM_PrevmaintmileagesFB 1;
BA_ "GenSigSendType" SG_ 928 ICM_SubMileage_Reset 1;
BA_ "GenMsgCycleTime" BO_ 896 100;
BA_ "GenSigStartValue" SG_ 896 RLS_Brightness_FW 1023;
BA_ "GenSigStartValue" SG_ 896 RLS_Rain_Intensity 14;
BA_ "GenMsgCycleTime" BO_ 784 50;
BA_ "GenSigSendType" SG_ 784 BCM_RKE_lock_Unlock_req 1;
VAL_ 276 BMS_thermalControlReq 7 "预留" 6 "预留" 5 "预留" 4 "预留" 3 "请求均温" 2 "请求冷却" 1 "请求加热" 0 "无请求" ;
VAL_ 276 BMS_InputWaterTemp 254 "invalid" ;
VAL_ 276 BMS_OutputWaterTemp 254 "invalid" ;
VAL_ 276 BMS_PACK_PressureValue 126 "Invalid" ;
VAL_ 608 EPS_SafeLampRed 1 "open" 0 "close" ;
VAL_ 608 EPS_WarningLampYellow 1 "open" 0 "close" ;
VAL_ 608 EPS_DTCFlag 1 "DTC exist" 0 "no DTC exist" ;
VAL_ 608 EPS_DriveModeSts 3 "reserved" 2 "Sport Mode" 1 "Comfortable Mode" 0 "Normal Mode" ;
VAL_ 608 EPS_HU_DriveModeSetEn 1 "Availiable" 0 "Unavailiable" ;
VAL_ 375 EPS_EPSAPASts 7 "Failure" 6 "ADAS active" 5 "NRCD active" 4 "Reply for Control" 3 "Abort" 2 "Active" 1 "Available" 0 "Inhibit" ;
VAL_ 375 EPS_EPSAPAInh 16 "EPS failure" 8 "Excess Angle Deviation" 4 "Abnormal CAN input" 2 "Driver Interference" 1 "Over Speed" 0 "Normal Operation" ;
VAL_ 374 EPS_LKAResponseTorqueValid 1 "Invalid" 0 "Vaild" ;
VAL_ 374 EPS_LKAControlStatus 3 "Permanently Failed" 2 "Temporarily Limited" 1 "Active" 0 "Inactive" ;
VAL_ 580 ESC_APA_GearBoxEnable 1 "Enable" 0 "Not Enable" ;
VAL_ 580 ESC_APA_LC_FailureSts 7 "ParkAssist_WithError" 6 "ParkAssist_Reserved" 5 "ParkAssist_Unexpected_GearIntervention" 4 "ParkAssist_Unexpected_Brake" 3 "ParkAssist_Unexpected_EPB_Action" 2 "ParkAssist_Unexpected_GearPosition" 1 "ParkAssist_Vehicle_block" 0 "ParkAssist_NoError" ;
VAL_ 580 ESC_APA_LC_Availability 50 "LongCtrl_AutomaticPark" 8 "LongCtrl_ParkEmergencyBrake" 0 "No_LongCtrl_Support" ;
VAL_ 580 ESP_AWB_Available 1 "Available" 0 "Not available" ;
VAL_ 580 ESP_AWB_Intervention 1 "Active" 0 "Not active" ;
VAL_ 580 ESP_ABA_Available 1 "Available" 0 "Not available" ;
VAL_ 580 ESP_ABA_Intervention 1 "Active" 0 "Not active" ;
VAL_ 580 ESP_ABP_Available 1 "Available" 0 "Not available" ;
VAL_ 580 ESP_ABP_Intervention 1 "Active" 0 "Not active" ;
VAL_ 580 ESC_VirtualGaspadelPosReq 1 "Request" 0 "No Request" ;
VAL_ 580 ESC_CDPIntervention 1 "Active" 0 "Not Active" ;
VAL_ 580 ESC_CDPErrorSt 1 "Available" 0 "Not available" ;
VAL_ 529 ABS_WheelSpeed_FL 4095 "Invalid" ;
VAL_ 529 ABS_WheelSpeed_FR 4095 "Invalid" ;
VAL_ 529 ABS_WheelSpeed_RL 4095 "Invalid" ;
VAL_ 529 ABS_WheelSpeed_RR 4095 "Invalid" ;
VAL_ 529 ABS_WheelSpeed_FL_Valid 1 "Invalid" 0 "Valid" ;
VAL_ 529 ABS_WheelSpeed_FR_Valid 1 "Invalid" 0 "Valid" ;
VAL_ 529 ABS_WheelSpeed_RL_Valid 1 "Invalid" 0 "Valid" ;
VAL_ 529 ABS_WheelSpeed_RR_Valid 1 "Invalid" 0 "Valid" ;
VAL_ 913 DSM_Horizontalforward 1 "Active" 0 "Inactive" ;
VAL_ 913 DSM_HorizontalBackward 1 "Active" 0 "Inactive" ;
VAL_ 913 DSM_Liftup 1 "Active" 0 "Inactive" ;
VAL_ 913 DSM_LiftDown 1 "Active" 0 "Inactive" ;
VAL_ 913 DSM_Backforward 1 "Active" 0 "Inactive" ;
VAL_ 913 DSM_BackBackward 1 "Active" 0 "Inactive" ;
VAL_ 913 PSM_Horizontalforward 1 "Active" 0 "Inactive" ;
VAL_ 913 PSM_HorizontalBackward 1 "Active" 0 "Inactive" ;
VAL_ 913 PSM_Backforward 1 "Active" 0 "Inactive" ;
VAL_ 913 PSM_BackBackward 1 "Active" 0 "Inactive" ;
VAL_ 913 DSM_Seat_Calibration 3 "CalibrationDoneError" 2 "CalibrationDone" 1 "StartCalibration" 0 "NotCalibration" ;
VAL_ 1285 VCU_NM_SLEEP_Ind 1 "sleep indication" 0 "wakeup" ;
VAL_ 1285 AC_NM_SLEEP_Ind 1 "sleep indication" 0 "wakeup" ;
VAL_ 1285 APL_NM_SLEEP_Ind 1 "sleep indication" 0 "wakeup" ;
VAL_ 1285 DVR_NM_SLEEP_Ind 1 "sleep indication" 0 "wakeup" ;
VAL_ 1285 HU_NM_SLEEP_Ind 1 "sleep indication" 0 "wakeup" ;
VAL_ 1285 ICM_NM_SLEEP_Ind 1 "sleep indication" 0 "wakeup" ;
VAL_ 1285 ORM_NM_SLEEP_Ind 1 "sleep indication" 0 "wakeup" ;
VAL_ 1285 RSE_NM_SLEEP_Ind 1 "sleep indication" 0 "wakeup" ;
VAL_ 1285 BCM_NM_SLEEP_Ind 1 "sleep indication" 0 "wakeup" ;
VAL_ 1285 DSM_NM_SLEEP_Ind 1 "sleep indication" 0 "wakeup" ;
VAL_ 1285 PLG_NM_SLEEP_Ind 1 "sleep indication" 0 "wakeup" ;
VAL_ 1285 TBOX_NM_SLEEP_Ind 1 "sleep indication" 0 "wakeup" ;
VAL_ 406 PA_Buzzer_Alarm_Pattern_F 7 "Reserved" 6 "Reserved" 5 "Reserved" 4 "Front+S4" 3 "Front+S3" 2 "Front+S2" 1 "Front+S1" 0 "Buzzer OFF" ;
VAL_ 406 PA_Buzzer_Alarm_Pattern_R 7 "Reserved" 6 "Rear+S6" 5 "Rear+S5" 4 "Rear+S4" 3 "Rear+S3" 2 "Rear+S2" 1 "Rear+S1" 0 "Buzzer OFF" ;
VAL_ 406 PA_PDC_DISTANCE_FL 7 "Range 7" 6 "Range 6" 5 "Range 5" 4 "Range 4" 3 "Range 3" 2 "Range 2" 1 "Range 1" 0 "No Distance" ;
VAL_ 406 PA_PDC_DISTANCE_FML 7 "Range 7" 6 "Range 6" 5 "Range 5" 4 "Range 4" 3 "Range 3" 2 "Range 2" 1 "Range 1" 0 "No Distance" ;
VAL_ 406 PA_PDC_DISTANCE_FMR 7 "Range 7" 6 "Range 6" 5 "Range 5" 4 "Range 4" 3 "Range 3" 2 "Range 2" 1 "Range 1" 0 "No Distance" ;
VAL_ 406 PA_PDC_DISTANCE_FR 7 "Range 7" 6 "Range 6" 5 "Range 5" 4 "Range 4" 3 "Range 3" 2 "Range 2" 1 "Range 1" 0 "No Distance" ;
VAL_ 406 PAS_PDC_DISTANCE_RL 7 "Range 7" 6 "Range 6" 5 "Range 5" 4 "Range 4" 3 "Range 3" 2 "Range 2" 1 "Range 1" 0 "No Distance" ;
VAL_ 406 PA_PDC_DISTANCE_RML 7 "Range 7" 6 "Range 6" 5 "Range 5" 4 "Range 4" 3 "Range 3" 2 "Range 2" 1 "Range 1" 0 "No Distance" ;
VAL_ 406 PA_PDC_DISTANCE_RMR 7 "Range 7" 6 "Range 6" 5 "Range 5" 4 "Range 4" 3 "Range 3" 2 "Range 2" 1 "Range 1" 0 "No Distance" ;
VAL_ 406 PAS_PDC_DISTANCE_RR 7 "Range 7" 6 "Range 6" 5 "Range 5" 4 "Range 4" 3 "Range 3" 2 "Range 2" 1 "Range 1" 0 "No Distance" ;
VAL_ 406 PA_PDC_DISTANCE_LSF 7 "Range 7" 6 "Range 6" 5 "Range 5" 4 "Range 4" 3 "Range 3" 2 "Range 2" 1 "Range 1" 0 "No Distance" ;
VAL_ 406 PA_PDC_DISTANCE_RSF 7 "Range 7" 6 "Range 6" 5 "Range 5" 4 "Range 4" 3 "Range 3" 2 "Range 2" 1 "Range 1" 0 "No Distance" ;
VAL_ 406 PAS_PDC_DISTANCE_LSR 7 "Range 7" 6 "Range 6" 5 "Range 5" 4 "Range 4" 3 "Range 3" 2 "Range 2" 1 "Range 1" 0 "No Distance" ;
VAL_ 406 PA_PDC_DISTANCE_RSR 7 "Range 7" 6 "Range 6" 5 "Range 5" 4 "Range 4" 3 "Range 3" 2 "Range 2" 1 "Range 1" 0 "No Distance" ;
VAL_ 406 PA_PDC_WorkSts 1 "PDC On" 0 "PDC Off" ;
VAL_ 406 PA_PDC_MODE 7 "Invalid(Reserved)" 6 "Inhibited" 5 "System Failure" 4 "Rear Active" 3 "Front Active" 2 "Front Rear Active" 1 "Standby" 0 "Off" ;
VAL_ 579 ESP_YawrateValue_valid 1 "invalid" 0 "valid" ;
VAL_ 579 ESP_BrakelightRequest 1 "illuminate" 0 "not illuminate" ;
VAL_ 579 ESP_Intervention 1 "Active" 0 "Not active" ;
VAL_ 579 ESP_LongAccSensorValid 1 "invalid" 0 "valid" ;
VAL_ 579 ESP_EPBWarningMessage1 1 "Warning" 0 "No Warning" ;
VAL_ 579 ESP_EPBWarningMessage2 1 "Warning" 0 "No Warning" ;
VAL_ 579 ESP_AVHWarningMessage 1 "Warning" 0 "No Warning" ;
VAL_ 579 ESP_LaterAccSensorValid 1 "invalid" 0 "valid" ;
VAL_ 579 ESP_AEB_Available 1 "Available" 0 "Not available" ;
VAL_ 579 ESP_AEB_Intervention 1 "Active" 0 "Not active" ;
VAL_ 579 ESC_APA_LC_Status 10 "LongCtrl_Error" 9 "LongCtrl_Active_ManeuverAccelerationAvoidance" 8 "LongCtrl_Active_ManeuverComfortBrake" 7 "LongCtrl_Active_ManeuverEmergencyBrake" 6 "LongCtrl_Active_RemoteParkOut" 5 "LongCtrl_Active_RemoteParkIn" 4 "LongCtrl_Active_AutomaticPark" 3 "LongCtrl_Active_ParkEmergencyBrake" 2 "LongCtrl_Active_ParkComfortBrake" 1 "LongCtrl_Standby" 0 "LongCtrl_Off" ;
VAL_ 734 HU_DriveMode 7 "Reserved" 6 "Reserved" 5 "E-Pedal" 4 "Individual" 3 "Sport" 2 "ECO" 1 "comfort" 0 "default" ;
VAL_ 734 HU_RemoteCharge_EndHour 31 "Default" ;
VAL_ 734 HU_RemoteCharge_Endmin 63 "Default" ;
VAL_ 734 HU_RemotCh_Full_SetSts 3 "reserved" 2 "充满" 1 "不充满" 0 "default" ;
VAL_ 404 PA_APA_DistanceValueLR_FL 255 "Invalid" 254 "no object was detected" 253 "Reserved" 252 "Reserved" 251 "Reserved" ;
VAL_ 404 PA_APA_DistanceValueLR_FR 255 "Invalid" 254 "no object was detected" 253 "Reserved" 252 "Reserved" 251 "Reserved" ;
VAL_ 404 PA_APA_DistanceValueSR_FL 127 "Invalid" 126 "no object was detected" ;
VAL_ 404 PA_APA_DistanceValueSR_FML 127 "Invalid" 126 "no object was detected" ;
VAL_ 404 PA_APA_DistanceValueSR_FMR 127 "Invalid" 126 "no object was detected" ;
VAL_ 404 PA_APA_DistanceValueSR_FR 127 "Invalid" 126 "no object was detected" ;
VAL_ 405 PA_APA_DistanceValueLR_RL 255 "Invalid" 254 "no object was detected" 253 "Reserved" 252 "Reserved" 251 "Reserved" ;
VAL_ 405 PA_APA_DistanceValueLR_RR 255 "Invalid" 254 "no object was detected" 253 "Reserved" 252 "Reserved" 251 "Reserved" ;
VAL_ 405 PA_APA_DistanceValueSR_RL 127 "Invalid" 126 "no object was detected" ;
VAL_ 405 PA_APA_DistanceValueSR_RML 127 "Invalid" 126 "no object was detected" ;
VAL_ 405 PA_APA_DistanceValueSR_RMR 127 "Invalid" 126 "no object was detected" ;
VAL_ 405 PA_APA_DistanceValueSR_RR 127 "Invalid" 126 "no object was detected" ;
VAL_ 64 PEPS_RKECommand 6 "window close" 5 "Window open" 4 "Trunk unlock" 3 "Door lock" 2 "Door unlock" 1 "Vehicle search" 0 "No command" ;
VAL_ 64 PEPS_DoorUnlockReq 3 "解锁请求（四门钥匙防误锁）" 2 "解锁请求（后背门钥匙防误锁）" 1 "解锁请求" 0 "无请求" ;
VAL_ 64 PEPS_DoorlockReq 3 "预留" 2 "预留" 1 "闭锁请求" 0 "无请求" ;
VAL_ 64 PEPS_TrunkReleaseReq 1 "请求" 0 "无请求" ;
VAL_ 1377 VCU_IG1input 1 "active" 0 "inactive" ;
VAL_ 1377 VCU_startinput 1 "active" 0 "inactive" ;
VAL_ 1377 VCU_OBCwakeupVCU 1 "active" 0 "inactive" ;
VAL_ 1377 VCU_VCUwakeupOBC 1 "active" 0 "inactive" ;
VAL_ 1377 VCU_VCUwakeupBMS 1 "active" 0 "inactive" ;
VAL_ 1377 VCU_VCUwakeupMCU 1 "active" 0 "inactive" ;
VAL_ 1377 VCU_VacuumPumpRelay 1 "active" 0 "inactive" ;
VAL_ 1377 VCU_WPTCRelay 1 "active" 0 "inactive" ;
VAL_ 912 DSM_MirrorRdownSetStatus 1 "disable" 0 "enable" ;
VAL_ 912 DSM_LeftMirrorMotor1fault 1 "fault" 0 "no fault" ;
VAL_ 912 DSM_LeftMirrorMotor2fault 1 "fault" 0 "no fault" ;
VAL_ 912 DSM_RightMirrorMotor1fault 1 "fault" 0 "no fault" ;
VAL_ 912 DSM_RightMirrorMotor2fault 1 "fault" 0 "no fault" ;
VAL_ 912 DSM_WorkMode 7 "Reserved" 6 "Reserved" 5 "调节模式" 4 "倒车后视镜下翻" 3 "下车迎宾" 2 "上车迎宾" 1 "记忆调用" 0 "Default" ;
VAL_ 912 DSM_LMM1_CalibrationSts 3 "Reserved" 2 "Calibration complete" 1 "Calibration incomplete" 0 "Default" ;
VAL_ 912 DSM_LMM2_CalibrationSts 3 "Reserved" 2 "Calibration complete" 1 "Calibration incomplete" 0 "Default" ;
VAL_ 912 DSM_RMM1_CalibrationSts 3 "Reserved" 2 "Calibration complete" 1 "Calibration incomplete" 0 "Default" ;
VAL_ 912 DSM_RMM2_CalibrationSts 3 "Reserved" 2 "Calibration complete" 1 "Calibration incomplete" 0 "Default" ;
VAL_ 852 PEPS_Driver_Antenna_Error 1 "故障" 0 "无故障" ;
VAL_ 852 PEPS_Passenger_Antenna_Error 1 "故障" 0 "无故障" ;
VAL_ 852 PEPS_Trunk_Antenna_Error 1 "故障" 0 "无故障" ;
VAL_ 852 BCM_HU_DoorLocksetFB 1 "FourDoor UnLock" 0 "DiverDoor UnLock" ;
VAL_ 852 PEPS_Facia_Antenna_Error 1 "故障" 0 "无故障" ;
VAL_ 852 PEPS_Rear_Antenna_Error 1 "故障" 0 "无故障" ;
VAL_ 852 PEPS_Handrail_Antenna_Error 1 "故障" 0 "无故障" ;
VAL_ 852 PEPS_RecentlyKEYTypeCmd 8 "四门防误锁请求" 7 "后备门防误锁请求" 6 "PE解锁请求" 5 "PE闭锁请求" 4 "RF window close" 3 "RF Window open" 2 "RF Door lock" 1 "RF Door unlock" 0 "No command" ;
VAL_ 852 PEPS_KeyLessCodeNumber 5 "key less 5" 4 "key less 4" 3 "key less 3" 2 "key less 2" 1 "key less 1" 0 "no key less operation" ;
VAL_ 546 PEPS_PEPSFailStatus 1 "Active" 0 "Inactive" ;
VAL_ 546 PEPS_WarningKeyNotInCar 1 "Active" 0 "Inactive" ;
VAL_ 546 PEPS_WarningKeyInCar 1 "Active" 0 "Inactive" ;
VAL_ 546 PEPS_WarningIgNotOff 1 "Active" 0 "Inactive" ;
VAL_ 546 PEPS_WarningKeyLowBattery 1 "Active" 0 "Inactive" ;
VAL_ 546 PEPS_WarningStartupNotBrake 1 "Active" 0 "Inactive" ;
VAL_ 546 PEPS_WarningKeyNearbyIMMO 1 "Active" 0 "Inactive" ;
VAL_ 546 PEPS_PassiveWindowCom 1 "Long press lock button" 0 "no Command" ;
VAL_ 546 PEPS_BackDoorKeyState 3 "无钥匙在后背门附近" 2 "有钥匙在后背门附近" 1 "找钥匙中" 0 "未找钥匙" ;
VAL_ 546 PEPS_KeyPosition 3 "预留" 2 "钥匙不在车内" 1 "钥匙在车内" 0 "无输入" ;
VAL_ 546 PEPS_HandshakeFail 7 "无效值" 6 "预留" 5 "预留" 4 "预留" 3 "TIMEOUT_ERR:发送超时；" 2 "握手失败NO_RES_ERR:从MCU无 响应" 1 "握手失败CRC_ERR: 发送/接收 数据格式或CRC校验不正确；" 0 "握手成功" ;
VAL_ 546 PEPS_Authpasstype 3 "FOB and tbox response OK" 2 "FOB response OK" 1 "TBOX response OK" 0 "Auth not pass" ;
VAL_ 546 PEPS_EnableWirelessCharging 1 "Enable" 0 "Disable" ;
VAL_ 546 PEPS_DHA_LeftHandleSwitch 3 "reserved" 2 "闭锁请求" 1 "解锁请求" 0 "default" ;
VAL_ 546 PEPS_PHA_RightHandleSwitch 3 "reserved" 2 "闭锁请求" 1 "解锁请求" 0 "default" ;
VAL_ 546 DHA_LockFlag 80 "代表同时解闭锁有效" 10 "代表解锁有效," 5 "代表闭锁有效" 0 "代表没有触摸" ;
VAL_ 546 PHA_LockFlag 80 "代表同时解闭锁有效" 10 "代表解锁有效," 5 "代表闭锁有效" 0 "代表没有触摸" ;
VAL_ 820 IBS_U_BATT 16383 "invalid" ;
VAL_ 820 IBS_I_Range 3 "invalid" 2 "current Range [-1500, 1500A]" 1 "current Range [-200, 200A]" 0 "current Range [-1, 1A]" ;
VAL_ 820 IBS_I_BATT 65535 "invalid" ;
VAL_ 820 IBS_T_BATT 255 "invalid" ;
VAL_ 820 IBS_IBATT_QUIESCENT 255 "invalid" 254 "Out of bounds" 253 "Overflow" ;
VAL_ 820 IBS_Status_Current 3 "LIN saturation (no HW defect)" 2 "HW defect (out of range or ADC defect)" 1 "Error Open circuit" 0 "No error" ;
VAL_ 820 IBS_Status_Voltage 3 "LIN saturation (no HW defect)" 2 "HW defect (ADC defect)" 1 "Error Open circuit" 0 "No error" ;
VAL_ 820 IBS_Status_Temp 3 "LIN saturation (no HW defect)" 2 "HW defect (ADC defect)" 1 "not used" 0 "No error" ;
VAL_ 820 IBS_ERROR_Calib 1 "Error" 0 "No error" ;
VAL_ 820 IBS_ERROR_IDENT 1 "Error" 0 "No error" ;
VAL_ 820 IBS_Resp_Error 1 "Error" 0 "No error" ;
VAL_ 820 IBS_FLAG_INCONSISTENCY 1 "battery inconsistency" 0 "no battery inconsistency" ;
VAL_ 821 IBS_SOC 255 "invalid" ;
VAL_ 821 IBS_SOH_SUL 255 "invalid" ;
VAL_ 821 IBS_SOFV_StopEnable 255 "invalid" ;
VAL_ 821 IBS_SOFV_Restart 255 "invalid" ;
VAL_ 821 IBS_SOH_LAM 255 "invalid" ;
VAL_ 821 IBS_SOH_COR 255 "invalid" ;
VAL_ 821 IBS_SOC_STATE 3 "invalid" 2 "deviation < 10%" 1 "deviation < 15%" 0 "deviation > 15%" ;
VAL_ 821 IBS_SOH_SUL_STATE 3 "invalid" 2 "not used" 1 "learned" 0 "not learned" ;
VAL_ 821 IBS_SOFV_StopEnable_STATE 3 "invalid" 2 "not used" 1 "accurate (deviation < 400mV)" 0 "inaccurate" ;
VAL_ 821 IBS_SOFV_Restart_STATE 3 "invalid" 2 "undefined" 1 "accurate (deviation < 400mV)" 0 "inaccurate" ;
VAL_ 821 IBS_SOH_LAM_STATE 3 "invalid" 2 "undefined" 1 "learned" 0 "not learned" ;
VAL_ 821 IBS_SOH_COR_STATE 3 "invalid" 2 "accurate (deviation < 400mV)" 1 "inaccurate" 0 "not learned" ;
VAL_ 933 HU_LanguageSet 15 "Reserved" 8 "Reserved" 7 "Portuguese" 6 "Spanish" 5 "Italian" 4 "French" 3 "German" 2 "Russian" 1 "English" 0 "Chinese" ;
VAL_ 933 HU_TimeSet_DisplayMode 1 "24 hour" 0 "12 hour" ;
VAL_ 933 HU_TimeSet_AutoMode 1 "Manual" 0 "Automatical" ;
VAL_ 933 HU_TBOXwelcomeReq_set 3 "reserved" 2 "disable" 1 "enable" 0 "Default" ;
VAL_ 933 HU_TimeSet_Hour 30 "Reserved" 24 "Reserved" 23 "valid hour" 0 "valid hour" ;
VAL_ 933 HU_MCUPowerState 7 "Reserved" 6 "Reserved" 5 "Reserved" 4 "Power Save Mode(Sleep)" 3 "Power Save Mode(Standby)" 2 "Silent Mode" 1 "Half Hour Mode" 0 "Normal Mode" ;
VAL_ 933 HU_TimeSet_Minutes 60 "valid min" 0 "valid min" ;
VAL_ 933 HU_SOCResetType 1 "SOC热启动（SOC休眠唤醒" 0 "SOC冷启动（SOC断电上电）" ;
VAL_ 933 HU_HardACCState 1 "Hard ACC On" 0 "Hard ACC Off" ;
VAL_ 933 HU_TBOX_Reboot 3 "Reserved" 2 "Reserved" 1 "reboot" 0 "Default" ;
VAL_ 933 HU_mute_activests 1 "active" 0 "incative" ;
VAL_ 933 HU_Voicecontrol_activests 1 "active" 0 "incative" ;
VAL_ 933 HU_SOCWatchdog 1 "SOC Watchdog Normal" 0 "SOC Watchdog Fail" ;
VAL_ 933 HU_phonecall_worksts 1 "接听" 0 "挂断" ;
VAL_ 933 HU_ICM_INFO_Enable 3 "Reserved" 2 "ON" 1 "OFF" 0 "default" ;
VAL_ 933 HU_BCMSystemPowerMode 3 "Ready" 2 "ON" 1 "Reserved" 0 "off" ;
VAL_ 933 HU_RemoteCharge_StartHour 31 "default" ;
VAL_ 933 HU_RemoteCharge_Startmin 63 "default" ;
VAL_ 933 HU_RemoteCharge_Set 3 "Reserved" 2 "开启定时充电模式" 1 "取消定时充电模式" 0 "default" ;
VAL_ 933 HU_ChargeCtrl_Set 3 "Reserved" 2 "定时充电" 1 "立即充电" 0 "default" ;
VAL_ 933 HU_BatteryVoltage 31 "default" ;
VAL_ 933 HU_SPIConnectState 1 "SPI Connect" 0 "SPI Not Connect" ;
VAL_ 816 BCM_reversingLampSW 1 "on" 0 "off" ;
VAL_ 816 BCM_CarpetlampSW 1 "on" 0 "off" ;
VAL_ 816 BCM_CarpetlampSWSetsts 1 "Enable" 0 "Dsiaable" ;
VAL_ 816 BCM_FrontdecoralampSW 1 "on" 0 "off" ;
VAL_ 816 BCM_LeftReadlampControl 1 "on" 0 "off" ;
VAL_ 816 BCM_RightReadlampControl 1 "on" 0 "off" ;
VAL_ 816 BCM_FloodlightControl 1 "on" 0 "off" ;
VAL_ 816 BCM_DomeLampDoorControl 1 "on" 0 "off" ;
VAL_ 816 BCM_LockWelcomeSts 3 "闭锁迎宾模式完成" 2 "闭锁迎宾模式中" 1 "闭锁迎宾模式开始" 0 "default" ;
VAL_ 816 BCM_PEPSLockReason 7 "default" 6 "reserved" 5 "reserved" 4 "reserved" 3 "RKE闭锁" 2 "PE闭锁" 1 "default" ;
VAL_ 816 BCM_PEPSUnLockReason 7 "reserved" 6 "reserved" 5 "reserved" 4 "后背门防误锁" 3 "四门防误锁" 2 "RKE解锁" 1 "PE解锁" 0 "defauit" ;
VAL_ 816 BCM_FollowMeControlsts 1 "on" 0 "off" ;
VAL_ 816 BCM_FollowMeDelayTSetsts 3 "90s" 2 "60s" 1 "30s" 0 "default" ;
VAL_ 816 BCM_AutoLockSetsts 1 "enable" 0 "disable" ;
VAL_ 816 BCM_WindowAutoUPSetsts 1 "enable" 0 "disable" ;
VAL_ 816 BCM_FL_LED_Error 1 "error" 0 "no error" ;
VAL_ 816 BCM_FR_LED_Error 1 "error" 0 "no error" ;
VAL_ 816 BCM_RL_LED_Error 1 "error" 0 "no error" ;
VAL_ 816 BCM_RR_LED_Error 1 "error" 0 "no error" ;
VAL_ 816 BCM_LockReason 7 "lock form Tbox 4G lock request" 6 "BCM Secondary lock" 5 "lock form speed signal" 4 "lock form CSW request" 3 "lock form mechanical key" 2 "lock form PEPS lock request" 1 "lock form Tbox BT lock request" 0 "defauit" ;
VAL_ 816 BCM_UnLockReason 7 "Unlock form APS request" 6 "Unlock form Tbox 4G unlock request" 5 "Unlock form crash signal" 4 "Unlock form CSW request" 3 "Unlock form mechanical key" 2 "Unlock form PEPS unlock request" 1 "Unlock form Tbox BT unlock request" 0 "defauit" ;
VAL_ 816 BCM_CSW_SSB_inputSts 1 "active" 0 "Notactive" ;
VAL_ 816 BCM_ACU_Crash_inputsts 1 "active" 0 "Notactive" ;
VAL_ 816 BCM_ESCL_UnlockFB_inputsts 1 "active" 0 "Notactive" ;
VAL_ 816 BCM_ESCL_Motorpower_outputsts 1 "active" 0 "Notactive" ;
VAL_ 816 BCM_ESCL_LockEnable_outputsts 1 "active" 0 "Notactive" ;
VAL_ 816 BCM_ESCL_UnLockfail 1 "fail" 0 "no  fail" ;
VAL_ 816 BCM_ESCL_Lockfail 1 "fail" 0 "no  fail" ;
VAL_ 816 BCM_waterlightlimit 1 "limit" 0 "nolimit" ;
VAL_ 961 Tbox_ICM_ODOTotal 16777215 "Invalid" ;
VAL_ 961 Tbox_ICM_Prevmaintmileage 16777215 "Invalid" ;
VAL_ 1281 TPMS_FL_Pressure_value 255 "Invalid" ;
VAL_ 1281 TPMS_FR_Pressure_value 255 "Invalid" ;
VAL_ 1281 TPMS_RL_Pressure_value 255 "Invalid" ;
VAL_ 1281 TPMS_RR_Pressure_value 255 "Invalid" ;
VAL_ 642 SCM_LKS_Switch 1 "pressed" 0 "not pressed" ;
VAL_ 642 SCM_TimeGap_Select_Switch 3 "Invalid" 2 "TimeGap -" 1 "TimeGap+" 0 "Neutral" ;
VAL_ 642 SCM_ACC_Switch 3 "Invalid" 2 "ACC on/TJA" 1 "ACC Cancel/off" 0 "Neutral" ;
VAL_ 642 SCM_Res_Set_Switch 3 "Invalid" 2 "SET/-" 1 "RES/+" 0 "Neutral" ;
VAL_ 642 SCM_LKS_Switch_Invalid 1 "Invalid" 0 "valid" ;
VAL_ 642 SCM_TurnIndicator_Switch 3 "Invalid" 2 "Turn Right" 1 "Turn Left" 0 "OFF" ;
VAL_ 642 SCM_Flash_Switch 1 "ON" 0 "OFF" ;
VAL_ 642 SCM_Flash_Switch_Sts 1 "Invalid" 0 "Valid" ;
VAL_ 642 SCM_HiBeam_Switch 1 "ON" 0 "OFF" ;
VAL_ 642 SCM_HiBeam_Switch_Sts 1 "Invalid" 0 "Valid" ;
VAL_ 642 SCM_Fwiper_Mist_Switch 1 "ON" 0 "OFF" ;
VAL_ 642 SCM_FWiper_Switch 7 "Invalid" 6 "Reserved" 5 "Reserved" 4 "Auto-High" 3 "Auto-Low" 2 "HS Speed" 1 "LS speed" 0 "OFF" ;
VAL_ 642 SCM_RWiper_Switch 3 "Invalid" 2 "Rear Washer" 1 "Rear Wiper ON" 0 "OFF" ;
VAL_ 642 SCM_PRND_req 7 "Invalid" 6 "Reserved" 5 "Reserved" 4 "D" 3 "N" 2 "R" 1 "P" 0 "Default" ;
VAL_ 373 SAS_SteerWheelRotSpd 16383 "Invalid signal" ;
VAL_ 373 SAS_SteerWheelRotSpdStatus 1 "Invalid" 0 "Valid" ;
VAL_ 373 SAS_SASStsSnsr 1 "sensor value  valid" 0 "sensor value  Invalid" ;
VAL_ 373 EPS_SteeringTorqueValid 1 "Invalid" 0 "Vaild" ;
VAL_ 373 SAS_SASStsCal 1 "sensor calibrated" 0 "sensor not calibrated" ;
VAL_ 279 VCU_ActualPowerPer 255 "invalid" ;
VAL_ 279 VCU_thermalControlReq 7 "Reserved" 6 "Reserved" 5 "Reserved" 4 "Reserved" 3 "请求均温" 2 "请求冷却" 1 "请求加热" 0 "无请求" ;
VAL_ 279 VCU_EnergyRegLimPer 127 "invalid" ;
VAL_ 279 VCU_InputWaterTemp 255 "invalid" ;
VAL_ 279 VCU_OutputWaterTemp 255 "invalid" ;
VAL_ 279 VCU_EnergyDriveLimPer 127 "invalid" ;
VAL_ 946 TBOX_GyroTemperature 2046 "Invalid" ;
VAL_ 1378 MCU_MotorSts_GBT 255 "无效" 254 "异常；" 253 "Reserved；" 252 "Reserved；" 251 "Reserved；" 250 "Reserved；" 249 "Reserved；" 248 "Reserved；" 247 "Reserved；" 246 "Reserved；" 245 "Reserved；" 244 "Reserved；" 243 "Reserved；" 242 "Reserved；" 241 "Reserved；" 240 "Reserved；" 239 "Reserved；" 238 "Reserved；" 237 "Reserved；" 236 "Reserved；" 235 "Reserved；" 234 "Reserved；" 233 "Reserved；" 232 "Reserved；" 231 "Reserved；" 230 "Reserved；" 229 "Reserved；" 228 "Reserved；" 227 "Reserved；" 226 "Reserved；" 225 "Reserved；" 224 "Reserved；" 223 "Reserved；" 222 "Reserved；" 221 "Reserved；" 220 "Reserved；" 219 "Reserved；" 218 "Reserved；" 217 "Reserved；" 216 "Reserved；" 215 "Reserved；" 214 "Reserved；" 213 "Reserved；" 212 "Reserved；" 211 "Reserved；" 210 "Reserved；" 209 "Reserved；" 208 "Reserved；" 207 "Reserved；" 206 "Reserved；" 205 "Reserved；" 204 "Reserved；" 203 "Reserved；" 202 "Reserved；" 201 "Reserved；" 200 "Reserved；" 199 "Reserved；" 198 "Reserved；" 197 "Reserved；" 196 "Reserved；" 195 "Reserved；" 194 "Reserved；" 193 "Reserved；" 192 "Reserved；" 191 "Reserved；" 190 "Reserved；" 189 "Reserved；" 188 "Reserved；" 187 "Reserved；" 186 "Reserved；" 185 "Reserved；" 184 "Reserved；" 183 "Reserved；" 182 "Reserved；" 181 "Reserved；" 180 "Reserved；" 179 "Reserved；" 178 "Reserved；" 177 "Reserved；" 176 "Reserved；" 175 "Reserved；" 174 "Reserved；" 173 "Reserved；" 172 "Reserved；" 171 "Reserved；" 170 "Reserved；" 169 "Reserved；" 168 "Reserved；" 167 "Reserved；" 166 "Reserved；" 165 "Reserved；" 164 "Reserved；" 163 "Reserved；" 162 "Reserved；" 161 "Reserved；" 160 "Reserved；" 159 "Reserved；" 158 "Reserved；" 157 "Reserved；" 156 "Reserved；" 155 "Reserved；" 154 "Reserved；" 153 "Reserved；" 152 "Reserved；" 151 "Reserved；" 150 "Reserved；" 149 "Reserved；" 148 "Reserved；" 147 "Reserved；" 146 "Reserved；" 145 "Reserved；" 144 "Reserved；" 143 "Reserved；" 142 "Reserved；" 141 "Reserved；" 140 "Reserved；" 139 "Reserved；" 138 "Reserved；" 137 "Reserved；" 136 "Reserved；" 135 "Reserved；" 134 "Reserved；" 133 "Reserved；" 132 "Reserved；" 131 "Reserved；" 130 "Reserved；" 129 "Reserved；" 128 "Reserved；" 127 "Reserved；" 126 "Reserved；" 125 "Reserved；" 124 "Reserved；" 123 "Reserved；" 122 "Reserved；" 121 "Reserved；" 120 "Reserved；" 119 "Reserved；" 118 "Reserved；" 117 "Reserved；" 116 "Reserved；" 115 "Reserved；" 114 "Reserved；" 113 "Reserved；" 112 "Reserved；" 111 "Reserved；" 110 "Reserved；" 109 "Reserved；" 108 "Reserved；" 107 "Reserved；" 106 "Reserved；" 105 "Reserved；" 104 "Reserved；" 103 "Reserved；" 102 "Reserved；" 101 "Reserved；" 100 "Reserved；" 99 "Reserved；" 98 "Reserved；" 97 "Reserved；" 96 "Reserved；" 95 "Reserved；" 94 "Reserved；" 93 "Reserved；" 92 "Reserved；" 91 "Reserved；" 90 "Reserved；" 89 "Reserved；" 88 "Reserved；" 87 "Reserved；" 86 "Reserved；" 85 "Reserved；" 84 "Reserved；" 83 "Reserved；" 82 "Reserved；" 81 "Reserved；" 80 "Reserved；" 79 "Reserved；" 78 "Reserved；" 77 "Reserved；" 76 "Reserved；" 75 "Reserved；" 74 "Reserved；" 73 "Reserved；" 72 "Reserved；" 71 "Reserved；" 70 "Reserved；" 69 "Reserved；" 68 "Reserved；" 67 "Reserved；" 66 "Reserved；" 65 "Reserved；" 64 "Reserved；" 63 "Reserved；" 62 "Reserved；" 61 "Reserved；" 60 "Reserved；" 59 "Reserved；" 58 "Reserved；" 57 "Reserved；" 56 "Reserved；" 55 "Reserved；" 54 "Reserved；" 53 "Reserved；" 52 "Reserved；" 51 "Reserved；" 50 "Reserved；" 49 "Reserved；" 48 "Reserved；" 47 "Reserved；" 46 "Reserved；" 45 "Reserved；" 44 "Reserved；" 43 "Reserved；" 42 "Reserved；" 41 "Reserved；" 40 "Reserved；" 39 "Reserved；" 38 "Reserved；" 37 "Reserved；" 36 "Reserved；" 35 "Reserved；" 34 "Reserved；" 33 "Reserved；" 32 "Reserved；" 31 "Reserved；" 30 "Reserved；" 29 "Reserved；" 28 "Reserved；" 27 "Reserved；" 26 "Reserved；" 25 "Reserved；" 24 "Reserved；" 23 "Reserved；" 22 "Reserved；" 21 "Reserved；" 20 "Reserved；" 19 "Reserved；" 18 "Reserved；" 17 "Reserved；" 16 "Reserved；" 15 "Reserved；" 14 "Reserved；" 13 "Reserved；" 12 "Reserved；" 11 "Reserved；" 10 "Reserved；" 9 "Reserved；" 8 "Reserved；" 7 "Reserved；" 6 "Reserved；" 5 "Reserved；" 4 "准备；" 3 "关闭；" 2 "发电；" 1 "耗电；" 0 "Reserved；" ;
VAL_ 1378 MCU_MotoroffsetCalReq 1 "True" 0 "False" ;
VAL_ 805 WPTC_RunSts 3 "预留" 2 "故障" 1 "运行" 0 "关闭" ;
VAL_ 805 WPTC_HVSts 3 "高压欠压故障" 2 "高压过压故障" 1 "已供电" 0 "未供电" ;
VAL_ 805 WPTC_COM_VCU_Lost 1 "异常" 0 "正常" ;
VAL_ 805 WPTC_CUR_Over 1 "异常" 0 "正常" ;
VAL_ 805 WPTC_Temp_PCB_High 1 "异常" 0 "正常" ;
VAL_ 805 WPTC_OutletTemp_High 1 "异常" 0 "正常" ;
VAL_ 805 WPTC_InputTemp_High 1 "异常" 0 "正常" ;
VAL_ 1379 VCU_CCOut 1 "active" 0 "inactive" ;
VAL_ 1379 VCU_FastCharge_A 1 "active" 0 "inactive" ;
VAL_ 881 VCU_instantaneous_Energy 4095 "Invalid" ;
VAL_ 881 VCU_instantaneous_EnergyUnit 1 "kwh/100km" 0 "KW" ;
VAL_ 881 VCU_TrailerMode 1 "Active" 0 "NoActive" ;
VAL_ 881 VBU_BattTempLowCharge 1 "Active" 0 "Inactive" ;
VAL_ 881 VCU_trip 4095 "Invalid" ;
VAL_ 881 VCU_ChargeIncreaseMileage 2047 "Invalid" ;
VAL_ 882 VCU_SubtotalAverageEnergy 511 "Invalid" ;
VAL_ 882 VCU_SubtotalEnergy 32767 "Invalid" ;
VAL_ 882 VCU_Subtotaltime 32767 "Invalid" ;
VAL_ 882 VCU_ChargeIncreaseMileageSpeed 2047 "Invalid" ;
VAL_ 883 VCU_DST 4095 "Invalid" ;
VAL_ 883 VCU_SingleMileageAverageEnergy 511 "Invalid" ;
VAL_ 883 VCU_SingleMileageEnergy 32767 "Invalid" ;
VAL_ 883 VCU_SingleMileagetime 32767 "Invalid" ;
VAL_ 883 VCU_SlowChargeGunSt 3 "无效" 2 "插枪" 1 "未插枪" 0 "正在检测" ;
VAL_ 883 VCU_FastChargeGunSt 3 "无效" 2 "插枪" 1 "未插枪" 0 "正在检测" ;
VAL_ 154 VCU_ErrorLevel 7 "预留" 6 "预留" 5 "五级故障" 4 "四级故障" 3 "三级故障" 2 "二级故障" 1 "一级故障" 0 "无故障" ;
VAL_ 154 VCU_MCU_WorkMode 7 "预留" 6 "EmgPark" 5 "HillHold" 4 "Discharge" 3 "Calibration mode" 2 "Speed mode" 1 "Torque mode" 0 "Disable" ;
VAL_ 154 VCU_MCU_TrqReq 32767 "Invalid" ;
VAL_ 154 VCU_MCU_SpdReq 65535 "Invalid" ;
VAL_ 154 VCU_MotorOffsetCalCmd 255 "条件准备完成" 254 "其他" 9 "与ESP通信故障" 8 "与MCU通信故障" 7 "模式不正确" 6 "BMS discharge power out of range" 5 "ESP not disabled；" 4 "Vehicle Speed is not 0kph；（此处 车速 不能用电机 转速 计算 ）" 3 "Shift Position Not in Park or Neutral；" 2 "PT Not Ready；" 1 "VCU正在判断条件" 0 "无条件准备请求" ;
VAL_ 155 VCU_BMS_WorkMode 7 "预留" 6 "预留" 5 "紧急下电指令" 4 "下电指令" 3 "放电指令" 2 "慢充指令" 1 "快充指令" 0 "standby" ;
VAL_ 155 VCU_DC_WorkMode 7 "预留" 6 "预留" 5 "预留" 4 "预留" 3 "预留" 2 "Discharge" 1 "Enable" 0 "Disable" ;
VAL_ 155 VCU_WPTC_En 3 "Enable" 2 "Discharge" 1 "Reserved" 0 "Disable" ;
VAL_ 155 VCU_WPTC_Request 3 "Reserved" 2 "Stop" 1 "Start" 0 "Default" ;
VAL_ 155 VCU_OBC_RemoteCharge 1 "Active" 0 "Inactive" ;
VAL_ 155 VCU_OBC_ChrgLock 3 "预留" 2 "lock" 1 "unlock" 0 "no request" ;
VAL_ 155 VCU_ChrgLockSts 7 "预留" 6 "预留" 5 "预留" 4 "解锁超时" 3 "解锁失败" 2 "正在解锁" 1 "unlock" 0 "Default" ;
VAL_ 155 VCU_ACU_DrvSeatBeltSWSts 1 "VCU request ACU send Buckle on" 0 "default" ;
VAL_ 155 VCU_OBC_ChrgEnable 7 "预留" 6 "预留" 5 "预留" 4 "预留" 3 "预留" 2 "预留" 1 "Enable" 0 "Disable" ;
VAL_ 156 VCU_Cruise_Sts 3 "fault" 2 "active" 1 "ON" 0 "off" ;
VAL_ 156 VCU_DriveInhibitAlarm 1 "Active" 0 "Inactive" ;
VAL_ 156 VCU_HU_ChrgLockSts 7 "预留" 6 "预留" 5 "预留" 4 "解锁超时" 3 "解锁失败" 2 "正在解锁" 1 "unlock" 0 "Default" ;
VAL_ 156 VCU_SpeedLimitSWSts 1 "Limit" 0 "No Limit" ;
VAL_ 156 VCU_DMS_Status 3 "非常疲劳" 2 "疲劳" 1 "清醒" 0 "OFF" ;
VAL_ 156 VCU_DMS_SWStatus 1 "ON" 0 "OFF" ;
VAL_ 156 VCU_LimitSpeedAlarm_L 1 "Active" 0 "No Active" ;
VAL_ 156 VCU_LimitSpeedAlarm_V 1 "Active" 0 "No Active" ;
VAL_ 156 VCU_SlowChargeLight 7 "充电故障" 6 "预约充电" 5 "充电未完成可拔枪" 4 "充电完成可拔枪" 3 "充电完成" 2 "充电中" 1 "正在启动交流充电" 0 "默认" ;
VAL_ 156 VCU_FastChargeLight 7 "预留3" 6 "预留2" 5 "预留1" 4 "充电故障" 3 "充电完成" 2 "充电中" 1 "正在启动直流充电" 0 "默认" ;
VAL_ 157 VCU_AC_ComfortEAC_En 1 "Enable" 0 "Disable" ;
VAL_ 157 VCU_AC_BatCoolEAC_En 1 "Enable" 0 "Disable" ;
VAL_ 157 VCU_AC_APTC_En 1 "Enable" 0 "Disable" ;
VAL_ 157 VCU_BattPump_ErrorSts 7 "Reserved" 6 "空转" 5 "过压" 4 "过温" 3 "低压" 2 "过流" 1 "堵转" 0 "正常" ;
VAL_ 157 VCU_RemoteACFeedback 15 "预留" 14 "预留" 13 "预留" 12 "预留" 11 "预留" 10 "预留" 9 "启动中" 8 "其他故障" 7 "启动太频繁" 6 "空调开启最大时间到" 5 "功率低" 4 "SOC过低" 3 "高压系统故障" 2 "本地状态" 1 "正在远程空调:" 0 "未开启" ;
VAL_ 157 VCU_FanSts 1 "故障" 0 "无故障" ;
VAL_ 157 VCU_12VbatterySOHLow 1 "SOH Low" 0 "SOH Normal" ;
VAL_ 157 VCU_LVSmartChrg_Status 3 "Reserved" 2 "LVSmartChargeFalut" 1 "LVSmartCharging" 0 "NoLVSmartCharge" ;
VAL_ 321 VCU_DriverDemandTorq 32767 "Invalid" ;
VAL_ 321 VCU_QECACC 7 "Reserved5" 6 "Reserved4" 5 "Reserved3" 4 "Reserved2" 3 "Reserved1" 2 "Power system failure" 1 "communication failure" 0 "no error" ;
VAL_ 321 VCU_CreepSwitch 1 "开启" 0 "关闭" ;
VAL_ 321 VCU_OnepedalSetEn 1 "允许" 0 "禁止" ;
VAL_ 321 VCU_GearShiftInProgress 1 "Gear is shifting" 0 "Gear not shifting" ;
VAL_ 321 VCU_ShiftInProgress_Status 1 "Invalid" 0 "Valid" ;
VAL_ 321 VCU_AccelerationModePer 127 "Invalid" ;
VAL_ 321 VCU_OverRide 1 "driver override" 0 "no override." ;
VAL_ 321 VCU_DriveMode 7 "Reserved" 6 "Reserved" 5 "Reserved" 4 "E-Pedal" 3 "Individual" 2 "Sport" 1 "ECO" 0 "comfort" ;
VAL_ 321 VCU_APA_LC_Availability 3 "保留" 2 "LongCtrl_AutomaticPark" 1 "LongCtrl_ParkEmergencyBrake" 0 "No_LongCtrl_Support" ;
VAL_ 321 VCU_APA_LC_FailureSts 7 "ParkAssist_WithError" 6 "ParkAssist_Reserved" 5 "ParkAssist_Unexpected_GearIntervention" 4 "ParkAssist_Unexpected_Brake" 3 "ParkAssist_Unexpected_EPB_Action" 2 "ParkAssist_Unexpected_GearPosition" 1 "ParkAssist_Vehicle_block" 0 "ParkAssist_NoError" ;
VAL_ 321 VCU_E_Pedalwarn 1 "active" 0 "no active" ;
VAL_ 321 VCU_ChargeDepthwarn 1 "active" 0 "no active" ;
VAL_ 321 VCU_EPB_FunctionSet 3 "Reserved" 2 "拉起" 1 "释放" 0 "Default" ;
VAL_ 321 VCU_APA_LC_Status 10 "LongCtrl_Error" 9 "LongCtrl_Active_ManeuverAccelerationAvoidance" 8 "LongCtrl_Active_ManeuverComfortBrake" 7 "LongCtrl_Active_ManeuverEmergencyBrake" 6 "LongCtrl_Active_RemoteParkOut" 5 "LongCtrl_Active_RemoteParkIn" 4 "LongCtrl_Active_AutomaticPark" 3 "LongCtrl_Active_ParkEmergencyBrake" 2 "LongCtrl_Active_ParkComfortBrake" 1 "LongCtrl_Standby" 0 "LongCtrl_Off" ;
VAL_ 336 VCU_GearLeverPos 7 "Invalid" 6 "Reserved" 5 "Reserved" 4 "Reserved" 3 "D" 2 "N" 1 "R" 0 "P" ;
VAL_ 336 VCU_TortoiseLamp 1 "on" 0 "off" ;
VAL_ 336 VCU_Charge_Connect 3 "异常插枪" 2 "直流枪插入" 1 "交流枪插入" 0 "未插枪" ;
VAL_ 336 VCU_12VbatteryError 1 "Fault" 0 "No Fault" ;
VAL_ 336 VCU_ReadySts 1 "Ready" 0 "Not Ready" ;
VAL_ 336 VCU_MotorPumpError 1 "水泵故障" 0 "水泵无故障" ;
VAL_ 336 VCU_VacuumSysFaultLamp 1 "on" 0 "off" ;
VAL_ 336 VCU_GearP_EnterWarning 1 "on" 0 "off" ;
VAL_ 336 VCU_VehicleSysFaultLamp 1 "Fault" 0 "No Fault" ;
VAL_ 336 VCU_BattPumpError 1 "水泵故障" 0 "水泵无故障" ;
VAL_ 336 VCU_DriveableAlarm 1 "Active" 0 "NotActive" ;
VAL_ 336 VCU_GearFlashReq 3 "Reserved" 2 "request from EPB" 1 "request from SCM" 0 "No request" ;
VAL_ 336 VCU_ShowCarMod 1 "Active" 0 "Inactive" ;
VAL_ 336 VCU_Mileage 1023 "Invalid" ;
VAL_ 336 VCU_PowerConsumption 511 "Invalid" ;
VAL_ 336 VCU_MotorLoopCoolantLow 1 "Fault" 0 "No Fault" ;
VAL_ 336 VCU_BatLoopCoolantLow 1 "Fault" 0 "No Fault" ;
VAL_ 336 VCU_ChargeDepthSts 3 "预留" 2 "预留" 1 "长途旅行" 0 "日常行驶" ;
VAL_ 336 VCU_CloolantHighAlarm 1 "Alarm" 0 "Not Alarm" ;
VAL_ 336 VCU_TBOX_SlowChargeSt 15 "预留" 14 "预留" 13 "预留" 12 "预留" 11 "预留" 10 "预留" 9 "启动中" 8 "电源档位不正确" 7 "未插枪" 6 "其他故障" 5 "启动太频繁" 4 "充电设备不满足充电条件" 3 "已充满" 2 "高压系统故障" 1 "正在充电" 0 "未充电" ;
VAL_ 337 VCU_HVLock_ALL 3 "预留" 2 "高压断开" 1 "高压闭合" 0 "未检测" ;
VAL_ 337 VCU_BrakeLampReq 1 "on" 0 "off" ;
VAL_ 337 VCU_Intelligent_Charge_Sts 1 "开启" 0 "关闭" ;
VAL_ 337 VCU_HVLock_self 3 "预留" 2 "高压断开" 1 "高压闭合" 0 "未检测" ;
VAL_ 337 VCU_MotorPump_ErrorSts 7 "Reserved" 6 "空转" 5 "过压" 4 "过温" 3 "低压" 2 "过流" 1 "堵转" 0 "正常" ;
VAL_ 337 VCU_BrkSw_Sts 3 "Invalid" 2 "Reserved" 1 "Pressed" 0 "NotPressed" ;
VAL_ 337 VCU_BrkPed_Pos 255 "Invalid" ;
VAL_ 337 VCU_AtmosphePressValue 63 "Invalid" ;
VAL_ 337 VCU_AccSW_Sts 3 "Invalid" 2 "reserved" 1 "pressed" 0 "not pressed" ;
VAL_ 337 VCU_AccPedPos 255 "Invalid" ;
VAL_ 337 VCU_TargetGear 7 "Invalid" 6 "Reserved" 5 "Reserved" 4 "Reserved" 3 "D" 2 "N" 1 "R" 0 "P" ;
VAL_ 337 VCU_APS_WorkStatus 22 "预留故障1" 21 "APS通讯故障" 20 "动力系统故障" 19 "人为介入停止" 18 "EPB释放超时" 17 "EPB故障" 16 "MCU反馈转速模式超时" 15 "分配给电机的功率不满足" 14 "车速不满足" 13 "MCU工作状态不满足" 12 "整车电源档位不满足" 11 "不在P档" 10 "VCU检测坡度不满足" 7 "正在脱手（由APS发起）" 6 "已激活状态:暂停" 5 "已激活状态:后退" 4 "已激活状态:前进" 3 "已激活状态:停止" 2 "正在握手" 1 "Standby待机状态" 0 "Init" ;
VAL_ 401 APS_SystemSts 7 "Invalid" 6 "Terminated" 5 "Failure" 4 "Completed" 3 "Guidance active" 2 "Searching" 1 "Standby" 0 "Off" ;
VAL_ 401 APS_Active 1 "Active" 0 "Not active" ;
VAL_ 401 APS_VCU_BrakeFunctionMode 15 "reserved" 14 "reserved" 13 "reserved" 12 "reserved" 11 "reserved" 10 "reserved" 9 "reserved" 8 "ParkAssist_ManeuverAccelerationAvoidance" 7 "ParkAssist_ManeuverComfortBrake" 6 "ParkAssist_ManeuverEmergencyBrake" 5 "预留" 4 "预留" 3 "ParkAssist_AutomaticPark" 2 "ParkAssist_ParkEmergencyBrake" 1 "ParkAssist_ParkComfortBrake" 0 "ParkAssist_NoSignal" ;
VAL_ 401 APS_AVM_HU_Failure 1 "failure" 0 "Not failure" ;
VAL_ 401 APS_VCU_BrakeModeSts 7 "reserved" 6 "reserved" 5 "ParkAssist_Abort" 4 "ParkAssist_Suspend" 3 "ParkAssist_ManeuverFinished" 2 "ParkAssist_Active" 1 "ParkAssist_Standby" 0 "ParkAssist_Int" ;
VAL_ 401 APS_VCU_Target_Gear_Request 7 "Reserved" 6 "Reserved" 5 "Reserved" 4 "APADrvDirRqVCU_DRIVE" 3 "APADrvDirRqVCU_NEUTRAL" 2 "APADrvDirRqVCU_Reverse" 1 "APADrvDirRqVCU_Park" 0 "APADrvDirRqVCU_Idle" ;
VAL_ 401 AVM_ControlRequest 7 "Reserved" 6 "Reserved" 5 "AVM Exit Request by R gear" 4 "AVM Exit Request by overspeed" 3 "AVM Exit Request by hard switch" 2 "AVM Enter Request by R gear" 1 "AVM Enter Request by hard switch" 0 "No Request" ;
VAL_ 401 APS_HU_ParkPrompttone 1 "Active" 0 "Not active" ;
VAL_ 401 APS_VCU_APAFailed 1 "APA Failure" 0 "Normal" ;
VAL_ 401 AVM_SoftKeyResponse 1 "AVM Exit Response" 0 "AVM Enter Response" ;
VAL_ 401 AVM_FactoryMode 1 "Factory_Mode" 0 "Normal_Mode" ;
VAL_ 401 APS_ParkOutDirection 3 "Reserved" 2 "Riht" 1 "Left" 0 "Default" ;
VAL_ 401 APS_TBOXConect_ParkInResp 3 "Reserved" 2 "蓝牙已连接反馈" 1 "蓝牙未连接反馈" 0 "Default" ;
VAL_ 401 APS_VCU_FailureBrakeMode 3 "ParkAssist_ Emergency" 2 "ParkAssist_Comfort" 1 "ParkAssist_Idle" 0 "ParkAssist_NoFailure" ;
VAL_ 401 APS_R_Gear_RequestTips 3 "Reserved" 2 "RequestTips" 1 "NoRequestTips" 0 "Default" ;
VAL_ 401 APS_VCU_Req_StraightOut 0 "NoRequest                                            0x1: RequestStraightOut" ;
VAL_ 401 APS_VCU_Gear_Request 7 "reserved" 6 "reserved" 5 "reserved" 4 "APADrvDirRqVCU_Drive" 3 "APADrvDirRqVCU_Neutral" 2 "APADrvDirRqVCU_Reverse" 1 "APADrvDirRqVCU_Park" 0 "APADrvDirRqVCU_Idle" ;
VAL_ 401 APS_VCU_Req_StraightCtrol 2 "后退                               0x3:Reserved" 1 "前进" 0 "停止" ;
VAL_ 401 APS_TBOX_PowerOffResp 3 "Reserved" 2 "下电成功" 1 "未下电成功" 0 "Default" ;
VAL_ 401 APS_TBOX_PowerOffReqResp 3 "Reserved" 2 "响应APP的下电请求并准备下电" 1 "未响应APP的下电请求" 0 "Default" ;
VAL_ 624 APS_APAFailed 1 "APA Failure" 0 "Normal" ;
VAL_ 624 APS_CmdEPSSts 3 "Reserved" 2 "EPS control active" 1 "Control EPS request" 0 "No request" ;
VAL_ 624 APS_FailureBrakeMode 3 "ParkAssist_ Emergency" 2 "ParkAssist_Comfort" 1 "ParkAssist_Idle" 0 "ParkAssist_NoFailure" ;
VAL_ 624 APS_BrakeModeSts 7 "reserved" 6 "reserved" 5 ":ParkAssist_Abort" 4 "ParkAssist_Suspend" 3 "ParkAssist_ManeuverFinished" 2 "ParkAssist_Active" 1 "ParkAssist_Standby" 0 "ParkAssist_Int" ;
VAL_ 624 APS_BrakeFunctionMode 15 "reserved" 14 "reserved" 13 "reserved" 12 "reserved" 11 "reserved" 10 "reserved" 9 "reserved" 8 "ParkAssist_ManeuverAccelerationAvoidance" 7 "ParkAssist_ManeuverComfortBrake" 6 "ParkAssist_ManeuverEmergencyBrake" 5 "ParkAssist_RemoteParkOut" 4 "ParkAssist_RemoteParkOut" 3 "ParkAssist_AutomaticPark" 2 "ParkAssist_ParkEmergencyBrake" 1 "ParkAssist_ParkComfortBrake" 0 "ParkAssist_NoSignal" ;
VAL_ 624 APS_ESC_Target_Gear_Request 4 "APADrvDirRqESP_DRIVE" 3 "APADrvDirRqESP_NEUTRAL" 2 "APADrvDirRqESP_Reverse" 1 "APADrvDirRqESP_Park" 0 "APADrvDirRqESP_Idle" ;
VAL_ 625 APS_AVM_AutoSearchSts 7 "reserved" 6 "reserved" 5 "wait for vehicle driver confirm park 提示用户松开转向，刹车，开始泊车" 4 "Confirm the model 选择模式" 3 "wait for vehicle slow down   提示用户减速" 2 "waiting for vehicle stop   找到车位，提示用户停车" 1 "slot searching      寻址车位中" 0 "not in search mode" ;
VAL_ 625 APS_AVM_ParkOutChkResult 1 "OK" 0 "NOK" ;
VAL_ 625 APS_AVM_SuspendedReason 7 "EPB locked" 6 "seat belt released" 5 "mirror fold" 4 "trunk open" 3 "any door open" 2 "obstacle on path" 1 "VoiceSuspended" 0 "not suspended" ;
VAL_ 625 APS_AVM_AbortReason 31 "Reserved" 30 "Reserved" 29 "Reserved" 28 "Reserved" 27 "Reserved" 26 "Interrupt number over threshold" 25 "Current step number over threshold" 24 "APS time out" 23 "Vehicle speed over threshold" 22 "vehicle driver mode" 21 "ACC or ICC active" 20 "ESC active (ABS, TCS, ESP)" 19 "SAS not calibrated" 18 "invalid lateral accel signal" 17 "invalid longi accel signal" 16 "invalid yaw rate signal" 15 "invalid brake pedal switch state 预留" 14 "invalid vehicle speed" 13 "invalid wheel pulse counter signal" 12 "invalid wheel speed signal" 11 "invalid accel pedal position 预留" 10 "engine off  预留" 9 "APS internal failure (ECU hw)" 8 "VoiceExit" 7 "SAS failure" 6 "EMS failure  预留" 5 "PAS failure  预留" 4 "ACU failure 预留" 3 "TCU failure 预留" 2 "ESC failure" 1 "EPS failure" 0 "No fault" ;
VAL_ 625 APS_AVM_CurrentParkType 7 "reserved" 6 "reserved" 5 "reserved" 4 "mechanical garage" 3 "diagonal" 2 "parallel" 1 "perpendicular" 0 "not selected" ;
VAL_ 625 APS_AVM_OverrideReason 7 "Reserved" 6 "Reserved" 5 "Reserved" 4 "Overrode by EPB" 3 "overrode by gear shift" 2 "overrode by vehicle speed" 1 "overrode by steer" 0 "not overrode" ;
VAL_ 625 APS_AVM_VehicleDirection 3 "reserved" 2 "backward" 1 "forward" 0 "stopped" ;
VAL_ 625 APS_AVM_TerminatedType 3 "abort" 2 "suspended" 1 "driver override" 0 "not Terminated" ;
VAL_ 625 APS_AVM_ParkOutSystemStatus 1 "Normal" 0 "Judging" ;
VAL_ 625 APS_RemoteParkIn_Status 7 "RemoteParkOut_Error  由于HU TBOX产生的故障  具体故障见APS_RemotePark_Error_Status" 6 "RemoteParkIn_Exit  非HU TBOX原因导致的退出  具体故障见APS_AVM_AbortReason" 5 "RemoteParkIn_Complete" 4 "RemoteParkIn_Suspended  泊车按键松开暂停  其他暂停原因见APS_AVM_SuspendedReason" 3 "RemoteParkIn_Parking" 2 "RemoteParkIn_Start" 1 "Standy" 0 "Default" ;
VAL_ 625 APS_RemoteParkInResp 1 "Active" 0 "NoActive" ;
VAL_ 625 APS_BCM_RemoteParkIn_Status 1 "Active" 0 "NoActive" ;
VAL_ 625 APS_BCM_DoubleFlash 1 "Active" 0 "default" ;
VAL_ 625 APS_BCM_AllDoorUnLock_Door 1 "Active" 0 "default" ;
VAL_ 625 APS_RemoteParkOutResp 1 "Active" 0 "NoActive" ;
VAL_ 625 APS_BCM_PowerOffReq 1 "请求BCM下电" 0 "Default" ;
VAL_ 625 APS_RemotePark_Error_Status 7 "Reserved" 6 "RemoteParkOut_APS_TBOX_Start_TimeOut" 5 "RemoteParkOut_APS_TBOX_Request_Timeout" 4 "RemoteParkIn_APS_TBOX_Start_TimeOut" 3 "RemoteParkIn_APS_TBOX_Request_Timeout" 2 "RemoteParkIn_APS_TBOXConnectAPP_Timeout" 1 "RemoteParkIn_APS_HU_Request_Timeout" 0 "Default" ;
VAL_ 625 APS_APP_StraightOut_Status 9 "APS故障退出" 8 "EPS故障退出握手" 7 "VCU相关故障退出握手" 6 "暂停(松开前进后退左转右转)" 5 "右转中" 4 "左转中" 3 "后退中" 2 "前进中" 1 "与VCU EPS握手成功" 0 "standy" ;
VAL_ 920 ORM_LeftMirrorMotor1fault 1 "fault" 0 "no fault" ;
VAL_ 920 ORM_LeftMirrorMotor2fault 1 "fault" 0 "no fault" ;
VAL_ 920 ORM_RightMirrorMotor1fault 1 "fault" 0 "no fault" ;
VAL_ 920 ORM_RightMirrorMotor2fault 1 "fault" 0 "no fault" ;
VAL_ 800 EAC_StartSts_F 1 "Error" 0 "No Error" ;
VAL_ 800 EAC_UnderVoltage_F 1 "Error" 0 "No Error" ;
VAL_ 800 EAC_OverVoltage_F 1 "Error" 0 "No Error" ;
VAL_ 800 EAC_OverCurrent_F 1 "Error" 0 "No Error" ;
VAL_ 800 EAC_OverTemp_F 1 "Error" 0 "No Error" ;
VAL_ 800 EAC_Status 3 "System fault" 2 "Active" 1 "Not active" 0 "initi" ;
VAL_ 800 EAC_StandbyUnderVol_F 1 "Error" 0 "No Error" ;
VAL_ 800 EAC_StandbyOverVol_F 1 "Error" 0 "No Error" ;
VAL_ 800 EAC_Communication_Error 1 "Error" 0 "No Error" ;
VAL_ 800 EAC_OverCurrentDropFreq 1 "Active" 0 "Not active" ;
VAL_ 800 EAC_OverPeakCurrent 1 "Active" 0 "Not active" ;
VAL_ 806 APTC_WorkSts 3 "Reserved" 2 "System fault" 1 "运行" 0 "关闭" ;
VAL_ 806 APTC_ErrorCode 15 "Reserved" 14 "Reserved" 13 "Reserved" 12 "Reserved" 11 "接收的PWM值不在0-100范围" 10 "CAN接收超时" 9 "PTC短路" 8 "PCB板温度高" 7 "干烧" 6 "PTC表面温度高" 5 "过流" 4 "PCB板NTC坏" 3 "PTC NTC坏" 2 "PTC电流小(持续2S)" 1 "IGBT短路" 0 "无故障" ;
VAL_ 806 APTC_HVSts 7 "Reserved" 6 "Reserved" 5 "Reserved" 4 "高压反接" 3 "高压欠压故障" 2 "高压过压故障" 1 "已供电" 0 "未供电" ;
VAL_ 806 APTC_ErrorLevel 3 "Level_3" 2 "Level_2" 1 "Level_1" 0 "No Error" ;
VAL_ 735 HU_SetMemoryReq 15 "Reserved" 14 "Reserved" 13 "Reserved" 12 "Reserved" 11 "无需记忆" 10 "10 Position(对应ID10)" 9 "9 Position(对应ID9)" 8 "8 Position(对应ID8)" 7 "7 Position(对应ID7)" 6 "6 Position(对应ID6)" 5 "5 Position(对应ID5)" 4 "4 Position(对应ID4)" 3 "3 Position(对应ID3)" 2 "2 Position(对应ID2)" 1 "1 Position(对应ID1)" 0 "No request" ;
VAL_ 735 HU_DeleteMemoryReq 15 "Reserved" 14 "Reserved" 13 "Reserved" 12 "Reserved" 11 "Reserved" 10 "10 Position(对应ID10)删除" 9 "9 Position(对应ID9)删除" 8 "8 Position(对应ID8)删除" 7 "7 Position(对应ID7)删除" 6 "6 Position(对应ID6)删除" 5 "5 Position(对应ID5) 删除" 4 "4 Position(对应ID4)删除" 3 "3 Position(对应ID3) 删除" 2 "2 Position(对应ID2)删除" 1 "1 Position(对应ID1)删除" 0 "No request" ;
VAL_ 735 HU_GetMemoryReq 15 "Reserved" 14 "Reserved" 13 "Reserved" 12 "Stop Move" 11 "Last position" 10 "10 Position(对应ID10)" 9 "9 Position(对应ID9)" 8 "8 Position(对应ID8)" 7 "7 Position(对应ID7)" 6 "6 Position(对应ID6)" 5 "5 Position(对应ID5)" 4 "4 Position (对应ID4)" 3 "3 Position  (对应ID3)" 2 "2 Position(对应ID2)" 1 "1 Position (对应ID1)" 0 "No request" ;
VAL_ 735 HU_DirverSLV_Direction_set 3 "default" 2 "Back" 1 "Forward" 0 "Stop" ;
VAL_ 735 HU_DirverSHV_Direction_set 3 "default" 2 "Down" 1 "Up" 0 "Stop" ;
VAL_ 735 HU_DirverLNV_Direction_set 3 "default" 2 "Back" 1 "Forward" 0 "Stop" ;
VAL_ 735 HU_PassagerSLV_Direction_set 3 "default" 2 "Back" 1 "Forward" 0 "Stop" ;
VAL_ 735 HU_PassagerSHV_Direction_set 3 "Default" 2 "Down" 1 "Up" 0 "Stop" ;
VAL_ 735 HU_PassagerLNV_Direction_set 3 "Default" 2 "Back" 1 "Forward" 0 "Stop" ;
VAL_ 735 HU_DSM_heatSwitch 3 "Invalid" 2 "on" 1 "off" 0 "default" ;
VAL_ 735 HU_DSM_Targtemp 63 "default" ;
VAL_ 735 HU_PSM_heatSwitch 3 "Invalid" 2 "on" 1 "off" 0 "default" ;
VAL_ 735 HU_PSM_Targtemp 63 "default" ;
VAL_ 735 HU_DSMEasyEntrySW 3 "Invalid" 2 "on" 1 "off" 0 "default" ;
VAL_ 735 HU_RVMAutoFoldSW 3 "Reserved" 2 "关" 1 "开" 0 "Default" ;
VAL_ 735 HU_RVMFoldButton 3 "Reserved" 2 "展开" 1 "折叠" 0 "Default" ;
VAL_ 735 HU_RVM_R_DownSW 3 "Reserved" 2 "Enable" 1 "Disable" 0 "Default" ;
VAL_ 735 HU_Userdefined_Mirror 7 "Reserved" 6 "Reserved" 5 "Reserved" 4 "Reserved" 3 "Reserved" 2 "后视镜退出" 1 "后视镜控制" 0 "default" ;
VAL_ 928 ICM_ODOTotal 16777215 "Invalid" ;
VAL_ 928 ICM_DisPlayVehicleSpeed 4095 "Invalid" ;
VAL_ 928 ICM_LowBrakeFluidLevel 1 "Low" 0 "normal" ;
VAL_ 928 ICM_WashingLiquidLevel 1 "Low" 0 "normal" ;
VAL_ 928 ICM_maintenanceState 1 "需保养" 0 "无需保养" ;
VAL_ 928 ICM_INFO_Enablests 1 "ON" 0 "OFF" ;
VAL_ 928 ICM_ODOTotalFB 3 "Invalid" 2 "处理失败" 1 "处理成功" 0 "Default" ;
VAL_ 928 ICM_Error_Sts 3 "Invalid" 2 "Error" 1 "No Error" 0 "Default" ;
VAL_ 928 ICM_PrevmaintmileagesFB 3 "Invalid" 2 "处理失败" 1 "处理成功" 0 "Default" ;
VAL_ 928 ICM_Display_Mode 3 "Night" 2 "Day" 1 "Auto" 0 "Default" ;
VAL_ 928 ICM_SubMileage_Reset 1 "Reset" 0 "default" ;
VAL_ 896 SRF_MD1_Position 127 "No position is known" ;
VAL_ 896 SRF_MD1_Lage 1 "Slide/平移位置" 0 "Tilt/起翘位置" ;
VAL_ 896 SRF_MD1_Sleflearnsuccessfully 1 "initialization/MD1初始化完成" 0 "non-initialization/MD1未初始化" ;
VAL_ 896 SRF_MD1_FunctionAbort 1 "aktiv/功能中断" 0 "inaktiv/正常" ;
VAL_ 896 SRF_MD1_drive_detect 1 "error/驱动器故障" 0 "normal/正常" ;
VAL_ 896 SRF_MD1_ResponseError 1 "error/响应故障" 0 "normal/正常" ;
VAL_ 896 SRF_RoofRunningStatus 3 "Reserved" 2 "motor is closing" 1 "motor is opening" 0 "motor is not running" ;
VAL_ 896 RLS_RQ_LowBeam 1 "RQ on Low Beam" 0 "No RQ on Low Beam" ;
VAL_ 896 RLS_RQ_PositionLamp 1 "RQ on Position Lamp" 0 "No RQ on Position Lamp" ;
VAL_ 896 SHD_MRollo_FunctionAbort 1 "aktiv/功能中断" 0 "inaktiv/正常" ;
VAL_ 896 SHD_MRollo_Driver_detect 1 "error/驱动器故障" 0 "normal/正常" ;
VAL_ 896 SHD_MRollo_ResponseError 1 "error/响应故障" 0 "normal/正常" ;
VAL_ 896 SHD_ShadeRunningStatus 3 "Reserved" 2 "motor is closing" 1 "motor is opening" 0 "motor is not running" ;
VAL_ 896 SHD_ShadePosReached 3 "Reserved" 2 "Shade Reached position C" 1 "Shade Reached position B" 0 "Shade Position less than Position B" ;
VAL_ 896 RLS_Fault_Rain 1 "Status Fault" 0 "Normal Status" ;
VAL_ 896 SHD_MRollo_Position 127 "No position is known" ;
VAL_ 896 SHD_MRollo_Sleflearnsuccessfully 1 "initialization/MR初始化完成" 0 "non-initialization/MR未初始化" ;
VAL_ 896 RLS_Fault_Light 1 "Status Fault" 0 "Normal Status" ;
VAL_ 896 RLS_ResponseError 1 "Error" 0 "No error" ;
VAL_ 784 BCM_SystemPowerMode 3 "ready" 2 "ON" 1 "ACC" 0 "OFF" ;
VAL_ 784 BCM_AntiThelf_Sts 3 "Warning" 2 "Prearm" 1 "Arm(armed || partial armed)" 0 "Disarm" ;
VAL_ 784 BCM_DriverLock_Sts 3 "Invalid" 2 "Lock" 1 "Unlock" 0 "Default" ;
VAL_ 784 BCM_StartRequest 1 "Request" 0 "No Request" ;
VAL_ 784 BCM_partialarmed_ActiveSts 1 "active" 0 "Inactive" ;
VAL_ 784 BCM_Hood_Sts 3 "Invalid" 2 "Close" 1 "Open" 0 "Default" ;
VAL_ 784 BCM_ChargerLock_ControlSts 1 "active" 0 "Not active" ;
VAL_ 784 BCM_PositionLight_Sts 1 "ON" 0 "OFF" ;
VAL_ 784 BCM_TurnLeftLight_Sts 1 "ON" 0 "OFF" ;
VAL_ 784 BCM_TurnRightLight_Sts 1 "ON" 0 "OFF" ;
VAL_ 784 BCM_Daylight_Sts 1 "ON" 0 "OFF" ;
VAL_ 784 BCM_HighBeam_Sts 1 "ON" 0 "OFF" ;
VAL_ 784 BCM_LowBeam_Sts 1 "ON" 0 "OFF" ;
VAL_ 784 BCM_AutoHeadlight_Sts 1 "active" 0 "inactive" ;
VAL_ 784 BCM_brakeLight_Sts 1 "ON" 0 "OFF" ;
VAL_ 784 BCM_HazardLight_Sts 1 "ON" 0 "OFF" ;
VAL_ 784 BCM_RearFoglight_Sts 1 "ON" 0 "OFF" ;
VAL_ 784 BCM_BrkSw_Sts 3 "Invalid" 2 "Reserved" 1 "Pressed" 0 "NotPressed" ;
VAL_ 784 BCM_FL_Door_Sts 3 "Invalid" 2 "Close" 1 "Open" 0 "Default" ;
VAL_ 784 BCM_FR_Door_Sts 3 "Invalid" 2 "Close" 1 "Open" 0 "Default" ;
VAL_ 784 BCM_RL_Door_Sts 3 "Invalid" 2 "Close" 1 "Open" 0 "Default" ;
VAL_ 784 BCM_RR_Door_Sts 3 "Invalid" 2 "Close" 1 "Open" 0 "Default" ;
VAL_ 784 BCM_Trunk_Door_Sts 3 "Invalid" 2 "Close" 1 "Open" 0 "Default" ;
VAL_ 784 BCM_PLGOutsideSW 1 "active" 0 "inactive" ;
VAL_ 784 BCM_HornControlsts 1 "active" 0 "inactive" ;
VAL_ 784 BCM_Fwiper_Mist_Sts 1 "ON" 0 "OFF" ;
VAL_ 784 BCM_Fwiper_washing_Sts 1 "ON" 0 "OFF" ;
VAL_ 784 BCM_RKE_lock_Unlock_req 3 "Invalid" 2 "PEPS RKE UnLock Req" 1 "PEPS RKE lock Req" 0 "Default" ;
VAL_ 784 BCM_FWiper_Sts 7 "Invalid" 6 "Reserved" 5 "Reserved" 4 "Maintenance Mode" 3 "Reserved" 2 "HS Speed" 1 "LS speed" 0 "OFF" ;
VAL_ 784 BCM_RWiper_Sts 3 "Invalid" 2 "Rear Washer" 1 "Rear Wiper ON" 0 "OFF" ;
VAL_ 784 BCM_RearViewFoldSts 1 "展开" 0 "折叠" ;
VAL_ 784 BCM_RearViewAutoSWSts 1 "手动" 0 "auto" ;
VAL_ 784 BCM_RearViewHeatSts 1 "active" 0 "inactive" ;
VAL_ 784 BCM_WorkMode 3 "存储模式" 2 "运输模式" 1 "生产模式" 0 "正常模式" ;
VAL_ 784 BCM_TBOXUnlockEnableSts 1 "enable" 0 "disable" ;
VAL_ 784 BCM_FwiperServiceSWsts 1 "on（进入维修模式）" 0 "off（退出维修模式）" ;
VAL_ 784 BCM_PowerONorOFF_Reason 9 "非off电状态-诊断2F服务请求上电" 8 "非off电状态-TBOX请求上电" 7 "非off电状态-SSB触发上电" 6 "off电状态-ACC档无操作超时1小时后下电" 5 "预留" 4 "off电状态-诊断11服务控制下电" 3 "off电状态-诊断2F服务控制下电" 2 "off电状态-APS请求下电" 1 "off电状态-SSB长按触发下电" 0 "off电状态-SSB短按触发下电" ;
VAL_ 784 BCM_SupplyVoltage 255 "Invalid" ;
